VERSION ""

NS_ :

BS_:

BU_: CHUD_LS VKM_LS RCRM_LS MSM_RR_LS MSM_LR_LS CGM_LS BSM_LS VPM_LS ISRVM_LS DCAC_LS TouchPad_LS RSC_LS LVMPC_LS EOCM2B_K1_LS EOCM2A_K1_LS LCM_LS TIM_B_LS V2V_LS TCP_LS CSM_LS EOCM2B_K2_LS EOCM2A_K2_LS TIM_A_LS LVMNav_LS HFP_LS EDI_LS ARB_LS RSE_LS Dummy_LS VIS2_LS ICS_LS FCM_LS EOCM_F_LS VICM_LS AGC_LS MSM_P_LS OTIM_LS HVSM_R_LS HVSM_F_LS DVB_T_LS SBZA_R_LS PSD_R_LS PSD_L_LS UHP_Low UPA_LS STC_LS SBZA_L_LS PTM_LS ONSTAR_LS APA_LS TestTool_LS PHS_LS PDIM_LS CHM_LS RSA_LS AMP_LS HUD_LS MSM_LS HBSM_LS SCL_LS ECC_LS RadioHead_LS PEPS_LS IPC_LS AOS_LS SDM_LS TIM_LS BCM_LS
VAL_TABLE_ vt_BooleanValues 1 "true" 0 "false" ;
VAL_TABLE_ CrgBdVwLtCustSetReq 3 "Unused and Reserved" 2 "On" 1 "Off" 0 "No Action" ;
VAL_TABLE_ CrgBdVwLtCustSetVal 3 "Unused and Reserved" 2 "On" 1 "Off" 0 "Unknown" ;
VAL_TABLE_ TrlrMirVGlnCustSetReq 3 "Unused and Reserved" 2 "On" 1 "Off" 0 "No Action" ;
VAL_TABLE_ TrlrMirVGlnCustSetVal 3 "Unused and Reserved" 2 "On" 1 "Off" 0 "Unknown" ;
VAL_TABLE_ TrlrMirVEnCustSetReq 3 "Unused and Reserved" 2 "On" 1 "Off" 0 "No Action" ;
VAL_TABLE_ TrlrMirVEnCustSetVal 3 "Unused and Reserved" 2 "On" 1 "Off" 0 "Unknown" ;
VAL_TABLE_ EngAftrRnIndReq 7 "Unused and Reserved 3" 6 "Unused and Reserved 2" 5 "Unused and Reserved 1" 4 "Interrupted" 3 "Overheated" 2 "Idle Needed" 1 "No Indication" 0 "No Action" ;
VAL_TABLE_ TireRRIPrsStat 5 "High" 4 "Low Extended Mobility" 3 "Low" 2 "Low Service Now" 1 "Nominal" 0 "Unknown" ;
VAL_TABLE_ TireLRIPrsStat 5 "High" 4 "Low Extended Mobility" 3 "Low" 2 "Low Service Now" 1 "Nominal" 0 "Unknown" ;
VAL_TABLE_ PrkHtrOffTmM 1 "Use Data" 0 "Dont Use Data" ;
VAL_TABLE_ PrkHtrCoolntTempMsk 1 "Use Data" 0 "Don't Use Data" ;
VAL_TABLE_ PrkHtrActvTmM 1 "Use Data" 0 "Dont Use Data" ;
VAL_TABLE_ EmrgncyRspSysTyp 7 "Ununsed and Reserved 1" 6 "Generic" 5 "ERA" 4 "ChevyStar" 3 "eCall" 2 "Onstar" 1 "None" 0 "Unknown" ;
VAL_TABLE_ OBHVDCCCpltnTmDspFrmt 3 "Ununsed and Reserved 1" 2 "Display Remaining Minutes To Complete" 1 "Display Completion Time" 0 "No Action" ;
VAL_TABLE_ EleRngEstAdjStat 3 "Ununsed and Reserved 1" 2 "Decrease" 1 "Increase" 0 "No Action" ;
VAL_TABLE_ EleRngEstAdjCstStReq 3 "Unused and Reserved 1" 2 "On" 1 "Off" 0 "No Action" ;
VAL_TABLE_ EleRngEstAdjCstCurrStVal 3 "Unused and Reserved 1" 2 "On" 1 "Off" 0 "No Action" ;
VAL_TABLE_ WPRSCstStReq 7 "Unused and Reserved 5" 6 "Unused and Reserved 4" 5 "Unused and Reserved 3" 4 "Unused and Reserved 2" 3 "Unused and Reserved 1" 2 "On" 1 "Off" 0 "No Action" ;
VAL_TABLE_ WPRSCstCurrStVal 7 "Unused and Reserved 5" 6 "Unused and Reserved 4" 5 "Unused and Reserved 3" 4 "Unused and Reserved 2" 3 "Unused and Reserved 1" 2 "On" 1 "Off" 0 "No Action" ;
VAL_TABLE_ CntStckHMIRdy 3 "Unused and Reserved 1" 2 "HMI Not Ready" 1 "HMI Ready" 0 "No Action" ;
VAL_TABLE_ SrvcHghVltBatIndReq 3 "Unused and Reserved 1" 2 "No Restart" 1 "Shut Down Soon" 0 "No Indication" ;
VAL_TABLE_ CSRCR_Cmnd 7 "Unused And Reserved 5" 6 "Unused And Reserved 4" 5 "Unused And Reserved 3" 4 "Unused And Reserved 2" 3 "Unused And Reserved 1" 2 "Revoke All Certificates" 1 "Revoke Certificate" 0 "No Action" ;
VAL_TABLE_ CrShrngFbsEnblStat 3 "Fail" 2 "Enabled" 1 "Disabled" 0 "No Action" ;
VAL_TABLE_ CrShrngFbsEnblReq 7 "Unused And Reserved 5" 6 "Unused And Reserved 4" 5 "Unused And Reserved 3" 4 "Unused And Reserved 2" 3 "Return Status" 2 "Unused And Reserved 1" 1 "Disable Fobs" 0 "No Action" ;
VAL_TABLE_ CSPS_ConnStat 15 "Reject All Certificates" 14 "Incorrect Fleet ID" 13 "Send Intermediate Certificate" 12 "Send User Certificate" 11 "Send all Authentication Data" 10 "Invalid VIN" 9 "Intermediate Certificate Expired" 8 "Invalid Intermediate Certificate" 7 "Resrvation End Time Exceeded " 6 "Resrvtion Start Tim Not Achieved" 5 "Cert Revoked Via Mobile Device" 4 "Cert Revoked Via Telematics" 3 "Certificate Expired" 2 "Invalid Certificate" 1 "Valid Certificate" 0 "No Action" ;
VAL_TABLE_ CSPS_RspVerf 4 "Command Response Verification Not Successful" 3 "Command Response Verification Successful" 2 "Zone Response Verification Not Successful" 1 "Zone Response Verification Successful" 0 "No Action" ;
VAL_TABLE_ CrShrngVehChlngReq 1 "Request New  Challenge" 0 "No Action" ;
VAL_TABLE_ CrShrngRvkCertfctRsp 4 "No CertIDs Stored" 3 "CertID Not Matched" 2 "Revoke Certificate Successful" 1 "Write Failure" 0 "No Action" ;
VAL_TABLE_ CSZS_FrntCmptZnMbDevStat 1 "One Or More Mobile Devices Prsnt" 0 "No Mobile Device Present" ;
VAL_TABLE_ CSZS_RrCmptZnMbDevStat 1 "One Or More Mobile Devices Prsnt" 0 "No Mobile Device Present" ;
VAL_TABLE_ CSZS_FrntExtrZnMbDevStat 1 "One Or More Mobile Devices Prsnt" 0 "No Mobile Device Present" ;
VAL_TABLE_ CSZS_RrExtrZnMbDevStat 1 "One Or More Mobile Devices Prsnt" 0 "No Mobile Device Present" ;
VAL_TABLE_ CSZS_WlcmZnMbDevStat 1 "One Or More Mobile Devices Prsnt" 0 "No Mobile Device Present" ;
VAL_TABLE_ CSZS_IntrZnMbDevStat 3 "Three Mobile Devices Present" 2 "Two Mobile Devices Present" 1 "One Mobile Device Present" 0 "No Mobile Device Present" ;
VAL_TABLE_ CSZS_PassEntyZnMbDevStat 1 "One Or More Mobile Devices Prsnt" 0 "No Mobile Device Present" ;
VAL_TABLE_ CSZS_DrEntyZnMbDevStat 1 "One Or More Mobile Devices Prsnt" 0 "No Mobile Device Present" ;
VAL_TABLE_ CrShrngConnStat 3 "Terminate Connection" 2 "Ignore Connection" 1 "Valid Connection" 0 "No Action" ;
VAL_TABLE_ TrlrPrfDltn 5 "Profile 5 Deleted" 4 "Profile 4 Deleted" 3 "Profile 3 Deleted" 2 "Profile 2 Deleted" 1 "Profile 1 Deleted" 0 "No Profile Deleted" ;
VAL_TABLE_ TrlrProfSel 5 "Profile 5" 4 "Profile 4" 3 "Profile 3" 2 "Profile 2" 1 "Profile 1" 0 "Default Profile" ;
VAL_TABLE_ CrwlModeDndRsnIndReq 4 "Reduce Speed" 3 "Shift To 4 High" 2 "Brakes Overtemp" 1 "Unavailable" 0 "No Action" ;
VAL_TABLE_ TrlrLtngSeqStat 1 "On" 0 "Off" ;
VAL_TABLE_ TrlrLtngSeqReq 2 "On" 1 "Off" 0 "No Action" ;
VAL_TABLE_ RmtTrlrLtngSeqReq 2 "On" 1 "Off" 0 "No Action" ;
VAL_TABLE_ TrlrConnStat 1 "Connected" 0 "Not Connected" ;
VAL_TABLE_ ClmCntPrtyHtngRq 3 "HIGH" 2 "MEDIUM" 1 "LOW" 0 "NO ACTION" ;
VAL_TABLE_ RSIHMIAnmSt 7 "Unused and Reserved 3" 6 "Unused and Reserved 2" 5 "Unused and Reserved 1" 4 "Shutdown Play" 3 "Start Play" 2 "Welcome Play" 1 "Ready" 0 "Uninitialized" ;
VAL_TABLE_ RSIHMIAnmReq 7 "Unused and Reserved 3" 6 "Unused and Reserved 2" 5 "Unused and Reserved 1" 4 "Shutdown Play" 3 "Start Play" 2 "Welcome Play" 1 "Ready" 0 "Uninitialized" ;
VAL_TABLE_ EUSD_MsrmntUnit 3 "Unused and Reserved 1" 2 "Unitless Score" 1 "km" 0 "No Action" ;
VAL_TABLE_ AxlLcksVDA 1 "Virtual Device Available" 0 "Virtual Device Unavailable" ;
VAL_TABLE_ AxlLckUnavailIndReq 7 "Unused And Reserved 2" 6 "Unused And Reserved 1" 5 "Generic Unavailable" 4 "Not During Hill Decent" 3 "Speed Too High" 2 "Not In 4 WD Low" 1 "Rear Axle Not Locked" 0 "No Action" ;
VAL_TABLE_ HVBHmChrgTmDspStat 4 "Display Master Setting" 3 "Display Both Cord and Station" 2 "Display Charge Station Charge Value" 1 "Display Portable Cord Charge Value" 0 "No Action" ;
VAL_TABLE_ HVBHmChrgTmDspReq 4 "Display Master Setting" 3 "Display Both Cord and Station" 2 "Display Charge Station Charge Value" 1 "Display Portable Cord Charge Value" 0 "No Action" ;
VAL_TABLE_ HVBChrgTmDspStat 3 "Display Both Cord and Station" 2 "Display Charge Station Charge Value" 1 "Display Portable Cord Charge Value" 0 "No Action" ;
VAL_TABLE_ HVBChrgTmDspReq 3 "Display Both Cord and Station" 2 "Display Charge Station Charge Value" 1 "Display Portable Cord Charge Value" 0 "No Action" ;
VAL_TABLE_ HVBChrgOvrdBtnDspStat 2 "Do Not Display Charge Override Button" 1 "Display Charge Override Button" 0 "No Action" ;
VAL_TABLE_ HVBChrgOvrdBtnDspReq 2 "Do Not Display Charge Override Button" 1 "Display Charge Override Button" 0 "No Action" ;
VAL_TABLE_ HVBChrgLmtBtnDspStat 2 "Do Not Disp Charge Limit Button" 1 "Display Charge Limit Button" 0 "No Action" ;
VAL_TABLE_ HVBChrgLmtBtnDspReq 2 "Do Not Display Charge Limit Button" 1 "Display Charge Limit Button" 0 "No Action" ;
VAL_TABLE_ InstnsFlEcnHybOvrdReq 7 "Unused and Reserved 3" 6 "Unused and Reserved 2" 5 "Unused and Reserved 1" 4 "EV" 3 "Auto Stop" 2 "Max Fuel Economy" 1 "Min Fuel Economy" 0 "No Action" ;
VAL_TABLE_ FourWhlDrvIdReqExtRng 15 "Front Wheel Drive Mode Active" 14 "Front Wheel Drive Mode Pending" 13 "AWD Connected Mode Active" 12 "AWD Connected Mode Pending" 11 "Position Undetermined Active" 10 "Transfer Case Neutral Active" 9 "Transfer Case Neutral Pending" 8 "Four Wheel Drive Low Lock Active" 7 "Four Wheel Drive Low Lock Pending" 6 "Four Wheel Drive High Lock Active" 5 "Four Wheel Drive High Lock Pending" 4 "Four Wheel Drive High Auto Active" 3 "Four Wheel Drive High Auto Pending" 2 "Two Wheel Drive High Active" 1 "Two Wheel Drive High Pending" 0 "No Indication" ;
VAL_TABLE_ BrkPdLfSysDrvrRq 4 "Reset Rear" 3 "Reset Front" 2 "Enable" 1 "Disable" 0 "No Action" ;
VAL_TABLE_ BrkPdLfStatIndRq 5 "Service" 4 "Disabled" 3 "Change Now" 2 "Change Soon" 1 "Ok" 0 "Not Present" ;
VAL_TABLE_ BrkPdLfRrDstWrnIndRq 2 "Display Distance" 1 "Low" 0 "No Action" ;
VAL_TABLE_ BrkPdLfFrtDstWrnIndRq 2 "Display Distance" 1 "Low" 0 "No Action" ;
VAL_TABLE_ HVBatStrtTmDspFrmt 4 "Display Start Time On Cord And Station" 3 "Display Now On Cord And Station" 2 "Display Now On Station Only" 1 "Display Now On Cord Only" 0 "No Action" ;
VAL_TABLE_ SurdVwLightgCsSetReq 7 "Unused and Reserved 5" 6 "Unused and Reserved 4" 5 "Unused and Reserved 3" 4 "Unused and Reserved 2" 3 "Unused and Reserved 1" 2 "ON" 1 "OFF" 0 "No Action" ;
VAL_TABLE_ SurdVwLightgCsCurrSetVal 7 "Unused and Reserved 5" 6 "Unused and Reserved 4" 5 "Unused and Reserved 3" 4 "Unused and Reserved 2" 3 "Unused and Reserved 1" 2 "ON" 1 "OFF" 0 "No Action" ;
VAL_TABLE_ TODCTmpImdtOvrdReq 2 "Active" 1 "Inactive" 0 "No Action" ;
VAL_TABLE_ EngAirFltMonSt 7 "Unused and Reserved 3" 6 "Unused and Reserved 2" 5 "Unused and Reserved 1" 4 "Disabled" 3 "Fault Present" 2 "Replace Air Filter Now" 1 "Replace Air Filter Soon" 0 "Ok" ;
VAL_TABLE_ EngAirFltMonDrvrReq 3 "Reset" 2 "Disable" 1 "Enable" 0 "No Action" ;
VAL_TABLE_ RmClmCtrlSyncSetReq 2 "Dual Zone Climate Control" 1 "Single Zone Climate Control" 0 "No Action" ;
VAL_TABLE_ RmClmCtrlRtSTempStReq 38 "14 CELCIUS" 37 "14.5 CELCIUS" 36 "15 CELCIUS" 35 "15.5 CELCIUS" 34 "16 CELCIUS" 33 "HI" 32 "LO" 31 "31.5 CELCIUS" 30 "31 CELCIUS" 29 "30.5 CELCIUS" 28 "30 CELCIUS" 27 "29.5 CELCIUS" 26 "29 CELCIUS" 25 "28.5 CELCIUS" 24 "28 CELCIUS" 23 "27.5 CELCIUS" 22 "27 CELCIUS" 21 "26.5 CELCIUS" 20 "26 CELCIUS" 19 "25.5 CELCIUS" 18 "25 CELCIUS" 17 "24.5 CELCIUS" 16 "24 CELCIUS" 15 "23.5 CELCIUS" 14 "23 CELCIUS" 13 "22.5 CELCIUS" 12 "22 CELCIUS" 11 "21.5 CELCIUS" 10 "21 CELCIUS" 9 "20.5 CELCIUS" 8 "20 CELCIUS" 7 "19.5 CELCIUS" 6 "19 CELCIUS" 5 "18.5 CELCIUS" 4 "18 CELCIUS" 3 "17.5 CELCIUS" 2 "17 CELCIUS" 1 "16.5 CELCIUS" 0 "No Action" ;
VAL_TABLE_ RmClmCtrlRrDfgSetReq 2 "Inactive" 1 "Active" 0 "No Action" ;
VAL_TABLE_ RmClmCtrlRcrcSetReq 4 "Inactive" 3 "Auto Recirculation" 2 "Recirculation" 1 "Fresh" 0 "No Action" ;
VAL_TABLE_ RmClmCtrlLtSTempStReq 38 "14 CELCIUS" 37 "14.5 CELCIUS" 36 "15 CELCIUS" 35 "15.5 CELCIUS" 34 "16 CELCIUS" 33 "HI" 32 "LO" 31 "31.5 CELCIUS" 30 "31 CELCIUS" 29 "30.5 CELCIUS" 28 "30 CELCIUS" 27 "29.5 CELCIUS" 26 "29 CELCIUS" 25 "28.5 CELCIUS" 24 "28 CELCIUS" 23 "27.5 CELCIUS" 22 "27 CELCIUS" 21 "26.5 CELCIUS" 20 "26 CELCIUS" 19 "25.5 CELCIUS" 18 "25 CELCIUS" 17 "24.5 CELCIUS" 16 "24 CELCIUS" 15 "23.5 CELCIUS" 14 "23 CELCIUS" 13 "22.5 CELCIUS" 12 "22 CELCIUS" 11 "21.5 CELCIUS" 10 "21 CELCIUS" 9 "20.5 CELCIUS" 8 "20 CELCIUS" 7 "19.5 CELCIUS" 6 "19 CELCIUS" 5 "18.5 CELCIUS" 4 "18 CELCIUS" 3 "17.5 CELCIUS" 2 "17 CELCIUS" 1 "16.5 CELCIUS" 0 "No Action" ;
VAL_TABLE_ RmClmCtrlHMIActIndReq 1 "Active" 0 "Inactive" ;
VAL_TABLE_ RmClmCtrlFrntFanStReq 20 "AUTO" 19 "MAN 18" 18 "MAN 17" 17 "MAN 16" 16 "MAN 15" 15 "MAN 14" 14 "MAN 13" 13 "MAN 12" 12 "MAN 11" 11 "MAN 10" 10 "MAN 9" 9 "MAN 8" 8 "MAN 7" 7 "MAN 6" 6 "MAN 5" 5 "MAN 4" 4 "MAN 3" 3 "MAN 2" 2 "MAN 1" 1 "OFF" 0 "No Action" ;
VAL_TABLE_ RmClmCtrlFLAirDtStReq 15 "E TRI LEVEL" 14 "E PANEL" 13 "E DEFOG" 12 "E DEDFROST" 11 "TRI LEVEL" 10 "DEFOG" 9 "ECO" 8 "PURGE" 7 "AC" 6 "BI LEVEL" 5 "HEATER DEFROST" 4 "HEATER" 3 "DEFROST" 2 "AUTO" 1 "OFF" 0 "No Action" ;
VAL_TABLE_ RmClmCtrlClmModSetReq 8 "Comfort Heat" 7 "Comfort AC" 6 "Battery AC On" 5 "Auto" 4 "Active" 3 "Fan Only" 2 "Economy" 1 "Comfort" 0 "No Action" ;
VAL_TABLE_ RmClmCtrlACSetReq 6 "Battery AC On" 5 "ECO AC on" 4 "Comfort AC On" 3 "Auto AC On" 2 "Active" 1 "Inactive" 0 "No Action" ;
VAL_TABLE_ TnrFrqBndReq 15 "Unused and Reserved10" 14 "Unused and Reserved9" 13 "Unused and Reserved8" 12 "Unused and Reserved7" 11 "Unused and Reserved6" 10 "Unused and Reserved5" 9 "Unused and Reserved4" 8 "Unused and Reserved3" 7 "Unused and Reserved2" 6 "Unused and Reserved1" 5 "XM" 4 "DAB" 3 "FM" 2 "AM" 1 "Off" 0 "No Action" ;
VAL_TABLE_ AudSelctdSrcReq 31 "Unused and Reserved14" 30 "Unused and Reserved13" 29 "Unused and Reserved12" 28 "Unused and Reserved11" 27 "Unused and Reserved10" 26 "Unused and Reserved9" 25 "Unused and Reserved8" 24 "Unused and Reserved7" 23 "Unused and Reserved6" 22 "Unused and Reserved5" 21 "Unused and Reserved4" 20 "Unused and Reserved3" 19 "Unused and Reserved2" 18 "Unused and Reserved1" 17 "Android Auto" 16 "Apple CarPlay" 15 "SD" 14 "USB" 13 "RSI2" 12 "RSI1" 11 "Internet App Audio" 10 "LVM Stereo Audio" 9 "Audio Disk Player" 8 "AUX" 7 "Bluetooth" 6 "IPOD" 5 "MediaPlayer" 4 "DAB" 3 "XM" 2 "FM" 1 "AM" 0 "No Action" ;
VAL_TABLE_ FuelMdTrnstnIndReq 15 "Unused and Reserved 9" 14 "Unused and Reserved 8" 13 "Unused and Reserved 7" 12 "Unused and Reserved 6" 11 "Unused and Reserved 5" 10 "Unused and Reserved 4" 9 "Unused and Reserved 3" 8 "Unused and Reserved 2" 7 "Unused and Reserved 1" 6 "Indication 6" 5 "Indication 5" 4 "Indication 4" 3 "Indication 3" 2 "Indication 2" 1 "Indication 1" 0 "No Indication" ;
VAL_TABLE_ BiFuelRflGaslinIndReq 7 "Unused and Reserved 5" 6 "Unused and Reserved 4" 5 "Unused and Reserved 3" 4 "Unused and Reserved 2" 3 "Unused and Reserved 1" 2 "Indication 2" 1 "Indication 1" 0 "No Indication" ;
VAL_TABLE_ HtdFrntWSSt 1 "ON" 0 "OFF" ;
VAL_TABLE_ HtdFrntWSDispReq 2 "OFF" 1 "ON" 0 "No Action" ;
VAL_TABLE_ AutoThrmlStPassMdStRq 3 "Vent Cool" 2 "Back Only Heat" 1 "Seat Heat" 0 "OFF" ;
VAL_TABLE_ AutoThrmlStPasLvlStRq 5 "Level 5" 4 "Level 4" 3 "Level 3" 2 "Level 2" 1 "Level 1" 0 "OFF" ;
VAL_TABLE_ AutoThrmlStDrvMdStRq 3 "Vent Cool" 2 "Back Only Heat" 1 "Seat Heat" 0 "OFF" ;
VAL_TABLE_ AutoThrmlStDrvLvStRq 5 "Level 5" 4 "Level 4" 3 "Level 3" 2 "Level 2" 1 "Level 1" 0 "OFF" ;
VAL_TABLE_ RunBrdOpMdCstStReq 7 "Unused and Reserved 4" 6 "Unused and Reserved 3" 5 "Unused and Reserved 2" 4 "Unused and Reserved 1" 3 "Extended" 2 "On" 1 "Off" 0 "No Action" ;
VAL_TABLE_ RunBrdOpMdCstCurrStVal 7 "Unused and Reserved 4" 6 "Unused and Reserved 3" 5 "Unused and Reserved 2" 4 "Unused and Reserved 1" 3 "Extended" 2 "On" 1 "Off" 0 "No Action" ;
VAL_TABLE_ StTODChrgTmpOvrdRmt1 2 "Active" 1 "Inactive" 0 "No Action" ;
VAL_TABLE_ SmPhRmFunCstStReq 7 "Unused and Reserved 5" 6 "Unused and Reserved 4" 5 "Unused and Reserved 3" 4 "Unused and Reserved 2" 3 "Unused and Reserved 1" 2 "On" 1 "Off" 0 "No Action" ;
VAL_TABLE_ SmPhRmFunCstCurStVal 7 "Unused and Reserved 5" 6 "Unused and Reserved 4" 5 "Unused and Reserved 3" 4 "Unused and Reserved 2" 3 "Unused and Reserved 1" 2 "On" 1 "Off" 0 "No Action" ;
VAL_TABLE_ PrtyChrgRqRmt1 2 "Active" 1 "Inactive" 0 "No Action" ;
VAL_TABLE_ HVChgSyChgLvPfStRmt1 4 "Reduced Current Level 3" 3 "Reduced Current Level 2" 2 "Reduced Current Level 1" 1 "No Reduction" 0 "No Action" ;
VAL_TABLE_ HVBTBDCSRR1_DChSnSRq 3 "Yearly" 2 "Winter" 1 "Summer" 0 "No Action" ;
VAL_TABLE_ HVBTBDCSRR1_DChSlSRq 8 "Unused and Reserved 4" 7 "Departure Time 2 Invalid" 6 "Unused and Reserved 3" 5 "Departure Time 2" 4 "Unused and Reserved 2" 3 "Departure Time 1 Invalid" 2 "Unused and Reserved 1" 1 "Departure Time 1" 0 "No Action" ;
VAL_TABLE_ HVBTBDCSRR1_DChDStRq 10 "Sat and Sun Same" 9 "Mon To Fri Same" 8 "All Days Same" 7 "Saturday" 6 "Friday" 5 "Thursday" 4 "Wednsday" 3 "Tuesday" 2 "Monday" 1 "Sunday" 0 "No Action" ;
VAL_TABLE_ HVBatTmBsChgMdRqRmt1 3 "Rate Based Charge" 2 "Delayed Charge" 1 "Charge Now" 0 "No Action" ;
VAL_TABLE_ HtdStWhlInd 3 "High" 2 "Medium" 1 "Low" 0 "Off" ;
VAL_TABLE_ HtdStWhlCtrlSrc 1 "Remote Switch Control" 0 "Local Switch Control" ;
VAL_TABLE_ HtdStWhlCmd 3 "High" 2 "Medium" 1 "Low" 0 "Off" ;
VAL_TABLE_ SmrtHgBmAstCstSetReq 7 "Unused and Reserved 5" 6 "Unused and Reserved 4" 5 "Unused and Reserved 3" 4 "Unused and Reserved 2" 3 "Unused and Reserved 1" 2 "Adaptive High Beam" 1 "Auto High Beam" 0 "No Action" ;
VAL_TABLE_ SmrtHgBmAstCstCurrSetVal 7 "Unused and Reserved 5" 6 "Unused and Reserved 4" 5 "Unused and Reserved 3" 4 "Unused and Reserved 2" 3 "Unused and Reserved 1" 2 "Adaptive High Beam" 1 "Auto High Beam" 0 "No Action" ;
VAL_TABLE_ V2VTLI_TrfLghtMntngDirctn 1 "Horizontal" 0 "Vertical" ;
VAL_TABLE_ V2VTLI_TrfLghtValDirctn 3 "All direction" 2 "Right" 1 "Left" 0 "Straight" ;
VAL_TABLE_ V2VTLI_TrfLghtPhsArivl 3 "Unknown Phase" 2 "Yellow" 1 "Green" 0 "Red" ;
VAL_TABLE_ V2VTLI_TrfLghtActlPhs 3 "Unknown Phase" 2 "Yellow" 1 "Green" 0 "Red" ;
VAL_TABLE_ RrStRmndrCstSetReq 2 "On" 1 "Off" 0 "No Action" ;
VAL_TABLE_ RrStRmndrCstCurrSetVal 2 "On" 1 "Off" 0 "No Action" ;
VAL_TABLE_ ElcShfPriTwoGrsSlInRq 3 "Drive Indication" 2 "Neutral Indication" 1 "Park Indication" 0 "No Indication" ;
VAL_TABLE_ VehStbEnhmntCurStRq 2 "On" 1 "Off" 0 "No Action" ;
VAL_TABLE_ VehStbEnhmntCurSt 1 "On" 0 "Off" ;
VAL_TABLE_ VehStbCmptvMdCurStRq 2 "On" 1 "Off" 0 "No Action" ;
VAL_TABLE_ VehStbCmptvMdCurSt 1 "On" 0 "Off" ;
VAL_TABLE_ TracAndStbScrnCnfg 3 "TCS ESC and Comp" 2 "TCS and ESC" 1 "TCS Only" 0 "None" ;
VAL_TABLE_ TCSysCurStReq 2 "On" 1 "Off" 0 "No Action" ;
VAL_TABLE_ TCSysCurSt 1 "On" 0 "Off" ;
VAL_TABLE_ TCSTmpSysDsblReqConf 2 "Yes" 1 "No" 0 "No Action" ;
VAL_TABLE_ LnMrkngIndRgt 3 "Unused and Reserved 1" 2 "Green Indicator" 1 "White Indicator" 0 "Indicator Off" ;
VAL_TABLE_ LnMrkngIndLft 3 "Unused and Reserved 1" 2 "Green Indicator" 1 "White Indicator" 0 "Indicator Off" ;
VAL_TABLE_ LnKepAsstStIndRgt 7 "Unused and Reserved 2" 6 "Unused and Reserved 1" 5 "Yellow Indicator" 4 "Red Indicator" 3 "Blue Indicator" 2 "Green Indicator" 1 "White Indicator" 0 "Indicator Off" ;
VAL_TABLE_ LnKepAsstStIndLft 7 "Unused and Reserved 2" 6 "Unused and Reserved 1" 5 "Yellow Indicator" 4 "Red Indicator" 3 "Blue Indicator" 2 "Green Indicator" 1 "White Indicator" 0 "Indicator Off" ;
VAL_TABLE_ LnKpngAstRecfblIndRq 7 "Unused and Reserved 2" 6 "Unused and Reserved 1" 5 "Yellow Solid Indicator" 4 "Yellow Flashing Indicator" 3 "Blue Solid Indicator" 2 "Green Solid Indicator" 1 "White Solid Indicator" 0 "Indicator Off" ;
VAL_TABLE_ InfotnBkltngConfigSt 2 "LOCAL" 1 "ON" 0 "OFF" ;
VAL_TABLE_ WSMR_WiFiAssnReq 3 "Unexpected Undefined Connection Behavior" 2 "Wi Fi association failed with available credentials" 1 "Failed to receive Wi Fi credentials after 255 attempts" 0 "SSID and Passphrase Request" ;
VAL_TABLE_ UlckKyStrCrptoDt2M 1 "Use Data" 0 "Dont Use Data" ;
VAL_TABLE_ UlckKyStrCrptoDt1M 1 "Use Data" 0 "Dont Use Data" ;
VAL_TABLE_ OBTCR_Stat 3 "Revoked" 2 "Denied" 1 "Accepted" 0 "No Action" ;
VAL_TABLE_ OBTCReqstrStat 3 "Off Board Tester Present" 2 "Active" 1 "Inactive" 0 "Unknown" ;
VAL_TABLE_ OBTCMstrStat 3 "Off Board Tester Present" 2 "Active" 1 "Inactive" 0 "Unknown" ;
VAL_TABLE_ LnCntrSpchPrmtReq 3 "Unused and Reserved" 2 "Take Vehicle Control" 1 "Take Steering" 0 "No Prompt" ;
VAL_TABLE_ LnCntrEsclnStat 3 "System Faulted" 2 "Limit Condition" 1 "Driver Not Looking to Roadway" 0 "None" ;
VAL_TABLE_ HLOCCstSetReq 3 "On Open Only" 2 "On" 1 "Off" 0 "No Action" ;
VAL_TABLE_ HLOCCstCurrSetVal 3 "On Open Only" 2 "On" 1 "Off" 0 "No Action" ;
VAL_TABLE_ PsngrSetRrwdMvmnt 7 "Supervised Seat Recline Rearward" 6 "Supervised Seat Rear Down" 5 "Supervised Seat Rearward" 4 "Button Memory 1 and 2 EXIT Recall" 3 "Supervised Memory Recall" 2 "Auto Easy Exit Recall" 1 "Auto Recall At Ignition On" 0 "No Auto Or Rearward Movement" ;
VAL_TABLE_ DrvrSetRrwrdMvmnt 7 "Supervised Seat Recline Rearward" 6 "Supervised Seat Rear Down" 5 "Supervised Seat Rearward" 4 "Button Memory 1 and 2 EXIT Recall" 3 "Supervised Memory Recall" 2 "Auto Easy Exit Recall" 1 "Auto Recall At Ignition On" 0 "No Auto Or Rearward Movement" ;
VAL_TABLE_ StrgColCommsFlt 2 "Disabled Communications DTC" 1 "No Communications Fault" 0 "Communications Fault" ;
VAL_TABLE_ CPMAPINFO4 1 "Hardware Or Software Error" 0 "No Hardware Or Software Error" ;
VAL_TABLE_ HTRCsStReq 4 "On Away" 3 "On Home" 2 "On" 1 "Off" 0 "No Action" ;
VAL_TABLE_ HTRCsCrStVal 4 "On Away" 3 "On Home" 2 "On" 1 "Off" 0 "No Action" ;
VAL_TABLE_ OPDWrnIndReq 4 "Forced Exit" 3 "Unavailable" 2 "Off" 1 "On" 0 "No Indication" ;
VAL_TABLE_ TrlrArtcltnAnglCalStat 3 "Unavailable" 2 "Degraded" 1 "Available" 0 "Unknown" ;
VAL_TABLE_ TnDrvStBltShftIntrlkCrStVal 2 "On" 1 "Off" 0 "No Action" ;
VAL_TABLE_ TnDrvStBltShftIntrlkCsStRq 2 "On" 1 "Off" 0 "No Action" ;
VAL_TABLE_ StBltShftIntrlkCsCrStVal 2 "On" 1 "Off" 0 "No Action" ;
VAL_TABLE_ StBltShftIntrlkCsStRq 2 "On" 1 "Off" 0 "No Action" ;
VAL_TABLE_ Aux2CamConnStat 0 "Not Connected" 2 "Unknown" 1 "Connected" ;
VAL_TABLE_ Aux1CamConnStat 2 "Unknown" 1 "Connected" 0 "Not Connected" ;
VAL_TABLE_ InvTrlrOpnlStat 3 "Unavailable" 2 "Degraded" 1 "Available" 0 "Unknown" ;
VAL_TABLE_ TrlrAxlCnt 3 "3" 2 "2" 1 "1" 0 "Unknown" ;
VAL_TABLE_ TrlrHtchTyp 3 "Gooseneck" 2 "5th Wheel" 1 "Conventional" 0 "Unknown" ;
VAL_TABLE_ TrlrTyp 2 "Not Box" 1 "Box" 0 "Unknown" ;
VAL_TABLE_ JacknfDetCustSetReq 3 "Unused and Reserved" 2 "On" 1 "Off" 0 "No Action" ;
VAL_TABLE_ JacknfDetCustSetVal 3 "Unused and Reserved" 2 "On" 1 "Off" 0 "Unknown" ;
VAL_TABLE_ V2VSrvIndReq 3 "Unused and Reserved2" 2 "Unused and Reserved1" 1 "Service V2V System" 0 "No Indication" ;
VAL_TABLE_ ElcTransRngSlctVDA 1 "Virtual Device Available" 0 "Virtual Device Unavailable" ;
VAL_TABLE_ ACCSysSltdMd 3 "Unused And Reserved" 2 "Enhanced Cruise Control" 1 "Adaptive Cruise Control" 0 "Cruise Control Mode Switching Not Supported" ;
VAL_TABLE_ EngyUsgScrnMeasUtStat 15 "Unused and Reserved 9" 14 "Unused and Reserved 8" 13 "Unused and Reserved 7" 12 "Unused and Reserved 6" 11 "Unused and Reserved 5" 10 "Unused and Reserved 4" 9 "Unused and Reserved 3" 8 "Unused and Reserved 2" 7 "Unused and Reserved 1" 6 "km/L e Combined" 5 "km/L" 4 "L/100km e Combined" 3 "L/100km" 2 "MPGe Combined" 1 "MPG" 0 "No Action" ;
VAL_TABLE_ OBHVBCCompTmDispFrmt 2 "Display Remaining Minutes To Complete" 1 "Display Completion Time" 0 "No Action" ;
VAL_TABLE_ TAR_AudSrcStat 15 "Unused And Reserved 11" 14 "Unused And Reserved 10" 13 "Unused And Reserved 9" 12 "Unused And Reserved 8" 11 "Unused And Reserved 7" 10 "Unused And Reserved 6" 9 "Unused And Reserved 5" 8 "Unused And Reserved 4" 7 "Unused And Reserved 3" 6 "Unused And Reserved 2" 5 "Unused And Reserved 1" 4 "Audio Disconnect" 3 "Audio Request" 2 "Audio Playing" 1 "Audio Ready" 0 "No Action" ;
VAL_TABLE_ TAR_AudConctReq 13 "Unused And Reserved 8" 12 "Unused And Reserved 7" 11 "Unused And Reserved 6" 10 "Unused And Reserved 5" 9 "Unused And Reserved 4" 8 "Unused And Reserved 3" 7 "Unused And Reserved 2" 6 "Unused And Reserved 1" 5 "Emergency Phone" 4 "Phone" 3 "Ring Tone" 2 "Mutex Prompt" 1 "Mix Prompt" 0 "No Action" 15 "Unused And Reserved 10" 14 "Unused And Reserved 9" ;
VAL_TABLE_ TAC_AudConctOutcm 15 "Unused And Reserved 13" 14 "Unused And Reserved 12" 13 "Unused And Reserved 11" 12 "Unused And Reserved 10" 11 "Unused And Reserved 9" 10 "Unused And Reserved 8" 9 "Unused And Reserved 7" 8 "Unused And Reserved 6" 7 "Unused And Reserved 5" 6 "Unused And Reserved 4" 5 "Unused And Reserved 3" 4 "Unused And Reserved 2" 3 "Unused And Reserved 1" 2 "Request Denied" 1 "Request Granted" 0 "No Action" ;
VAL_TABLE_ TAC_AudChConctStat 15 "Unused And Reserved 10" 14 "Unused And Reserved 9" 13 "Unused And Reserved 8" 12 "Unused And Reserved 7" 11 "Unused And Reserved 6" 10 "Unused And Reserved 5" 9 "Unused And Reserved 4" 8 "Unused And Reserved 3" 7 "Unused And Reserved 2" 6 "Unused And Reserved 1" 5 "Emergency Phone" 4 "Phone" 3 "Ring Tone" 2 "Mutex Prompt" 1 "Mix Prompt" 0 "No Action" ;
VAL_TABLE_ PTExPartFltManRegStat 7 "Do not press pedals" 6 "Not available" 5 "Pending Driver Input" 4 "Complete" 3 "In Progress" 2 "Not Allowed" 1 "Allowed" 0 "Cleaning Not Required" ;
VAL_TABLE_ LVMAVR_SpchRcgnAct 3 "Unused and Reserved 1" 2 "LVM Speech Rec Active" 1 "LVM Speech Rec Ready" 0 "No Action" ;
VAL_TABLE_ LVMAVR_PrmtAudReq 3 "Unused and Reserved 2" 2 "Unused and Reserved 1" 1 "Prompt Request" 0 "No Action" ;
VAL_TABLE_ LVMAVR_StreoAudReq 3 "Unused and Reserved 2" 2 "Unused and Reserved 1" 1 "Stereo Request" 0 "No Action" ;
VAL_TABLE_ LVMAVR_DispReq 7 "Unused and Reserved 4" 6 "Unused and Reserved 3" 5 "Unused and Reserved 2" 4 "Unused and Reserved 1" 3 "LVM PDR" 2 "LVM DMB" 1 "LVM NAV" 0 "No Action" ;
VAL_TABLE_ LVMAVC_SpchRcgnAval 3 "Unused and Reserved 2" 2 "Unused and Reserved 1" 1 "Available" 0 "No Action" ;
VAL_TABLE_ LVMAVC_RemSpchRcgnActn 3 "End Button Press" 2 "PTT Button Press" 1 "Activate LVM_SR" 0 "No Action" ;
VAL_TABLE_ LVMAVC_RemSpchRcgnID 7 "Unused and Reserved 4" 6 "Unused and Reserved 3" 5 "Unused and Reserved 2" 4 "Unused and Reserved 1" 3 "LVM PDR" 2 "LVM DMB" 1 "LVM NAV" 0 "No Action" ;
VAL_TABLE_ LVMAVC_StreoAudRsp 3 "Unused and Reserved 2" 2 "Unused and Reserved 1" 1 "Active" 0 "No Action" ;
VAL_TABLE_ LVMAVC_PrmtAudRsp 3 "Unused and Reserved 2" 2 "Unused and Reserved 1" 1 "Active" 0 "No Action" ;
VAL_TABLE_ LVMAVC_RemtEnbl 7 "Unused and Reserved 5" 6 "Unused and Reserved 4" 5 "Unused and Reserved 3" 4 "Unused and Reserved 2" 3 "Unused and Reserved 1" 2 "Remote Enable Active" 1 "Remote Enable On" 0 "No Action" ;
VAL_TABLE_ InfotnmntSysSt 31 " Unused and Reserved 15" 30 " Unused and Reserved 14" 29 " Unused and Reserved 13" 28 " Unused and Reserved 12" 27 " Unused and Reserved 11" 26 " Unused and Reserved 10" 25 " Unused and Reserved 9" 24 " Unused and Reserved 8" 23 " Unused and Reserved 7" 22 " Unused and Reserved 6" 21 " Unused and Reserved 5" 20 " Unused and Reserved 4" 19 " Unused and Reserved 3" 18 " Unused and Reserved 2" 17 " Unused and Reserved 1" 16 " Remote Reflash Programming" 15 " No VIN" 14 " No Calibration" 13 " Theftlocked" 12 " Valet Mode" 11 " Local Eject" 10 " Local Valet" 9 " Local Phone" 8 " Local Infotainment" 7 " Accessory" 6 " Propulsion" 5 " Run" 4 " Start" 3 " HMI Inactive" 2 " HMI Init" 1 " Animation Init" 0 " Sleep" ;
VAL_TABLE_ ClstrHMIAnmSt 7 "Unused and Reserved 3" 6 "Unused and Reserved 2" 5 "Unused and Reserved 1" 4 "Shutdown Play" 3 "Start Play" 2 "Welcome Play" 1 "Ready" 0 "Uninitialized" ;
VAL_TABLE_ ClstrHMIAnmReq 7 "Unused and Reserved 3" 6 "Unused and Reserved 2" 5 "Unused and Reserved 1" 4 "Shutdown Play" 3 "Start Play" 2 "Welcome Play" 1 "Ready" 0 "No Action" ;
VAL_TABLE_ ASTC_DSPMd 15 "Unused and Reserved 7" 14 "Unused and Reserved 6" 13 "Unused and Reserved 5" 12 "Unused and Reserved 4" 11 "Unused and Reserved 3" 10 "Unused and Reserved 2" 9 "Unused and Reserved 1" 8 "DSP Mode 7" 7 "DSP Mode 6" 6 "DSP Mode 5" 5 "DSP Mode 4" 4 "DSP Mode 3" 3 "DSP Mode 2" 2 "DSP Mode 1" 1 "DSP Mode 0" 0 "No Action" ;
VAL_TABLE_ ASTC_ChimSnkSpkrPos 15 "Unused and Reserved 7" 14 "Unused and Reserved 6" 13 "Unused and Reserved 5" 12 "Unused and Reserved 4" 11 "Unused and Reserved 3" 10 "Unused and Reserved 2" 9 "Unused and Reserved 1" 8 "Left Rear" 7 "Left Front" 6 "Right Rear" 5 "Right Front" 4 "Full Right" 3 "Full Left" 2 "Full Rear" 1 "Full Front" 0 "No Action" ;
VAL_TABLE_ LnchCtrlWhlSlpStat 31 "Unused and Reserved 10" 30 "Unused and Reserved 9" 29 "Unused and Reserved 8" 28 "Unused and Reserved 7" 27 "Unused and Reserved 6" 26 "Unused and Reserved 5" 25 "Unused and Reserved 4" 24 "Unused and Reserved 3" 23 "Unused and Reserved 2" 22 "Unused and Reserved 1" 21 "Fifteen Percent" 20 "Fourteen And A Half Percent" 19 "Fourteen Percent" 18 "Thirteen And A Half Percent" 17 "Thirteen Percent" 16 "Twelve And A Half Percent" 15 "Twelve Percent" 14 "Eleven And a Half Percent" 13 "Eleven Percent" 12 "Ten And A Half Percent" 11 "Ten Percent" 10 "Nine And A Half Percent" 9 "Nine Percent" 8 "Eight And A Half Percent" 7 "Eight Percent" 6 "Seven And A Half Percent" 5 "Seven Percent" 4 "Six And A Half Percent" 3 "Six Percent" 2 "Five And A Half Percent" 1 "Five Percent" 0 "No Action" ;
VAL_TABLE_ LnchCtrlWhlSlpReq 31 "Unused and Reserved 10" 30 "Unused and Reserved 9" 29 "Unused and Reserved 8" 28 "Unused and Reserved 7" 27 "Unused and Reserved 6" 26 "Unused and Reserved 5" 25 "Unused and Reserved 4" 24 "Unused and Reserved 3" 23 "Unused and Reserved 2" 22 "Unused and Reserved 1" 21 "Fifteen Percent" 20 "Fourteen And A Half Percent" 19 "Fourteen Percent" 18 "Thirteen And A Half Percent" 17 "Thirteen Percent" 16 "Twelve And A Half Percent" 15 "Twelve Percent" 14 "Eleven And a Half Percent" 13 "Eleven Percent" 12 "Ten And A Half Percent" 11 "Ten Percent" 10 "Nine And A Half Percent" 9 "Nine Percent" 8 "Eight And A Half Percent" 7 "Eight Percent" 6 "Seven And A Half Percent" 5 "Seven Percent" 4 "Six And A Half Percent" 3 "Six Percent" 2 "Five And A Half Percent" 1 "Five Percent" 0 "No Action" ;
VAL_TABLE_ LnchCtrlMdStat 7 "Line Lock Release Brake" 6 "Line Lock Press Brake" 5 "Burn Out Or Line Lock" 4 "High Traction Custom" 3 "High Traction" 2 "General Custom" 1 "General" 0 "Disable" ;
VAL_TABLE_ LnchCtrlMdReq 3 "Burn Out" 2 "Custom" 1 "Automatic" 0 "No Action" ;
VAL_TABLE_ LnchCtrlEngRPMStat 0 "No Action" 63 "Unused and Reserved 30" 62 "Unused and Reserved 29" 61 "Unused and Reserved 28" 60 "Unused and Reserved 27" 59 "Unused and Reserved 26" 58 "Unused and Reserved 25" 57 "Unused and Reserved 24" 56 "Unused and Reserved 23" 55 "Unused and Reserved 22" 54 "Unused and Reserved 21" 53 "Unused and Reserved 20" 52 "Unused and Reserved 19" 51 "Unused and Reserved 18" 50 "Unused and Reserved 17" 49 "Unused and Reserved 16" 48 "Unused and Reserved 15" 47 "Unused and Reserved 14" 46 "Unused and Reserved 13" 45 "Unused and Reserved 12" 44 "Unused and Reserved 11" 43 "Unused and Reserved 10" 42 "Unused and Reserved 9" 41 "Unused and Reserved 8" 40 "Unused and Reserved 7" 39 "Unused and Reserved 6" 38 "Unused and Reserved 5" 37 "Unused and Reserved 4" 36 "Unused and Reserved 3" 35 "Unused and Reserved 2" 34 "Unused and Reserved 1" 33 "4000" 32 "3900" 31 "3800" 30 "3700" 29 "3600" 28 "3500" 27 "3400" 26 "3300" 25 "3200" 24 "3100" 23 "3000" 22 "2900" 21 "2800" 20 "2700" 19 "2600" 18 "2500" 17 "2400" 16 "2300" 15 "2200" 14 "2100" 13 "2000" 12 "1900" 11 "1800" 10 "1700" 9 "1600" 8 "1500" 7 "1400" 6 "1300" 5 "1200" 4 "1100" 3 "1000" 2 "900" 1 "800" ;
VAL_TABLE_ LnchCtrlEngRPMReq 63 "Unused and Reserved 30" 62 "Unused and Reserved 29" 61 "Unused and Reserved 28" 60 "Unused and Reserved 27" 59 "Unused and Reserved 26" 58 "Unused and Reserved 25" 57 "Unused and Reserved 24" 56 "Unused and Reserved 23" 55 "Unused and Reserved 22" 54 "Unused and Reserved 21" 53 "Unused and Reserved 20" 52 "Unused and Reserved 19" 51 "Unused and Reserved 18" 50 "Unused and Reserved 17" 49 "Unused and Reserved 16" 48 "Unused and Reserved 15" 47 "Unused and Reserved 14" 46 "Unused and Reserved 13" 45 "Unused and Reserved 12" 44 "Unused and Reserved 11" 43 "Unused and Reserved 10" 42 "Unused and Reserved 9" 41 "Unused and Reserved 8" 40 "Unused and Reserved 7" 39 "Unused and Reserved 6" 38 "Unused and Reserved 5" 37 "Unused and Reserved 4" 36 "Unused and Reserved 3" 35 "Unused and Reserved 2" 34 "Unused and Reserved 1" 33 "4000" 32 "3900" 31 "3800" 30 "3700" 29 "3600" 28 "3500" 27 "3400" 26 "3300" 25 "3200" 24 "3100" 23 "3000" 22 "2900" 21 "2800" 20 "2700" 19 "2600" 18 "2500" 17 "2400" 16 "2300" 15 "2200" 14 "2100" 13 "2000" 12 "1900" 11 "1800" 10 "1700" 9 "1600" 8 "1500" 7 "1400" 6 "1300" 5 "1200" 4 "1100" 3 "1000" 2 "900" 1 "800" 0 "No Action" ;
VAL_TABLE_ ECHGCD_XAxTkMrkInterv 7 "100" 6 "80" 5 "50" 4 "20" 3 "10" 2 "5" 1 "1" 0 "0.5" ;
VAL_TABLE_ ECHGCD_MeasUt 15 "Unused and Reserved 7" 14 "Unused and Reserved 6" 13 "Unused and Reserved 5" 12 "Unused and Reserved 4" 11 "Unused and Reserved 3" 10 "Unused and Reserved 2" 9 "Unused and  Reserved 1" 8 "km per L e Combined" 7 "L per 100km e Combined" 6 "MPGe Combined" 5 "L per 100km" 4 "mi per gal" 3 "km per L" 2 "kWh per 100km" 1 "mi per kWh" 0 "km per kWh" ;
VAL_TABLE_ TrfRdsdInfCsStReq 7 "Reserved5" 6 "Reserved4" 5 "Reserved3" 4 "Reserved2" 3 "Reserved1" 2 "On" 1 "Off" 0 "No Action" ;
VAL_TABLE_ TrfRdsdInfCsCrStVal 7 "Reserved5" 6 "Reserved4" 5 "Reserved3" 4 "Reserved2" 3 "Reserved1" 2 "On" 1 "Off" 0 "No Action" ;
VAL_TABLE_ CntdVehBrAltCsStReq 7 "Reserved5" 6 "Reserved4" 5 "Reserved3" 4 "Reserved2" 3 "Reserved1" 2 "On" 1 "Off" 0 "No Action" ;
VAL_TABLE_ CntdVehBrAltCsCrStVal 7 "Reserved5" 6 "Reserved4" 5 "Reserved3" 4 "Reserved2" 3 "Reserved1" 2 "On" 1 "Off" 0 "No Action" ;
VAL_TABLE_ IntrStopAlrtCsSetReq 7 "Reserved4" 6 "Reserved3" 5 "Reserved2" 4 "Reserved1" 3 "Alert and Brake" 2 "Alert " 1 "Off" 0 "No Action" ;
VAL_TABLE_ IntrStAlrtCsCrSetVal 7 "Reserved4" 6 "Reserved3" 5 "Reserved2" 4 "Reserved1" 3 "Alert and Brake" 2 "Alert " 1 "Off" 0 "No Action" ;
VAL_TABLE_ V2VWrngIndReq 31 "Unused And Reserved 15" 30 "Unused And Reserved 14" 29 "Unused And Reserved 13" 28 "Unused And Reserved 12" 27 "Unused And Reserved 11" 26 "Unused And Reserved 10" 25 "Unused And Reserved 9" 24 "Unused And Reserved 8" 23 "Unused And Reserved 7" 22 "Unused And Reserved 6" 21 "Unused And Reserved 5" 20 "Unused And Reserved 4" 19 "Unused And Reserved 3" 18 "Unused And Reserved 2" 17 "Unused And Reserved 1" 16 "Green Light Optimal Speed Advisory" 15 "Intersection Colision Warning Right" 14 "Intersection Colision Warning Left" 13 "Intersection Stop" 12 "Construction Ends" 11 "Construction Starts" 10 "Slowing Traffic" 9 "Crosswinds" 8 "Slippery Road" 7 "Low Visibility" 6 "Heavy Rain" 5 "Sharp  Curve" 4 "Obstacle" 3 "Emergency Vehicle" 2 "Hard Braking" 1 "Hazard Lights" 0 "No Indication" ;
VAL_TABLE_ V2VWrngDirctn 7 "North West" 6 "West" 5 "South West" 4 "South" 3 "South East" 2 "East" 1 "North East" 0 "North" ;
VAL_TABLE_ LCWrnIndReq 25 "Sensor Imparied" 24 "Vehicle Center" 23 "Driver Action" 22 "GPS Unavailable" 21 "Driver Attn Off Road" 20 "Controlled Access" 19 "Adaptive Cruise" 18 "Vehicle Setting" 17 "GM Authority" 16 "Exit Lane" 15 "Lane Ending" 14 "Lane Following Locked Out" 13 "Service Driver Assist System" 12 "Take Vehicle Control" 11 "Take Steering" 10 "Due to Weather" 9 "Attention Unknown" 8 "Unavailable" 7 "Adaptive Cruise Disengaging" 6 "Vehicle Proximity" 5 "Excessive Speed" 4 "Construction" 3 "Freeway Ends" 2 "Tight Curve" 1 "Lane Lines" 0 "No Indication" ;
VAL_TABLE_ LCConvMsgIndreq 31 "Reserved" 30 "Reserved" 29 "Reserved" 28 "Reserved" 27 "Reserved" 26 "Reserved" 25 "Reserved" 24 "Reserved" 23 "Reserved" 22 "Reserved" 21 "Reserved" 20 "Reserved" 19 "Show Fuel Range" 18 "Show Fuel Level" 17 "Take Time to Look at Road" 16 "Road Detour Detected" 15 "Lane Ending Ahead" 14 "Exit Only Lane Ahead" 13 "Road Exit Detected Ahead" 12 "Major Road Interchange Ahead" 11 "Slow Moving Traffic in Right Lane" 10 "Slow Moving Traffic Ahead" 9 "Slow Moving Traffic in Left Lane" 8 "Merging Vehicle" 7 "Heavy Traffic" 6 "Right Blind Spot Occupied" 5 "Left Blind Spot Occupied" 4 "Tailgater Detected" 3 "Being Passed on Right" 2 "Being Passed on Left" 1 "Behind Slow Vehicle" 0 "No Indication" ;
VAL_TABLE_ LCCIndReq 7 "Reserved" 6 "Reserved" 5 "Reserved" 4 "Red Indicator" 3 "Blue Indicator" 2 "Green Indicator" 1 "White Indicator" 0 "Indicator Off" ;
VAL_TABLE_ DgtlMapPsgRstrctn 7 "Unknown Condition" 6 "Conditional When Snow" 5 "Conditional When Wet" 4 "Condtnl Tractors Allowed  Overtake" 3 "Condtnl Passenger Car With Trailer" 2 "LED Signs" 1 "General No Overtake" 0 "No Passing Restrictions" ;
VAL_TABLE_ DgtlMapCndlSpdLmtTyp 5 "Condtnl Speed Limit Only By Rain" 4 "Condtnl Speed Limit By Time Of Day" 3 "Conditional Speed Limit Only By Day" 2 "Condtnl Speed Limit Only By Night" 1 "Conditional Speed Limit Only By Fog" 0 "Condtnl Speed Limit Lane Dependent" 7 "Unknown Conditional Speed Limit" 6 "Condtnl Speed Limit Only By Snow" ;
VAL_TABLE_ DgtlMapCndlSpdLmt 31 "Not Available" 30 "Unlimited" 29 "160 kmh_mph" 28 "150 kmh_mph" 27 "140 kmh_mph" 26 "130 kmh_mph" 25 "120 kmh_mph" 24 "115 kmh_mph" 23 "110 kmh_mph" 22 "105 kmh_mph" 21 "100 kmh_mph" 20 "95 kmh_mph" 19 "90 kmh_mph" 18 "85 kmh_mph" 17 "80 kmh_mph" 16 "75 kmh_mph" 15 "70 kmh_mph" 14 "65 kmh_mph" 13 "60 kmh_mph" 12 "55 kmh_mph" 11 "50 kmh_mph" 10 "45 kmh_mph" 9 "40 kmh_mph" 8 "35 kmh_mph" 7 "30 kmh_mph" 6 "25 kmh_mph" 5 "20 kmh_mph" 4 "15 kmh_mph" 3 "10 kmh_mph" 2 "7 kmh_mph" 1 "Less Than Or Equal To 5 km/h [mph]" 0 "Unknown" ;
VAL_TABLE_ HVChrgInhbRsn 3 "See Charging Station" 2 "Charge Cord Lock Not Engaged" 1 "Charge Cord Not Fully Inserted" 0 "No Action" ;
VAL_TABLE_ EASSI_StrtTyp 7 "Type G" 6 "Type F" 5 "Type E" 4 "Type D" 3 "Type C" 2 "Type B" 1 "Type A" 0 "No Start" ;
VAL_TABLE_ EASSI_StrtStpSt 3 "Engine Stopping" 2 "Engine Starting" 1 "Engine Running" 0 "Engine Off" ;
VAL_TABLE_ ElcTransRngRq 7 "Unused and Reserved" 6 "Manual Range" 5 "Low Range" 4 "Drive" 3 "Neutral" 2 "Reverse" 1 "Park" 0 "No Request" ;
VAL_TABLE_ ICSTS_TchPrxmty 2 "Touch" 1 "Near" 0 "Far" ;
VAL_TABLE_ FrPedDetCsStReq 3 "Alert and Brake" 2 "Alert" 1 "Off" 0 "No Action" ;
VAL_TABLE_ FrPedDetCsCrStVal 3 "Alert and Brake" 2 "Alert" 1 "Off" 0 "No Action" ;
VAL_TABLE_ LBCVLS_VehGPSLct 4 "Vehicle Within Stored GPS Region 4" 3 "Vehicle Within Stored GPS Region 3" 2 "Vehicle Within Stored GPS Region 2" 1 "Vehicle Within Stored GPS Region 1" 0 "Vehicle Not Within Stored GPS Region" ;
VAL_TABLE_ LBCPosMdfcReq 4 "Store Position 4" 3 "Store Position 3" 2 "Store Position 2" 1 "Store Position 1" 0 "No Action" ;
VAL_TABLE_ LBCPSS_PosUpdtStat 2 "Position Modification Failed " 1 "Position  Updated  " 0 "No Action" ;
VAL_TABLE_ LBCPSS_PosUpdtLct 4 "Position 4" 3 "Position 3" 2 "Position 2" 1 "Position 1" 0 "No Action" ;
VAL_TABLE_ LBCCsStReq 2 "On" 1 "Off" 0 "No Action" ;
VAL_TABLE_ LBCCsCrStVal 2 "On" 1 "Off" 0 "No Action" ;
VAL_TABLE_ LBCCDRR_PosNumbr 4 "Position Number 4 " 3 "Position Number 3" 2 "Position Number 2" 1 "Position Number 1" 0 "No Action" ;
VAL_TABLE_ LBCCDRR_PosNum 4 "Position Number 4" 3 "Position Number 3" 2 "Position Number 2" 1 "Position Number 1" 0 "No Action" ;
VAL_TABLE_ LBCCDRR_ClrStrdPosResp 2 "Clear Position Performed" 1 "Clear Position Request Acknowledged" 0 "No Action" ;
VAL_TABLE_ LBCCDRR_ClrStrdPosReq 2 "Confirmation to Clear Position" 1 "Request to Clear Position" 0 "No Action" ;
VAL_TABLE_ ElecShfRngDisp 15 "Unused and Reserved 3" 14 "Unused and Reserved 2" 13 "Unused and Reserved 1" 12 "Park Requested And Denied" 11 "Drive Requested And In Progress" 10 "Neutral Requested And In Progress" 9 "Reverse Requested And In Progress" 8 "Park Requested And In Progress" 7 "Reserved" 6 "Manual Nominal" 5 "Low Nominal" 4 "Drive Nominal" 3 "Neutral Nominal" 2 "Reverse Nominal" 1 "Park Nominal" 0 "No Display " ;
VAL_TABLE_ ThrmlRefCompStatFdbck 3 "Invalid" 2 "Inoperative" 1 "Degraded Operation" 0 "Normal Operation" ;
VAL_TABLE_ RrPedDetCstStVal 7 "Reserved3" 6 "Reserved2" 5 "Reserved1" 4 "Alert and Brake" 3 "Alert" 2 "On" 1 "Off" 0 "No Action" ;
VAL_TABLE_ RrPedDetCstStReq 7 "Reserved3" 6 "Reserved2" 5 "Reserved1" 4 "Alert and Brake" 3 "Alert" 2 "On" 1 "Off" 0 "No Action" ;
VAL_TABLE_ NVSysStat 7 "Needs Headlights" 6 "Temporarily Unavailable" 5 "Not Dark" 4 "Needs Service" 3 "Active" 2 "Inactive" 1 "Initializing" 0 "Unknown" ;
VAL_TABLE_ IntDimSeldClrTypStVal 31 "Color Type 30" 30 "Color Type 29" 29 "Color Type 28" 28 "Color Type 27" 27 "Color Type 26" 26 "Color Type 25" 25 "Color Type 24" 24 "Color Type 23" 23 "Color Type 22" 22 "Color Type 21" 21 "Color Type 20" 20 "Color Type 19" 19 "Color Type 18" 18 "Color Type 17" 17 "Color Type 16" 16 "Color Type 15" 15 "Color Type 14" 14 "Color Type 13" 13 "Color Type 12" 12 "Color Type 11" 11 "Color Type 10" 10 "Color Type 9" 9 "Color Type 8" 8 "Color Type 7" 7 "Color Type 6" 6 "Color Type 5" 5 "Color Type 4" 4 "Color Type 3" 3 "Color Type 2" 2 "Color Type 1" 1 "Off" 0 "No Action" ;
VAL_TABLE_ IntDimSeldClrTypStReq 31 "Color Type 30" 30 "Color Type 29" 29 "Color Type 28" 28 "Color Type 27" 27 "Color Type 26" 26 "Color Type 25" 25 "Color Type 24" 24 "Color Type 23" 23 "Color Type 22" 22 "Color Type 21" 21 "Color Type 20" 20 "Color Type 19" 19 "Color Type 18" 18 "Color Type 17" 17 "Color Type 16" 16 "Color Type 15" 15 "Color Type 14" 14 "Color Type 13" 13 "Color Type 12" 12 "Color Type 11" 11 "Color Type 10" 10 "Color Type 9" 9 "Color Type 8" 8 "Color Type 7" 7 "Color Type 6" 6 "Color Type 5" 5 "Color Type 4" 4 "Color Type 3" 3 "Color Type 2" 2 "Color Type 1" 1 "Off" 0 "No Action" ;
VAL_TABLE_ IntDimSeldAnmTypStVal 15 "Animation Type 14" 14 "Animation Type 13" 13 "Animation Type 12" 12 "Animation Type 11" 11 "Animation Type 10" 10 "Animation Type 9" 9 "Animation Type 8" 8 "Animation Type 7" 7 "Animation Type 6" 6 "Animation Type 5" 5 "Animation Type 4" 4 "Animation Type 3" 3 "Animation Type 2" 2 "Animation Type 1" 1 "Off" 0 "No Action" ;
VAL_TABLE_ IntDimSeldAnmTypStReq 15 "Animation Type 14" 14 "Animation Type 13" 13 "Animation Type 12" 12 "Animation Type 11" 11 "Animation Type 10" 10 "Animation Type 9" 9 "Animation Type 8" 8 "Animation Type 7" 7 "Animation Type 6" 6 "Animation Type 5" 5 "Animation Type 4" 4 "Animation Type 3" 3 "Animation Type 2" 2 "Animation Type 1" 1 "Off" 0 "No Action" ;
VAL_TABLE_ APAIconDispRq 7 "Unused & Reserved" 6 "Unused & Reserved" 5 "Unused & Reserved" 4 "Complete" 3 "Stop" 2 "Reverse" 1 "Forward" 0 "No Icon" ;
VAL_TABLE_ RtBsChrgCmplnTmPrfRsp 2 "Latest Possible" 1 "Earliest Possible" 0 "No Action" ;
VAL_TABLE_ RtBsChrgCmplnTmPrfReq 2 "Latest Possible" 1 "Earliest Possible" 0 "No Action" ;
VAL_TABLE_ ManTransIndReq 3 "Indication 3" 2 "Indication 2" 1 "Indication 1" 0 "No Indication" ;
VAL_TABLE_ ILSSCommErr 1 "Comm Error Detected" 0 "No Comm Error" ;
VAL_TABLE_ RRSCDS_DispSz 2 "Small Size" 1 "Medium Size" 0 "Full Size" ;
VAL_TABLE_ RRSCDS_CshLgAdjFdRr 3 "Rearward" 2 "Forward" 1 "Selected - No Movement " 0 "Not Selected" ;
VAL_TABLE_ RRSCDS_BkCshBlstInOt 5 "Cushion Bolster Out" 4 "Cushion Bolster In" 3 "Back Bolster Out" 2 "Back Bolster In" 1 "Selected - No Movement" 0 "Not Selected" ;
VAL_TABLE_ RRSCDS_CshBlstrInOut 3 "Out" 2 "In" 1 "Selected - No Movement" 0 "Not Selected" ;
VAL_TABLE_ RRSCDS_BkBlstrInOut 3 "Out" 2 "In" 1 "Selected - No Movement" 0 "Not Selected" ;
VAL_TABLE_ RRSCDS_LmbrUDnFdRr 5 "Rearward" 4 "Forward" 3 "Down" 2 "Up" 1 "Selected - No Movement " 0 "Not Selected" ;
VAL_TABLE_ RRSCDS_LmbrFwdRr 3 "Rearward" 2 "Forward" 1 "Selected - No Movement " 0 "Not Selected" ;
VAL_TABLE_ RRSCDS_LmbrUpDwn 3 "Down" 2 "Up" 1 "Selected - No Movement" 0 "Not Selected" ;
VAL_TABLE_ RRSCDS_UprShldrFdRr 3 "Rearward" 2 "Forward" 1 "Selected - No Movement " 0 "Not Selected" ;
VAL_TABLE_ RRSCDS_HdrstTltFwdRr 3 "Rearward" 2 "Forward" 1 "Selected - No Movement " 0 "Not Selected" ;
VAL_TABLE_ RRSCDS_HdrstWngInOt 3 "Out" 2 "In" 1 "Selected - No Movement" 0 "Not Selected" ;
VAL_TABLE_ RRSCDS_HdrstFdRrUDn 5 "Rearward" 4 "Forward" 3 "Down" 2 "Up" 1 "Selected - No Movement " 0 "Not Selected" ;
VAL_TABLE_ RRSCDS_HdrstFwdRrwd 3 "Rearward" 2 "Forward" 1 "Selected - No Movement " 0 "Not Selected" ;
VAL_TABLE_ RRSCDS_HdrstUpDn 3 "Down" 2 "Up" 1 "Selected - No Movement" 0 "Not Selected" ;
VAL_TABLE_ RRSCDS_MassgIntsty 7 "Massage Intensity 7" 6 "Massage Intensity 6" 5 "Massage Intensity 5" 4 "Massage Intensity 4" 3 "Massage Intensity 3" 2 "Massage Intensity 2" 1 "Massage Intensity 1" 0 "Massage Off" ;
VAL_TABLE_ RRSCDS_MassgTyp 15 "Massage Type 15" 14 "Massage Type 14" 13 "Massage Type 13" 12 "Massage Type 12" 11 "Massage Type 11" 10 "Massage Type 10" 9 "Massage Type 9" 8 "Massage Type 8" 7 "Massage Type 7" 6 "Massage Type 6" 5 "Massage Type 5" 4 "Massage Type 4" 3 "Massage Type 3" 2 "Massage Type 2" 1 "Massage Type 1" 0 "Massage Off" ;
VAL_TABLE_ RRSCDS_Massg 2 "Selected Massage On" 1 "Selected Massage Off" 0 "Not Selected" ;
VAL_TABLE_ LRSCDS_DispSz 2 "Small Size" 1 "Medium Size" 0 "Full Size" ;
VAL_TABLE_ LRSCDS_CshLgAdjFdRr 3 "Rearward" 2 "Forward" 1 "Selected - No Movement " 0 "Not Selected" ;
VAL_TABLE_ LRSCDS_BkCshBlstInOt 5 "Cushion Bolster Out" 4 "Cushion Bolster In" 3 "Back Bolster Out" 2 "Back Bolster In" 1 "Selected - No Movement" 0 "Not Selected" ;
VAL_TABLE_ LRSCDS_CshBlstrInOut 3 "Out" 2 "In" 1 "Selected - No Movement" 0 "Not Selected" ;
VAL_TABLE_ LRSCDS_BkBlstrInOut 3 "Out" 2 "In" 1 "Selected - No Movement" 0 "Not Selected" ;
VAL_TABLE_ LRSCDS_LmbrUDnFdRr 5 "Rearward" 4 "Forward" 3 "Down" 2 "Up" 1 "Selected - No Movement " 0 "Not Selected" ;
VAL_TABLE_ LRSCDS_LmbrFwdRr 3 "Rearward" 2 "Forward" 1 "Selected - No Movement " 0 "Not Selected" ;
VAL_TABLE_ LRSCDS_LmbrUpDwn 3 "Down" 2 "Up" 1 "Selected - No Movement" 0 "Not Selected" ;
VAL_TABLE_ LRSCDS_UprShldrFdRr 3 "Rearward" 2 "Forward" 1 "Selected - No Movement " 0 "Not Selected" ;
VAL_TABLE_ LRSCDS_HdrstTltFwdRr 3 "Rearward" 2 "Forward" 1 "Selected - No Movement " 0 "Not Selected" ;
VAL_TABLE_ LRSCDS_HdrstWngInOt 3 "Out" 2 "In" 1 "Selected - No Movement" 0 "Not Selected" ;
VAL_TABLE_ LRSCDS_HdrstFdRrUDn 5 "Rearward" 4 "Forward" 3 "Down" 2 "Up" 1 "Selected - No Movement " 0 "Not Selected" ;
VAL_TABLE_ LRSCDS_HdrstFwdRrwd 3 "Rearward" 2 "Forward" 1 "Selected - No Movement " 0 "Not Selected" ;
VAL_TABLE_ LRSCDS_HdrstUpDn 3 "Down" 2 "Up" 1 "Selected - No Movement" 0 "Not Selected" ;
VAL_TABLE_ LRSCDS_MassgIntsty 7 "Massage Intensity 7" 6 "Massage Intensity 6" 5 "Massage Intensity 5" 4 "Massage Intensity 4" 3 "Massage Intensity 3" 2 "Massage Intensity 2" 1 "Massage Intensity 1" 0 "Massage Off" ;
VAL_TABLE_ LRSCDS_MassgTyp 15 "Massage Type 15" 14 "Massage Type 14" 13 "Massage Type 13" 12 "Massage Type 12" 11 "Massage Type 11" 10 "Massage Type 10" 9 "Massage Type 9" 8 "Massage Type 8" 7 "Massage Type 7" 6 "Massage Type 6" 5 "Massage Type 5" 4 "Massage Type 4" 3 "Massage Type 3" 2 "Massage Type 2" 1 "Massage Type 1" 0 "Massage Off" ;
VAL_TABLE_ LRSCDS_Massg 2 "Selected Massage On" 1 "Selected Massage Off" 0 "Not Selected" ;
VAL_TABLE_ ExtHlStrAssCsStRq 2 "Standard Hold" 1 "Extended Hold" 0 "No Action" ;
VAL_TABLE_ ExtHlStrAssCsCrStVal 2 "Standard Hold" 1 "Extended Hold" 0 "No Action" ;
VAL_TABLE_ RtLnDepWrnSt 3 "Service Alignment" 2 "Right Lane Alert" 1 "Right Lane Ready to Assist" 0 "Right Lane Not Ready to Assist" ;
VAL_TABLE_ LftLnDepWrnSt 3 "Service Alignment" 2 "Left Lane Alert" 1 "Left Lane Ready to Assist" 0 "Left Lane Not Ready to Assist" ;
VAL_TABLE_ DSCDS_UprShldrFdRr 3 "Rearward" 2 "Forward" 1 "Selected - No Movement" 0 "Not Selected" ;
VAL_TABLE_ DSCDS_MassgTyp 15 "Massage Type 15" 14 "Massage Type 14" 13 "Massage Type 13" 12 "Massage Type 12" 11 "Massage Type 11" 10 "Massage Type 10" 9 "Massage Type 9" 8 "Massage Type 8" 7 "Massage Type 7" 6 "Massage Type 6" 5 "Massage Type 5" 4 "Massage Type 4" 3 "Massage Type 3" 2 "Massage Type 2" 1 "Massage Type 1" 0 "Massage Off" ;
VAL_TABLE_ DSCDS_MassgIntsty 7 "Massage Intensity 7" 6 "Massage Intensity 6" 5 "Massage Intensity 5" 4 "Massage Intensity 4" 3 "Massage Intensity 3" 2 "Massage Intensity 2" 1 "Massage Intensity 1" 0 "Massage Off" ;
VAL_TABLE_ DSCDS_Massg 2 "Selected Massage On" 1 "Selected Massage Off" 0 "Not Selected" ;
VAL_TABLE_ DSCDS_LmbrUpDwn 3 "Down" 2 "Up" 1 "Selected - No Movement" 0 "Not Selected" ;
VAL_TABLE_ DSCDS_LmbrUDnFdRr 5 "Rearward" 4 "Forward" 3 "Down" 2 "Up" 1 "Selected - No Movement" 0 "Not Selected" ;
VAL_TABLE_ DSCDS_LmbrFwdRr 3 "Rearward" 2 "Forward" 1 "Selected - No Movement" 0 "Not Selected" ;
VAL_TABLE_ DSCDS_HdrstWngInOt 3 "Out" 2 "In" 1 "Selected - No Movement" 0 "Not Selected" ;
VAL_TABLE_ DSCDS_HdrstUpDn 3 "Down" 2 "Up" 1 "Selected - No Movement" 0 "Not Selected" ;
VAL_TABLE_ DSCDS_HdrstUDnFdRr 5 "Rearward" 4 "Forward" 3 "Down" 2 "Up" 1 "Selected - No Movement" 0 "Not Selected" ;
VAL_TABLE_ DSCDS_HdrstTltFwdRr 3 "Rearward" 2 "Forward" 1 "Selected - No Movement" 0 "Not Selected" ;
VAL_TABLE_ DSCDS_HdrstFwdRrwd 3 "Rearward" 2 "Forward" 1 "Selected - No Movement" 0 "Not Selected" ;
VAL_TABLE_ DSCDS_DispSz 3 "Reserved" 2 "Small Size" 1 "Medium Size" 0 "Full Size" ;
VAL_TABLE_ DSCDS_CshLgAdjFdRr 3 "Rearward" 2 "Forward" 1 "Selected - No Movement" 0 "Not Selected" ;
VAL_TABLE_ DSCDS_CshBlstrInOut 3 "Out" 2 "In" 1 "Selected - No Movement" 0 "Not Selected" ;
VAL_TABLE_ DSCDS_BkCshBlstInOt 5 "Cushion Bolster Out" 4 "Cushion Bolster In" 3 "Back Bolster Out" 2 "Back Bolster In" 1 "Selected - No Movement" 0 "Not Selected" ;
VAL_TABLE_ DSCDS_BkBlstrInOut 3 "Out" 2 "In" 1 "Selected - No Movement" 0 "Not Selected" ;
VAL_TABLE_ PSCDS_UprShldrFdRr 3 "Rearward" 2 "Forward" 1 "Selected - No Movement" 0 "Not Selected" ;
VAL_TABLE_ PSCDS_MassgTyp 15 "Massage Type 15" 14 "Massage Type 14" 13 "Massage Type 13" 12 "Massage Type 12" 11 "Massage Type 11" 10 "Massage Type 10" 9 "Massage Type 9" 8 "Massage Type 8" 7 "Massage Type 7" 6 "Massage Type 6" 5 "Massage Type 5" 4 "Massage Type 4" 3 "Massage Type 3" 2 "Massage Type 2" 1 "Massage Type 1" 0 "Massage Off" ;
VAL_TABLE_ PSCDS_MassgIntsty 7 "Massage Intensity 7" 6 "Massage Intensity 6" 5 "Massage Intensity 5" 4 "Massage Intensity 4" 3 "Massage Intensity 3" 2 "Massage Intensity 2" 1 "Massage Intensity 1" 0 "Massage Off" ;
VAL_TABLE_ PSCDS_Massg 2 "Selected Massage On" 1 "Selected Massage Off" 0 "Not Selected" ;
VAL_TABLE_ PSCDS_LmbrUpDwn 3 "Down" 2 "Up" 1 "Selected - No Movement" 0 "Not Selected" ;
VAL_TABLE_ PSCDS_LmbrUDnFdRr 5 "Rearward" 4 "Forward" 3 "Down" 2 "Up" 1 "Selected - No Movement" 0 "Not Selected" ;
VAL_TABLE_ PSCDS_LmbrFwdRr 3 "Rearward" 2 "Forward" 1 "Selected - No Movement" 0 "Not Selected" ;
VAL_TABLE_ PSCDS_HdrstWngInOt 3 "Out" 2 "In" 1 "Selected - No Movement" 0 "Not Selected" ;
VAL_TABLE_ PSCDS_HdrstUpDn 3 "Down" 2 "Up" 1 "Selected - No Movement" 0 "Not Selected" ;
VAL_TABLE_ PSCDS_HdrstUDnFdRr 5 "Rearward" 4 "Forward" 3 "Down" 2 "Up" 1 "Selected - No Movement" 0 "Not Selected" ;
VAL_TABLE_ PSCDS_HdrstTltFwdRr 3 "Rearward" 2 "Forward" 1 "Selected - No Movement" 0 "Not Selected" ;
VAL_TABLE_ PSCDS_HdrstFwdRrwd 3 "Rearward" 2 "Forward" 1 "Selected - No Movement" 0 "Not Selected" ;
VAL_TABLE_ PSCDS_DispSz 3 "Reserved" 2 "Small Size" 1 "Medium Size" 0 "Full Size" ;
VAL_TABLE_ PSCDS_CshLgAdjFdRr 3 "Rearward" 2 "Forward" 1 "Selected - No Movement" 0 "Not Selected" ;
VAL_TABLE_ PSCDS_CshBlstrInOut 3 "Out" 2 "In" 1 "Selected - No Movement" 0 "Not Selected" ;
VAL_TABLE_ PSCDS_BkCshBlstInOt 5 "Cushion Bolster Out" 4 "Cushion Bolster In" 3 "Back Bolster Out" 2 "Back Bolster In" 1 "Selected - No Movement" 0 "Not Selected" ;
VAL_TABLE_ PSCDS_BkBlstrInOut 3 "Out" 2 "In" 1 "Selected - No Movement" 0 "Not Selected" ;
VAL_TABLE_ PedWrnIndReq 3 "Reserved " 2 "Pedestrian alert" 1 "Pedestrian detected" 0 "None" ;
VAL_TABLE_ SpdLmtrSttngTypAct 3 "Reserved" 2 "Auto" 1 "Manual" 0 "Off" ;
VAL_TABLE_ SetSpdLmtRchd 3 "Reserved" 2 "Low limit reached" 1 "High limit reached" 0 "No limit reached" ;
VAL_TABLE_ AdptPsngrSeatStng 7 "Performance Mode 7" 6 "Performance Mode 6" 5 "Performance Mode 5" 4 "Performance Mode 4" 3 "Performance Mode 3" 2 "Performance Mode 2" 1 "Performance Mode 1" 0 "No Action" ;
VAL_TABLE_ AdptDrvrSeatStng 7 "Performance Mode 7" 6 "Performance Mode 6" 5 "Performance Mode 5" 4 "Performance Mode 4" 3 "Performance Mode 3" 2 "Performance Mode 2" 1 "Performance Mode 1" 0 "No Action" ;
VAL_TABLE_ PerfMdMainMenuType 7 "Reserved" 6 "Reserved" 5 "Reserved" 4 "Reserved" 3 "Main Menu Type 3" 2 "Main Menu Type 2" 1 "Main Menu Type 1" 0 "No Action" ;
VAL_TABLE_ PMVSS_Trans 7 "Visualization Type 7" 6 "Visualization Type 6" 5 "Visualization Type 5" 4 "Visualization Type 4" 3 "Visualization Type 3" 2 "Visualization Type 2" 1 "Visualization Type 1" 0 "No Action" ;
VAL_TABLE_ PMVSS_Susp 7 "Visualization Type 7" 6 "Visualization Type 6" 5 "Visualization Type 5" 4 "Visualization Type 4" 3 "Visualization Type 3" 2 "Visualization Type 2" 1 "Visualization Type 1" 0 "No Action" ;
VAL_TABLE_ PMVSS_Strng 7 "Visualization Type 7" 6 "Visualization Type 6" 5 "Visualization Type 5" 4 "Visualization Type 4" 3 "Visualization Type 3" 2 "Visualization Type 2" 1 "Visualization Type 1" 0 "No Action" ;
VAL_TABLE_ PMVSS_Snd 7 "Visualization Type 7" 6 "Visualization Type 6" 5 "Visualization Type 5" 4 "Visualization Type 4" 3 "Visualization Type 3" 2 "Visualization Type 2" 1 "Visualization Type 1" 0 "No Action" ;
VAL_TABLE_ PMVSS_PsngrSeat 7 "Visualization Type 7" 6 "Visualization Type 6" 5 "Visualization Type 5" 4 "Visualization Type 4" 3 "Visualization Type 3" 2 "Visualization Type 2" 1 "Visualization Type 1" 0 "No Action" ;
VAL_TABLE_ PMVSS_Exhst 7 "Visualization Type 7" 6 "Visualization Type 6" 5 "Visualization Type 5" 4 "Visualization Type 4" 3 "Visualization Type 3" 2 "Visualization Type 2" 1 "Visualization Type 1" 0 "No Action" ;
VAL_TABLE_ PMVSS_Eng 7 "Visualization Type 7" 6 "Visualization Type 6" 5 "Visualization Type 5" 4 "Visualization Type 4" 3 "Visualization Type 3" 2 "Visualization Type 2" 1 "Visualization Type 1" 0 "No Action" ;
VAL_TABLE_ PMVSS_DrvrSeat 7 "Visualization Type 7" 6 "Visualization Type 6" 5 "Visualization Type 5" 4 "Visualization Type 4" 3 "Visualization Type 3" 2 "Visualization Type 2" 1 "Visualization Type 1" 0 "No Action" ;
VAL_TABLE_ PMVSS_Drvln 7 "Visualization Type 7" 6 "Visualization Type 6" 5 "Visualization Type 5" 4 "Visualization Type 4" 3 "Visualization Type 3" 2 "Visualization Type 2" 1 "Visualization Type 1" 0 "No Action" ;
VAL_TABLE_ PMVSS_Disps 7 "Visualization Type 7" 6 "Visualization Type 6" 5 "Visualization Type 5" 4 "Visualization Type 4" 3 "Visualization Type 3" 2 "Visualization Type 2" 1 "Visualization Type 1" 0 "No Action" ;
VAL_TABLE_ PMVSS_AdptCrsCnt 7 "Visualization Type 7" 6 "Visualization Type 6" 5 "Visualization Type 5" 4 "Visualization Type 4" 3 "Visualization Type 3" 2 "Visualization Type 2" 1 "Visualization Type 1" 0 "No Action" ;
VAL_TABLE_ PsngStPerfMdCsStReq 7 "Auto" 6 "Performance Mode 6" 5 "Performance Mode 5" 4 "Performance Mode 4" 3 "Performance Mode 3" 2 "Performance Mode 2" 1 "Performance Mode 1" 0 "No Action" ;
VAL_TABLE_ PsngStPerfMdCsCrStVal 7 "Auto" 6 "Performance Mode 6" 5 "Performance Mode 5" 4 "Performance Mode 4" 3 "Performance Mode 3" 2 "Performance Mode 2" 1 "Performance Mode 1" 0 "No Action" ;
VAL_TABLE_ DrvrStPerfMdCsStReq 7 "Auto" 6 "Performance Mode 6" 5 "Performance Mode 5" 4 "Performance Mode 4" 3 "Performance Mode 3" 2 "Performance Mode 2" 1 "Performance Mode 1" 0 "No Action" ;
VAL_TABLE_ DrvrStPerfMdCsCrStVal 7 "Auto" 6 "Performance Mode 6" 5 "Performance Mode 5" 4 "Performance Mode 4" 3 "Performance Mode 3" 2 "Performance Mode 2" 1 "Performance Mode 1" 0 "No Action" ;
VAL_TABLE_ DrvStyPerfMdCsStReq 7 "Performance Mode 7" 6 "Performance Mode 6" 5 "Performance Mode 5" 4 "Performance Mode 4" 3 "Performance Mode 3" 2 "Performance Mode 2" 1 "Performance Mode 1" 0 "No Action" ;
VAL_TABLE_ DrvStyPerfMdCsCrStVal 7 "Performance Mode 7" 6 "Performance Mode 6" 5 "Performance Mode 5" 4 "Performance Mode 4" 3 "Performance Mode 3" 2 "Performance Mode 2" 1 "Performance Mode 1" 0 "No Action" ;
VAL_TABLE_ ACCPerfMdCsStReq 7 "Auto" 6 "Performance Mode 6" 5 "Performance Mode 5" 4 "Performance Mode 4" 3 "Performance Mode 3" 2 "Performance Mode 2" 1 "Performance Mode 1" 0 "No Action" ;
VAL_TABLE_ ACCPerfMdCsCrStVal 7 "Auto" 6 "Performance Mode 6" 5 "Performance Mode 5" 4 "Performance Mode 4" 3 "Performance Mode 3" 2 "Performance Mode 2" 1 "Performance Mode 1" 0 "No Action" ;
VAL_TABLE_ TCTPIR_DrvNotfn 15 "Indication 15" 14 "Indication 14" 13 "Indication 13" 12 "Indication 12" 11 "Indication 11" 10 "Indication 10" 9 "Indication 9" 8 "Indication 8" 7 "Indication 7" 6 "Indication 6" 5 "Indication 5" 4 "Indication 4" 3 "Indication 3" 2 "Indication 2" 1 "Indication 1" 0 "No Indication" ;
VAL_TABLE_ VidSrcUICntrlStat 1 "Active" 0 "Inactive" ;
VAL_TABLE_ VidMstrDsplyMd 2 "Split Screen" 1 "Full Screen" 0 "No Action" ;
VAL_TABLE_ ClmtCtrlHtrEngRunRq 1 "Engine Run Requested" 0 "No Action" ;
VAL_TABLE_ SndEnhcmtPerfMdRq 7 "Performance Mode 7" 6 "Performance Mode 6" 5 "Performance Mode 5" 4 "Performance Mode 4" 3 "Performance Mode 3" 2 "Performance Mode 2" 1 "Performance Mode 1" 0 "No Action" ;
VAL_TABLE_ DsplyPerfMdRq 7 "Performance Mode 7" 6 "Performance Mode 6" 5 "Performance Mode 5" 4 "Performance Mode 4" 3 "Performance Mode 3" 2 "Performance Mode 2" 1 "Performance Mode 1" 0 "No Action" ;
VAL_TABLE_ RdHVltBatPckVltM 1 "Use Data" 0 "Don't Use Data" ;
VAL_TABLE_ RdHVltBatPckCrntM 1 "Use Data" 0 "Don't Use Data" ;
VAL_TABLE_ EDADS_RcmndtFwdGr 15 "Unused and Reserved 7" 14 "Unused and Reserved 6" 13 "Unused and Reserved 5" 12 "Unused and Reserved 4" 11 "Unused and Reserved 3" 10 "Tenth Gear" 9 "Ninth Gear" 8 "Eighth Gear" 7 "Seventh Gear" 6 "Sixth Gear" 5 "Fifth Gear" 4 "Fourth Gear" 3 "Third Gear" 2 "Second Gear" 1 "First Gear" 0 "None" ;
VAL_TABLE_ EDADS_CrntFwdMsdG 15 "Unused and Reserved 7" 14 "Unused and Reserved 6" 13 "Unused and Reserved 5" 12 "Unused and Reserved 4" 11 "Unused and Reserved 3" 10 "Tenth Gear" 9 "Ninth Gear" 8 "Eighth Gear" 7 "Seventh Gear" 6 "Sixth Gear" 5 "Fifth Gear" 4 "Fourth Gear" 3 "Third Gear" 2 "Second Gear" 1 "First Gear" 0 "None" ;
VAL_TABLE_ EDADS_ShftIndStat 2 "No Shift" 1 "Shift Up" 0 "Shift Down" ;
VAL_TABLE_ DslExhFldWrngIdRqER 15 "Warning Level 15" 14 "Warning Level 14" 13 "Warning Level 13" 12 "Warning Level 12" 11 "Warning Level 11" 10 "Warning Level 10" 9 "Warning Level 9" 8 "Warning Level 8" 7 "Warning Level 7" 6 "Warning Level 6" 5 "Warning Level 5" 4 "Warning Level 4" 3 "Warning Level 3" 2 "Warning Level 2" 1 "Warning Level 1" 0 "No Indication" ;
VAL_TABLE_ DslExhFldQlyWrngIReq 15 "Warning Level 15" 14 "Warning Level 14" 13 "Warning Level 13" 12 "Warning Level 12" 11 "Warning Level 11" 10 "Warning Level 10" 9 "Warning Level 9" 8 "Warning Level 8" 7 "Warning Level 7" 6 "Warning Level 6" 5 "Warning Level 5" 4 "Warning Level 4" 3 "Warning Level 3" 2 "Warning Level 2" 1 "Warning Level 1" 0 "No Indication" ;
VAL_TABLE_ DslExNxEmWrngIndRq 15 "Warning Level 15" 14 "Warning Level 14" 13 "Warning Level 13" 12 "Warning Level 12" 11 "Warning Level 11" 10 "Warning Level 10" 9 "Warning Level 9" 8 "Warning Level 8" 7 "Warning Level 7" 6 "Warning Level 6" 5 "Warning Level 5" 4 "Warning Level 4" 3 "Warning Level 3" 2 "Warning Level 2" 1 "Warning Level 1" 0 "No Indication" ;
VAL_TABLE_ DslExFldTpWrngIndRq 15 "Warning Level 15" 14 "Warning Level 14" 13 "Warning Level 13" 12 "Warning Level 12" 11 "Warning Level 11" 10 "Warning Level 10" 9 "Warning Level 9" 8 "Warning Level 8" 7 "Warning Level 7" 6 "Warning Level 6" 5 "Warning Level 5" 4 "Warning Level 4" 3 "Warning Level 3" 2 "Warning Level 2" 1 "Warning Level 1" 0 "No Indication" ;
VAL_TABLE_ DslExFldCnWrngIndRq 15 "Warning Level 15" 14 "Warning Level 14" 13 "Warning Level 13" 12 "Warning Level 12" 11 "Warning Level 11" 10 "Warning Level 10" 9 "Warning Level 9" 8 "Warning Level 8" 7 "Warning Level 7" 6 "Warning Level 6" 5 "Warning Level 5" 4 "Warning Level 4" 3 "Warning Level 3" 2 "Warning Level 2" 1 "Warning Level 1" 0 "No Indication" ;
VAL_TABLE_ DrvSelMd8Stat 1 "Active" 0 "Inactive" ;
VAL_TABLE_ DrvSelMd7Stat 1 "Active" 0 "Inactive" ;
VAL_TABLE_ DrvSelMd6Stat 1 "Active" 0 "Inactive" ;
VAL_TABLE_ DrvSelMd5Stat 1 "Active" 0 "Inactive" ;
VAL_TABLE_ DrvSelMd4Stat 1 "Active" 0 "Inactive" ;
VAL_TABLE_ DrvSelMd3Stat 1 "Active" 0 "Inactive" ;
VAL_TABLE_ DrvSelMd2Stat 1 "Active" 0 "Inactive" ;
VAL_TABLE_ MntnceMdDsplyRq 15 "Unused and Reserved" 14 "Continue FM" 13 "Force FM" 12 "FM 1 Day Warning" 11 "FM 2 Day Warning" 10 "FM 3 Day Warning" 9 "FM 4 Day Warning" 8 "FM 5 Day Warning" 7 "Continue EM" 6 "Force EM" 5 "EM 1 Day Warning" 4 "EM 2 Day Warning" 3 "EM 3 Day Warning" 2 "EM 4 Day Warning" 1 "EM 5 Day Warning" 0 "No Request" ;
VAL_TABLE_ AuxClntHtrVlvStat 7 "Unused and Reserved 2" 6 "De-Aeration Routine Active" 5 "Diagnostic Override" 4 "Re-Calibration" 3 "Fault Active" 2 "Engine Link" 1 "Transition" 0 "Engine Bypass" ;
VAL_TABLE_ DrvSelMd1Stat 1 "Active" 0 "Inactive" ;
VAL_TABLE_ HybChrgMdStat 3 "Unused and reserved 2" 2 "Unused and reserved 1" 1 "Charge Sustaining" 0 "Charge Depleting" ;
VAL_TABLE_ VidSrcCompFormatER 8 "ATSC" 7 "DMB" 6 "DTMB" 5 "ISBD-T" 4 "DVB-T" 3 "SECAM" 2 "PAL" 1 "NTSC" ;
VAL_TABLE_ SODRIC_IndReq 2 "Flashing Indication" 1 "Continuous Indication" 0 "Off" ;
VAL_TABLE_ HybMdDisp 15 "Engine Charging Battery While Idle" 14 "Engine Charging Battery Moving" 13 "Engine Power Load Sharing" 12 "Battery Power Load Sharing" 11 "Undetermined" 10 "Charging With Engine On" 9 "Charging With Engine Off" 8 "Hybrid Power 4WD" 7 "Hybrid Power 2WD" 6 "Engine Power 4WD" 5 "Engine Power 2WD" 4 "Battery Power 4WD" 3 "Battery Power 2WD" 2 "Auto Stop" 1 "Engine Idle" 0 "Default / Accessory" ;
VAL_TABLE_ SldngDrRgtStat 5 "Stopped" 4 "Closing" 3 "Opening" 2 "Closed" 1 "Full Open" 0 "Unknown" ;
VAL_TABLE_ SldngDrLftStat 5 "Stopped" 4 "Closing" 3 "Opening" 2 "Closed" 1 "Full Open" 0 "Unknown" ;
VAL_TABLE_ VidMstrSrcType 4 "Enhanced Driver Interface" 3 "Auxiliary Device" 2 "Rear Camera" 1 "Television" 0 "Video Supervisor" ;
VAL_TABLE_ VidMstrArbCmd 3 "Connection Complete" 2 "Disconnect" 1 "Connect" 0 "No Action" ;
VAL_TABLE_ RmtRcvrTunCmnd 22 "List Request" 21 "Audio Program Service Identifier" 20 "Auto Store" 19 "Station Delta within Program Type" 18 "Scan Program Type Down" 17 "Scan Program Type Up" 16 "Scan Preset Down" 15 "Scan Preset Up" 14 "Scan Down" 13 "Scan Up" 12 "Seek Preset Down" 11 "Seek Preset Up" 10 "Seek Program Type Down" 9 "Seek Program Type Up" 8 "Seek Down" 7 "Seek Up" 6 "Set Preset" 5 "Recall Preset Number" 4 "Program Type Delta" 3 "Program Type" 2 "Station Delta" 1 "Station" 0 "No Action" ;
VAL_TABLE_ RemRcvrSrcInpCmd 3 "Auxiliary Jack 2" 2 "Auxiliary Jack 1" 1 "Television" 0 "No Action" ;
VAL_TABLE_ RmtRecvtDataTyp 7 "Unknown" 3 "Video" 2 "Data" 1 "Audio" 0 "No Update" ;
VAL_TABLE_ RmtRcvrTunStat 1 "Tuning" 0 "Tuned" ;
VAL_TABLE_ RmtRcvrCmndStat 3 "Out of Range" 2 "Not Supported" 1 "Valid Command" 0 "No Update" ;
VAL_TABLE_ RemRcvrSrcInpStat 3 "Auxiliary Jack 2" 2 "Auxiliary Jack 1" 1 "Television" 0 "No Action" ;
VAL_TABLE_ VidSrcType 3 "Auxiliary Device" 2 "Rear Camera" 1 "Television" ;
VAL_TABLE_ VidSrcStatCode 4 "Producing Blank" 3 "Producing Video" 2 "Video Not Available" 1 "Video Available" 0 "Device Present" ;
VAL_TABLE_ CrsSpdLmtrSwStat 9 "Between Ranges" 8 "Short to Power" 7 "Open/Short to Ground" 6 "Cancel" 5 "Cruise On/Off" 4 "SL/SW On/Off/GAP" 3 "Set" 2 "Resume" 1 "No Activation" 0 "Indeterminate" ;
VAL_TABLE_ SrvcPrvdr 2 "Sirius" 1 "XM (company name)" 0 "Not Available" ;
VAL_TABLE_ CurntStnServc 5 "Other" 4 "Unsubscribed" 3 "Promotion" 2 "Pay per Use" 1 "General Subscription" 0 "No Data" ;
VAL_TABLE_ VehRefuelSt 7 "Unused and Reserved 4" 6 "Unused and Reserved 3" 5 "Unused and Reserved 2" 4 "Unused and Reserved 1" 3 "Close Fuel Door" 2 "Ready To Refuel" 1 "Wait To Refuel" 0 "Inactive" ;
VAL_TABLE_ SpdLmtUnits 1 "km/h" 0 "mph" ;
VAL_TABLE_ CurvAdvInd 3 "Winding Road" 2 "Right Turn" 1 "Left Turn" 0 "No Advisory" ;
VAL_TABLE_ ACCmEngRunReq 1 "Engine Run Requested" 0 "No Action" ;
VAL_TABLE_ FuelMdStat 3 "Alternative Fuel Cut-off Active" 2 "Liquified Petroleum Gas Mode" 1 "Natural Gas Mode" 0 "Gasoline Mode" ;
VAL_TABLE_ PsvEntCmftWndRq 3 "Reserved" 2 "Comfort Open" 1 "Comfort Close" 0 "No Action" ;
VAL_TABLE_ FldngTpSt 4 "Not Secure And Not Moving " 3 "Closing" 2 "Opening" 1 "Fully Closed" 0 "Fully Opened" ;
VAL_TABLE_ RRWndPosSt 6 "Fully Opened" 5 "Open More Than C" 4 "Position C" 3 "Posistion B" 2 "Posistion A" 1 "Open Less Than A" 0 "Fully Closed" ;
VAL_TABLE_ PsWndPosSt 6 "Fully Opened" 5 "Open More Than C" 4 "Position C" 3 "Posistion B" 2 "Posistion A" 1 "Open Less Than A" 0 "Fully Closed" ;
VAL_TABLE_ LRWndPosSt 6 "Fully Opened" 5 "Open More Than C" 4 "Position C" 3 "Posistion B" 2 "Posistion A" 1 "Open Less Than A" 0 "Fully Closed" ;
VAL_TABLE_ DrvWndPosSt 6 "Fully Opened" 5 "Open More Than C" 4 "Position C" 3 "Posistion B" 2 "Posistion A" 1 "Open Less Than A" 0 "Fully Closed" ;
VAL_TABLE_ ASS2AudSrcType 28 "Phone" 24 "Sat. Digital Audio Receiver System" 20 "Digital Audio Broadcast" 16 "Remote CD Changer" 12 "Remote Digital Video Disk" 8 "Auxiliary Device" 1 "Television Tuner" ;
VAL_TABLE_ FrntPassClass 7 "Large Adult" 6 "Small Adult" 5 "Large Child" 4 "Small Child" 3 "Child Seat Unknown" 2 "Child Seat Forward" 1 "Child Seat Rearward" 0 "Classification Not Applicable" ;
VAL_TABLE_ RmStrCldStEnReq 1 "Enable Cooled Seat" 0 "Disable Cooled Seat" ;
VAL_TABLE_ EPBSysWrnIndReq 3 "Flash Rate #2 Indication" 2 "Flash Rate #1 Indication" 1 "Continuous Indication" 0 "No Indication" ;
VAL_TABLE_ ClmnLckStat 2 "Locked unsuccessful" 1 "Unlocked" 0 "Locked" 3 "Unlocked unsuccessful" ;
VAL_TABLE_ KSARUID7 1 "Present" 0 "Not Present" ;
VAL_TABLE_ KSARUID5 1 "Present" 0 "Not Present" ;
VAL_TABLE_ KSARUID6 1 "Present" 0 "Not Present" ;
VAL_TABLE_ KSARUID8 1 "Present" 0 "Not Present" ;
VAL_TABLE_ KSARUID3 1 "Present" 0 "Not Present" ;
VAL_TABLE_ KSARUID4 1 "Present" 0 "Not Present" ;
VAL_TABLE_ KSARUID2 1 "Present" 0 "Not Present" ;
VAL_TABLE_ KSARUID1 1 "Present" 0 "Not Present" ;
VAL_TABLE_ ClmnLckTT 2 "Flashing Indication" 1 "Continuous Indication" 0 "No Indication" ;
VAL_TABLE_ SecAxlOpeMod 3 "Active All Wheel Drive (High)" 2 "4 Wheel Drive Low Locked" 1 "4 Wheel Drive High Locked" 0 "2 Wheel Drive High" 15 "Neutral" 14 "Unknown" 7 "2 Wheel Drive Low" 6 "Active All Wheel Drive (Low)" 5 "4 Wheel Drive Low Open" 4 "4 Wheel Drive High Open" ;
VAL_TABLE_ EPBSta 2 "Fault" 1 "Applied" 0 "Released" ;
VAL_TABLE_ TransTUDMdStat 2 "Electronic Range Select Active" 1 "Driver Shift Control Active" 0 "No Activation" ;
VAL_TABLE_ TrnShftPtrnActStat 6 "PT Protection Pattern Active" 5 "PT Non-Protection Pattern Active" 4 "Shift Pattern 4 Active" 3 "Shift Pattern 3 Active" 2 "Shift Pattern 2 Active" 1 "Shift Pattern 1 Active" 0 "Default Shift Pattern Active" ;
VAL_TABLE_ EPBSysAudWarnReq 2 "Warning #2" 1 "Warning #1" 0 "Off" ;
VAL_TABLE_ NotSecRowRtSeaOccStat 2 "Occupied" 1 "Empty" 0 "Unknown" ;
VAL_TABLE_ NotSecRowLeSeaOccStat 2 "Occupied" 1 "Empty" 0 "Unknown" ;
VAL_TABLE_ NotSecRowCtSeaOccStat 2 "Occupied" 1 "Empty" 0 "Unknown" ;
VAL_TABLE_ NotiFrntPasSeatOccSta 5 "OccupiedLarge" 4 "OccupiedSmall" 3 "OccupiedChildseat" 2 "OccupiedUnknown" 1 "Empty" 0 "Unknown" ;
VAL_TABLE_ NotEventSta 2 "Pretensioner Deployment Event" 1 "Near Deployment Event" 0 "No Event" 3 "Airbag Deployment Event" ;
VAL_TABLE_ VehMovSta 4 "Invalid" 3 "Reverse" 2 "Forward" 1 "Neutral" 0 "Parked" ;
VAL_TABLE_ SeReOcSt 1 "Occupied" 0 "Empty" ;
VAL_TABLE_ SeReCoOcSt 2 "Occupied" 1 "Empty" 0 "Unknown" ;
VAL_TABLE_ DispMeasSysExt 2 "Imperial" 1 "US" 0 "Metric" ;
VAL_TABLE_ LngSelExt 41 "ZA English" 40 "AU English" 39 "Macedonian" 38 "Latvian" 37 "Estonian" 36 "Lithuanian" 35 "Serbian" 34 "Uzbek" 33 "Cantonese" 32 "NA Spanish" 31 "NA French" 30 "Ukrainian" 29 "Croatian" 28 "Slovenian" 27 "Romanian" 26 "Bulgarian" 25 "Thai" 24 "Brazilian Portuguese" 23 "Russian" 22 "Slovak" 21 "Czech" 20 "Hungarian" 19 "UK English" 18 "Traditional Chinese" 17 "Korean" 16 "Turkish" 15 "Polish" 14 "Standard Chinese" 13 "Arabic" 12 "Japanese" 11 "Greek" 10 "Danish" 9 "Finnish" 8 "Norwegian" 7 "Portuguese" 6 "Dutch" 5 "Spanish" 4 "French" 3 "Swedish" 2 "Italian" 1 "German" 0 "NA English" ;
VAL_TABLE_ RRHCSMIndReq 3 "Flash Rate #2 Indication" 2 "Flash Rate #1 Indication" 1 "Continuous Indication" 0 "Off" ;
VAL_TABLE_ RRHCSLIndReq 3 "Flash Rate #2 Indication" 2 "Flash Rate #1 Indication" 1 "Continuous Indication" 0 "Off" ;
VAL_TABLE_ RLHCSMIndReq 3 "Flash Rate #2 Indication" 2 "Flash Rate #1 Indication" 1 "Continuous Indication" 0 "Off" ;
VAL_TABLE_ RLHCSLIndReq 3 "Flash Rate #2 Indication" 2 "Flash Rate #1 Indication" 1 "Continuous Indication" 0 "Off" ;
VAL_TABLE_ PrkAstRrSysStat 3 "Failed" 2 "Inhibited" 1 "Enabled" 0 "Disabled" ;
VAL_TABLE_ PARrRgn4ObjStat 15 "Zone 15" 14 "Zone 14" 13 "Zone 13" 12 "Zone 12" 11 "Zone 11" 10 "Zone 10" 9 "Zone 9" 8 "Zone 8" 7 "Zone 7" 6 "Zone 6" 5 "Zone 5" 4 "Zone 4" 3 "Zone 3" 2 "Zone 2" 1 "Zone 1" 0 "No Object" ;
VAL_TABLE_ PARrRgn3ObjStat 15 "Zone 15" 14 "Zone 14" 13 "Zone 13" 12 "Zone 12" 11 "Zone 11" 10 "Zone 10" 9 "Zone 9" 8 "Zone 8" 7 "Zone 7" 6 "Zone 6" 5 "Zone 5" 4 "Zone 4" 3 "Zone 3" 2 "Zone 2" 1 "Zone 1" 0 "No Object" ;
VAL_TABLE_ PARrRgn2ObjStat 15 "Zone 15" 14 "Zone 14" 13 "Zone 13" 12 "Zone 12" 11 "Zone 11" 10 "Zone 10" 9 "Zone 9" 8 "Zone 8" 7 "Zone 7" 6 "Zone 6" 5 "Zone 5" 4 "Zone 4" 3 "Zone 3" 2 "Zone 2" 1 "Zone 1" 0 "No Object" ;
VAL_TABLE_ PARrRgn1ObjStat 15 "Zone 15" 14 "Zone 14" 13 "Zone 13" 12 "Zone 12" 11 "Zone 11" 10 "Zone 10" 9 "Zone 9" 8 "Zone 8" 7 "Zone 7" 6 "Zone 6" 5 "Zone 5" 4 "Zone 4" 3 "Zone 3" 2 "Zone 2" 1 "Zone 1" 0 "No Object" ;
VAL_TABLE_ PrkAstFrSysStat 3 "Failed" 2 "Inhibited" 1 "Enabled" 0 "Disabled" ;
VAL_TABLE_ PAFrtRgn4ObjStat 15 "Zone 15" 14 "Zone 14" 13 "Zone 13" 12 "Zone 12" 11 "Zone 11" 10 "Zone 10" 9 "Zone 9" 8 "Zone 8" 7 "Zone 7" 6 "Zone 6" 5 "Zone 5" 4 "Zone 4" 3 "Zone 3" 2 "Zone 2" 1 "Zone 1" 0 "No Object" ;
VAL_TABLE_ PAFrtRgn3ObjStat 15 "Zone 15" 14 "Zone 14" 13 "Zone 13" 12 "Zone 12" 11 "Zone 11" 10 "Zone 10" 9 "Zone 9" 8 "Zone 8" 7 "Zone 7" 6 "Zone 6" 5 "Zone 5" 4 "Zone 4" 3 "Zone 3" 2 "Zone 2" 1 "Zone 1" 0 "No Object" ;
VAL_TABLE_ PAFrtRgn2ObjStat 15 "Zone 15" 14 "Zone 14" 13 "Zone 13" 12 "Zone 12" 11 "Zone 11" 10 "Zone 10" 9 "Zone 9" 8 "Zone 8" 7 "Zone 7" 6 "Zone 6" 5 "Zone 5" 4 "Zone 4" 3 "Zone 3" 2 "Zone 2" 1 "Zone 1" 0 "No Object" ;
VAL_TABLE_ PAFrtRgn1ObjStat 15 "Zone 15" 14 "Zone 14" 13 "Zone 13" 12 "Zone 12" 11 "Zone 11" 10 "Zone 10" 9 "Zone 9" 8 "Zone 8" 7 "Zone 7" 6 "Zone 6" 5 "Zone 5" 4 "Zone 4" 3 "Zone 3" 2 "Zone 2" 1 "Zone 1" 0 "No Object" ;
VAL_TABLE_ LDWIC_LnDepWAWLn 2 "Right Front Speaker" 1 "Left Front Speaker" 0 "Off" ;
VAL_TABLE_ LDWIC_IndReq 2 "Flash Rate #1 Indication" 1 "Continuous Indication" 0 "Off" ;
VAL_TABLE_ PassHCSMIndReq 3 "Flash Rate #2 Indication" 2 "Flash Rate #1 Indication" 1 "Continuous Indication" 0 "Off" ;
VAL_TABLE_ PassHCSLIndReq 3 "Flash Rate #2 Indication" 2 "Flash Rate #1 Indication" 1 "Continuous Indication" 0 "Off" ;
VAL_TABLE_ DrvHCSMIndReq 3 "Flash Rate #2 Indication" 2 "Flash Rate #1 Indication" 1 "Continuous Indication" 0 "Off" ;
VAL_TABLE_ DrvHCSLIndReq 3 "Flash Rate #2 Indication" 2 "Flash Rate #1 Indication" 1 "Continuous Indication" 0 "Off" ;
VAL_TABLE_ MmryRclImpctDisRq 1 "Disable Recall" 0 "Enable Recall" ;
VAL_TABLE_ HdSt 2 "Open" 1 "Ajar" 0 "Closed" ;
VAL_TABLE_ CmpsOctHdingDataSrc 1 "Calculated Value" 0 "Stored Value" ;
VAL_TABLE_ CmpsOctHding 7 "NW (North West)" 6 "W (West)" 5 "SW (South West)" 4 "S (South)" 3 "SE (South East)" 2 "E (East)" 1 "NE (North East)" 0 "N (North)" ;
VAL_TABLE_ CmpsDecZone 15 "Zone 15" 14 "Zone 14" 13 "Zone 13" 12 "Zone 12" 11 "Zone 11" 10 "Zone 10" 9 "Zone 9" 8 "Zone 8" 7 "Zone 7" 6 "Zone 6" 5 "Zone 5" 4 "Zone 4" 3 "Zone 3" 2 "Zone 2" 1 "Zone 1" 0 "Unknown" ;
VAL_TABLE_ EnvIdRspSt1 3 "Environment_id_request" 2 "Incorrect_immo_id" 1 "Info_valid" 0 "No_info" ;
VAL_TABLE_ FrPsSeatOccFltSt 2 "Fault Present - Vehicle Mismatch" 1 "Fault Present" 0 "No Faults Present" ;
VAL_TABLE_ FrPsSeatOccSnsOpMd 3 "SystemInitMod" 2 "BarrierMod" 1 "ZeroSetCheckMod" 0 "FieldMod" ;
VAL_TABLE_ PhnSpRcgnApSt 3 "Unused" 2 "Audio Prompt Active" 1 "Speech Rec Active" 0 "Inactive" ;
VAL_TABLE_ PhnSpRcgnRq 3 "Stop" 2 "Move On / Skip" 1 "Start" 0 "No Action" ;
VAL_TABLE_ CmpsModSlfTstReq 1 "Initiate Self Test" 0 "No Action" ;
VAL_TABLE_ CmpsModManCalReq 1 "Calibrate Sensor" 0 "No Action" ;
VAL_TABLE_ CmpsDecZonSetReq 1 "Set New Zone" 0 "No Request" ;
VAL_TABLE_ CmpsDecZonCmndVal 15 "Zone 15" 14 "Zone 14" 13 "Zone 13" 12 "Zone 12" 11 "Zone 11" 10 "Zone 10" 9 "Zone 9" 8 "Zone 8" 7 "Zone 7" 6 "Zone 6" 5 "Zone 5" 4 "Zone 4" 3 "Zone 3" 2 "Zone 2" 1 "Zone 1" 0 "Unknown" ;
VAL_TABLE_ AuxHtrRq 1 "On" 0 "Off" ;
VAL_TABLE_ TrnsEngdState 3 "Operating State Not Reached" 2 "Transmission Engaged in Reverse" 1 "Transmission Engaged in Forward" 0 "Transmission Not Engaged" ;
VAL_TABLE_ EnhSrvVisAlRq 3 "Repeated Flash" 2 "Single Flash" 1 "Off" 0 "No Action" ;
VAL_TABLE_ EnhSrvRmStrtRq 2 "Engine Requested On" 1 "Engine Requested Off" 0 "No Activation" ;
VAL_TABLE_ EnhSrvRClsRlsRq 1 "Release" 0 "No Action" ;
VAL_TABLE_ EnhSrvLckRq 5 "Undeadbolt All" 4 "Deadbolt All" 3 "Unlock All" 2 "Unlock Driver Door" 1 "Lock All" 0 "No Action" ;
VAL_TABLE_ EnhSrvAudAlRq 3 "Alarm" 2 "Chirp" 1 "Off" 0 "No Action" ;
VAL_TABLE_ EPBSysDspMsgReq 7 "Message #7" 6 "Message #6" 5 "Message #5" 4 "Message #4" 3 "Message #3" 2 "Message #2" 1 "Message #1" 0 "Off" ;
VAL_TABLE_ VhSecNImmoIndRq 2 "Flashing Indication" 1 "Continuous Indication" 0 "No Indication" ;
VAL_TABLE_ FPSIC_IndPer 15 "8.0 s" 14 "7.0 s" 13 "6.0 s" 12 "5.0 s" 11 "4.0 s" 10 "3.5 s" 9 "3.0 s" 8 "2.5 s" 7 "2.0 s" 6 "1.75 s" 5 "1.50 s" 4 "1.25 s" 3 "1.0 s" 2 "0.75 s" 1 "0.5 s" 0 "0.25 s" ;
VAL_TABLE_ FDSIC_IndPer 15 "8.0 s" 14 "7.0 s" 13 "6.0 s" 12 "5.0 s" 11 "4.0 s" 10 "3.5 s" 9 "3.0 s" 8 "2.5 s" 7 "2.0 s" 6 "1.75 s" 5 "1.50 s" 4 "1.25 s" 3 "1.0 s" 2 "0.75 s" 1 "0.5 s" 0 "0.25 s" ;
VAL_TABLE_ FsnPsStbAuxIR 4 "Child Warning Level 2" 3 "Child Warning Level 1" 2 "Adult Warning Level 2" 1 "Adult Warning Level 1" 0 "No Indication" ;
VAL_TABLE_ FstnSndRwRtPsStbtInR 3 "Unbuckled information indication" 2 "Buckled Indication" 1 "Unbuckled Indication" 0 "No Indication" ;
VAL_TABLE_ FstnSndRwLtPsStbtInR 3 "Unbuckled information indication" 2 "Buckled Indication" 1 "Unbuckled Indication" 0 "No Indication" ;
VAL_TABLE_ FstnSndRwCtPsStbtInR 3 "Unbuckled information indication" 2 "Buckled Indication" 1 "Unbuckled Indication" 0 "No Indication" ;
VAL_TABLE_ FsnDrStbAuxIR 2 "Warning Level 2" 1 "Warning Level 1" 0 "No Indication" ;
VAL_TABLE_ BackgroundFlag 1 "Background response" 0 "Immediate response required" ;
VAL_TABLE_ TrRrAxlPresStat 2 "Tire Pressure Imbalance Warning" 1 "Tire Pressure Balanced" 0 "Unknown" ;
VAL_TABLE_ TrFrntAxlPresStat 2 "Tire Pressure Imbalance Warning" 1 "Tire Pressure Balanced" 0 "Unknown" ;
VAL_TABLE_ DisplayMaskId 128 "Reserved" 64 "Reserved" 32 "OTIM" 16 "RearDisplayTwo" 8 "RearDisplayOne" 4 "AuxIP" 2 "CenterStack" 1 "IPC" ;
VAL_TABLE_ ODIReqType 0 "Subscribe: FU sends DynData back and then on change) " 1 "Unsubscribe: cancel previous Subscribe" ;
VAL_TABLE_ OtsdAmbtLtLvlStat 2 "Day" 1 "Night" 0 "Unknown" ;
VAL_TABLE_ ASSAudSrcStatCode 5 "Producing Audio" 4 "Producing Silence" 3 "Reserved" 2 "Audio Not Available" 1 "Audio Available" 0 "Device Present" ;
VAL_TABLE_ ASSAudSrcChType 4 "Mono Emergency" 3 "Mixed" 2 "Stereo" 1 "Mono" 0 "No Action" ;
VAL_TABLE_ ASSAudSrcType 28 "Phone" 24 "Sat. Digital Audio Receiver System" 20 "Digital Audio Broadcast" 16 "Remote CD Changer" 12 "Remote Digital Video Disk" 8 "Auxiliary Device" 1 "Television Tuner" ;
VAL_TABLE_ ASS2AudSrcStatCode 5 "Producing Audio" 4 "Producing Silence" 3 "Reserved" 2 "Audio Not Available" 1 "Audio Available" 0 "Device Present" ;
VAL_TABLE_ ASS2AudSrcChType 4 "Mono Emergency" 3 "Mixed" 2 "Stereo" 1 "Mono" 0 "No Action" ;
VAL_TABLE_ RdSpdCatType 3 "all speed categories 0 - 50 km/h" 2 "all speed categories 51-80 km/h" 1 "all speed categories 81-130 km/h" 0 "all speed categories > 130 km/h" ;
VAL_TABLE_ LnCat 3 "Four Or More Lanes" 2 "Two Or Three Lanes" 1 "One lane" 0 "no info available" ;
VAL_TABLE_ FncRdClass 7 "COLLECTOR" 6 "ALLEY" 5 "ARTERIAL" 4 "HIGHWAY" 3 "PED-MALL" 2 "FREEWAY" 1 "SFREEWAY" 0 "LOCAL (Residential Road)" ;
VAL_TABLE_ CustomizationSettingRequest 7 "Auto" 6 "Performance Mode 6" 5 "Performance Mode 5" 4 "Performance Mode 4" 3 "Performance Mode 3" 2 "Performance Mode 2" 1 "Performance Mode 1" 0 "No Action" ;
VAL_TABLE_ RstrCustFctrDef 1 "Restore Defaults" 0 "No Action" ;
VAL_TABLE_ AdvFrntLghtSysIndRq 7 "Indication 7" 6 "Indication 6" 5 "Indication 5" 4 "Indication 4" 3 "Indication 3" 2 "Indication 2" 1 "Indication 1" 0 "No Indication" ;
VAL_TABLE_ CustomizationCurrentSettingValue 7 "Auto" 6 "Performance Mode 6" 5 "Performance Mode 5" 4 "Performance Mode 4" 3 "Performance Mode 3" 0 "No Action" 1 "Performance Mode 1" 2 "Performance Mode 2" ;
VAL_TABLE_ PsvStrtStrngClmnLckTT 2 "Flashing Indication" 1 "Continous Indication" 0 "No indication" ;
VAL_TABLE_ StrngClmnLckTT 2 "Flashing Indication" 1 "Continous Indication" 0 "No indication" ;
VAL_TABLE_ ODIDataType 21 "Bitmap" 20 "DecimalShort" 19 "HoursOfDay" 18 "Character" 17 "Fuel Consumption Inverted" 16 "Fuel Consumption" 15 "Pressure" 14 "Temperature" 13 "Volume" 12 "DistanceShort" 11 "DistanceLong" 10 "BitmapId" 9 "TextId" 8 "Pictogram" 7 "List " 6 "Date" 5 "Time " 4 "Decimal" 3 "EnumerationValue" 2 "Integer" 1 "String" 0 "Speed" ;
VAL_TABLE_ TimeDispFormat 1 "24 hour mode" 0 "12 hour mode" ;
VAL_TABLE_ EPBSysStatIndReq 3 "Flash Rate 2 Indication" 2 "Flash Rate 1 Indication" 1 "Continuous Indication" 0 "No Indication" ;
VAL_TABLE_ VcRecVcFdbckSt 1 "Active" 0 "Inactive" ;
VAL_TABLE_ ClntCircPmpRq 1 "On" 0 "Off" ;
VAL_TABLE_ InfMdSt 7 "Data Unavailable" 6 "Cancel Request" 5 "OTA Transfer Failed" 4 "Data Transfer Failed" 3 "Data Transfer Complete" 2 "Not Ready" 1 "Ready" 0 "No Action" ;
VAL_TABLE_ ImoIdSt 1 "Info valid" 0 "No info" ;
VAL_TABLE_ A2ERRAlrmReq 2 "Cancel Alarm" 1 "Set Alarm" 0 "No Action" ;
VAL_TABLE_ A1ERRAlrmReq 2 "Cancel Alarm" 1 "Set Alarm" 0 "No Action" ;
VAL_TABLE_ LrnEnvIdSt 1 "Info_valid" 0 "No_info" ;
VAL_TABLE_ EnvIdRspSt3 3 "Environment_id_request" 2 "Incorrect_immo_id" 1 "Info_valid" 0 "No_info" ;
VAL_TABLE_ EnvIdRspSt2 3 "Environment_id_request" 2 "Incorrect_immo_id" 1 "Info_valid" 0 "No_info" ;
VAL_TABLE_ VDAvailability 1 "VirtualDeviceAvailable" 0 "VirtualDeviceUnavailable" ;
VAL_TABLE_ RemStrtSt 1 "Active" 0 "Inactive" ;
VAL_TABLE_ EhnSrvEngImmStat 1 "Immobilized" 0 "Not Immobilized" ;
VAL_TABLE_ AlrmStat 4 "Arming Delay" 3 "Alarm Active" 2 "Disarmed" 1 "Armed" 0 "Off" ;
VAL_TABLE_ DrIdDevLrnd 1 "Learned" 0 "Not Learned" ;
VAL_TABLE_ StrgWhlUnit1SwStat 15 "Function #F" 14 "Function #E" 13 "Function #D" 12 "Function #C" 11 "Function #B" 10 "Function #A" 9 "Function #9" 8 "Function #8" 7 "Function #7" 6 "Function #6" 5 "Function #5" 4 "Function #4" 3 "Function #3" 2 "Function #2" 1 "Function #1" 0 "No Activation" ;
VAL_TABLE_ AirbgICIndPer 15 "8.0 s" 14 "7.0 s" 13 "6.0 s" 12 "5.0 s" 11 "4.0 s" 10 "3.5 s" 9 "3.0 s" 8 "2.5 s" 7 "2.0 s" 6 "1.75" 5 "1.5 s" 4 "1.25 s" 3 "1.0 s" 2 ".75 s" 1 ".5 s" 0 "0.25 s" ;
VAL_TABLE_ CLRAF_Unl_Lk 4 "Un-double Lock" 3 "Double Lock" 2 "Lock" 1 "Unlock" 0 "No Command" ;
VAL_TABLE_ CLRAF_ActFunc 11 "Exterior Lock Switch" 10 "Lockout Prevention" 9 "Re-locking" 8 "Delayed Locking" 7 "Enhanced Services/Telematics" 6 "Passive Remote Keyfob" 5 "Active Remote Keyfob" 4 "Emergency" 3 "Rr Closure Key Cylinder/Release Sw" 2 "Driver Door Key Cylinder" 1 "Power Door Lock Switch" 0 "Auto Door Lock" ;
VAL_TABLE_ StrgWhlUnit2SwStat 15 "Function #F" 14 "Function #E" 13 "Function #D" 12 "Function #C" 11 "Function #B" 10 "Function #A" 9 "Function #9" 8 "Function #8" 7 "Function #7" 6 "Function #6" 5 "Function #5" 4 "Function #4" 3 "Function #3" 2 "Function #2" 1 "Function #1" 0 "No Activation" ;
VAL_TABLE_ RadConInfReqSrc 2 "Infotainment Head" 1 "Rear Seat Entertainment" 0 "Voice Recognition System" ;
VAL_TABLE_ RadConInfCmd 3 "Purchase" 2 "Store" 1 "Mark" 0 "No Action" ;
VAL_TABLE_ RadBrdcstSrc 2 "FM" 1 "AM" 0 "Satellite Digital Audio Receiver" ;
VAL_TABLE_ RstVTDTmprDtctd 1 "Reset" 0 "No Action" ;
VAL_TABLE_ RstIllDrIdDevDtctd 1 "Reset" 0 "No Action" ;
VAL_TABLE_ RstDrIdDevLrnd 1 "Reset" 0 "No Action" ;
VAL_TABLE_ ESEIC_EngImmbRq 1 "Immobilize" 0 "Do Not Immobilize" ;
VAL_TABLE_ CldrMth 12 "December" 11 "November" 10 "October" 9 "September" 8 "August" 7 "July" 6 "June" 5 "May" 4 "April" 3 "March" 2 "February" 1 "January" 0 "Unknown" ;
VAL_TABLE_ FobProgMdStat 2 "Complete" 1 "Active" 0 "Inactive" ;
VAL_TABLE_ RmtCntFobNm 5 "Remote Control Fob #5" 4 "Remote Control Fob #4" 3 "Remote Control Fob #3" 2 "Remote Control Fob #2" 1 "Remote Control Fob #1" 0 "No Fob" ;
VAL_TABLE_ ACHtIdleBstLevReq 3 "Boost Level 3" 2 "Boost Level 2" 1 "Boost Level 1" 0 "No Boost Requested" ;
VAL_TABLE_ RmStrHtdStEnRq 1 "Enable Heated Seat" 0 "Disable Heated Seat" ;
VAL_TABLE_ BattVltIRq 3 "Battery Voltage Very Low" 2 "Battery Voltage High" 1 "Battery Voltage Low" 0 "Battery Voltage OK" ;
VAL_TABLE_ TrnSwAct 2 "Right" 1 "Left" 0 "No Activation" ;
VAL_TABLE_ RtTrnLmpAtv 2 "On with telltale" 1 "On without telltale" 0 "Off" ;
VAL_TABLE_ LftTrnLmpAtv 2 "On with telltale" 1 "On without telltale" 0 "Off" ;
VAL_TABLE_ RmtCntrlFobFnc 31 "Charge Termination" 30 "Pwr Top Control Start Motion Contrl" 29 "Pwr Top Control Stop Motion Control" 28 "Comfort Close 2" 27 "Comfort Open 2" 26 "Connectivity Request" 25 "Comfort Close" 24 "Comfort Open" 23 "Right Sliding Dr Stop Motion Contrl" 22 "Left Sliding Dr Stop Motion Control" 21 "Pwr Rr Closure Start Motion Control" 20 "Pwr Rr Closure Stop Motion Control" 19 "All Door Double Lock" 18 "Pwr Rr Closure Stop While Opening" 17 "Pwr Rr Closure Stop While Closing" 16 "Power Rear Closure Open Control" 15 "Power Rear Closure Close Control" 14 "Locator Alarm Control" 13 "Fob Programmed" 12 "Engine Stop" 11 "Engine Run" 10 "Power Top Control" 9 "Power Window Control" 8 "Fuel Door Control" 7 "Panic Alarm Control" 6 "Right Sliding Door Control" 5 "Left Sliding Door Control" 4 "Rear Closure Control" 3 "All Door Unlock" 2 "Driver Door Unlock" 1 "Lock" 0 "No Activation" ;
VAL_TABLE_ AutoBmSlctStat 2 "High Beam" 1 "Low  Beam" 0 "Disabled" ;
VAL_TABLE_ StrgColLckCmd 3 "Failure Code Retrieval Required" 2 "Lock" 1 "Unlock" 0 "No Command" ;
VAL_TABLE_ VehHghtStat 4 "Maximum Height" 3 "Kneeling Height" 2 "Aerodynamic Height" 1 "Normal Design Ride Height" 0 "Unknown" ;
VAL_TABLE_ HdlmpBmSelectStat 2 "High Beams" 1 "Low Beams" 0 "Unknown" ;
VAL_TABLE_ ACSAlarm9 2 "Expired" 1 "Active" 0 "Inactive" ;
VAL_TABLE_ ACSAlarm8 2 "Expired" 1 "Active" 0 "Inactive" ;
VAL_TABLE_ ACSAlarm7 2 "Expired" 1 "Active" 0 "Inactive" ;
VAL_TABLE_ ACSAlarm6 2 "Expired" 1 "Active" 0 "Inactive" ;
VAL_TABLE_ ACSAlarm5 2 "Expired" 1 "Active" 0 "Inactive" ;
VAL_TABLE_ ACSAlarm4 2 "Expired" 1 "Active" 0 "Inactive" ;
VAL_TABLE_ ACSAlarm3 2 "Expired" 1 "Active" 0 "Inactive" ;
VAL_TABLE_ ACSAlarm2 2 "Expired" 1 "Active" 0 "Inactive" ;
VAL_TABLE_ ACSAlarm15 2 "Expired" 1 "Active" 0 "Inactive" ;
VAL_TABLE_ ACSAlarm14 2 "Expired" 1 "Active" 0 "Inactive" ;
VAL_TABLE_ ACSAlarm13 2 "Expired" 1 "Active" 0 "Inactive" ;
VAL_TABLE_ ACSAlarm12 2 "Expired" 1 "Active" 0 "Inactive" ;
VAL_TABLE_ ACSAlarm11 2 "Expired" 1 "Active" 0 "Inactive" ;
VAL_TABLE_ ACSAlarm10 2 "Expired" 1 "Active" 0 "Inactive" ;
VAL_TABLE_ ACSAlarm1 2 "Expired" 1 "Active" 0 "Inactive" ;
VAL_TABLE_ ACSAlarm0 2 "Expired" 1 "Active" 0 "Inactive" ;
VAL_TABLE_ ACCHdwyStg 7 "Headway Setting 7" 6 "Headway Setting 6" 5 "Headway Setting 5" 4 "Headway Setting 4" 3 "Headway Setting 3" 2 "Headway Setting 2" 1 "Headway Setting 1" 0 "Minimum Headway Setting" ;
VAL_TABLE_ VehStabEnhmntMd 2 "Competitive" 1 "Normal" 0 "Off" ;
VAL_TABLE_ VehStabEnhmntStat 4 "Not Ready" 3 "Warming Up" 2 "Fault" 1 "Active" 0 "Inactive" ;
VAL_TABLE_ TCSysOpMd 2 "Off Road" 1 "Normal" 0 "Off" ;
VAL_TABLE_ TCSysOpStat 2 "Fault" 1 "Active" 0 "Inactive" ;
VAL_TABLE_ HillDscntCntlSysStat 4 "Temporarily Inhibited" 3 "Failed" 2 "Active" 1 "Enabled" 0 "Normal" ;
VAL_TABLE_ EnrgMgtLdShdRq 4 "Load Shed Level 4" 3 "Load Shed Level 3" 2 "Load Shed Level 2" 1 "Load Shed Level 1" 0 "No Load Shedding" ;
VAL_TABLE_ DrId 7 "Unknown" 6 "Driver #7" 5 "Driver #6" 4 "Driver #5" 3 "Driver #4" 2 "Driver #3" 1 "Driver #2" 0 "Driver #1" ;
VAL_TABLE_ TireRRPrsStat 5 "High" 4 "Low - Extended Mobility" 3 "Low" 2 "Low - Service Now" 1 "Nominal" 0 "Unknown" ;
VAL_TABLE_ TireRFPrsStat 5 "High" 4 "Low - Extended Mobility" 3 "Low" 2 "Low - Service Now" 1 "Nominal" 0 "Unknown" ;
VAL_TABLE_ TireLRPrsStat 5 "High" 4 "Low - Extended Mobility" 3 "Low" 2 "Low - Service Now" 1 "Nominal" 0 "Unknown" ;
VAL_TABLE_ TireLFPrsStat 5 "High" 4 "Low - Extended Mobility" 3 "Low" 2 "Low - Service Now" 1 "Nominal" 0 "Unknown" ;
VAL_TABLE_ SC_SndTne 10 "Beep (750 Hz) Radio Source Muted" 9 "High Frequency Broadband" 8 "Harp" 7 "Gong (2000 Hz)" 6 "Gong (750 Hz)" 5 "Beep (2000 Hz)" 4 "Beep (750 Hz)" 3 "Click-Clack" 2 "Click" 1 "Clack" 0 "Clock" 14 "No Chime with Radio Source Muted" 13 "Gong (2000 Hz) Radio Source Muted" 12 "Gong (750 Hz) Radio Source Muted" 11 "Beep (2000 Hz) Radio Source Muted" ;
VAL_TABLE_ DTCI_DTCFaultType 3 "Type C" 2 "Type B" 1 "Type A" 0 "Not Supported" ;
VAL_TABLE_ DistRollCntAvgDrvnSrc 1 "Wheel Speed" 0 "Transmission Output Speed" ;
VAL_TABLE_ VehSpdAvgDrvnSrc 1 "Wheel Speed" 0 "Transmission Output Speed" ;
VAL_TABLE_ TrnsThrmlMngmntStat 2 "Driver Intervention Requested" 1 "Countermeasures Active" 0 "Normal" ;
VAL_TABLE_ TrnsSftMdStat 3 "Automatic Grade Braking Mode" 2 "Lift-Foot Cornering Mode" 1 "Performance Mode" 0 "No Override Mode" ;
VAL_TABLE_ TrnsRngInhbtStat 4 "Diagnostic Inhibit Active" 3 "Driveline Not Engaged" 2 "Transmission Range Re-Selection Req" 1 "Transmission Inhibit Active" 0 "No Range Inhibit Active" ;
VAL_TABLE_ DrvtShftCntrlTrgtGear 10 "Tenth Gear" 9 "Ninth Gear" 8 "Eighth Gear" 7 "Seventh Gear" 6 "Sixth Gear" 5 "Fifth Gear" 4 "Fourth Gear" 3 "Third Gear" 2 "Second Gear" 1 "First Gear" 0 "Not Supported" ;
VAL_TABLE_ StrWhlAngSenCalStat 2 "Calibrated" 1 "Estimated" 0 "Unknown" ;
VAL_TABLE_ OAT_PT_EstM 1 "Use Data" 0 "Don't Use Data" ;
VAL_TABLE_ ACCompCmnd 1 "On" 0 "Off" ;
VAL_TABLE_ EngEmsRelMalfIndReq 4 "Flashing 0.5 Hertz Indication" 3 "Flashing 2 Hertz Indication" 2 "Flashing 1 Hertz Indication" 1 "No Indication" 0 "Continuous Indication" ;
VAL_TABLE_ EngCylDeactMd 3 "Reactivation In Progress" 2 "Half of Total Cylinders Active" 1 "Deactivation In Progress" 0 "All Cylinders Active" ;
VAL_TABLE_ EngSpdStat 3 "Invalid" 1 "Degraded Operation" 0 "Normal Operation" ;
VAL_TABLE_ DispMeasSys 1 "English" 0 "Metric" ;
VAL_TABLE_ ACCompModReq 3 "No Action" 2 "Engage" 1 "Disengage" 0 "Disengage Immediately" ;
VAL_TABLE_ TransNtrlCntrlMdStat 3 "Exiting Neutral Control" 2 "Neutral Control Active" 1 "Entering Neutral Control" 0 "Neutral Control Not Active" ;
VAL_TABLE_ TrnsShftLvrPos 13 "Forward Range J" 12 "Froward Range I" 15 "Lever Position Unknown" 11 "Forward Range H" 10 "Forward Range G" 9 "Forward Range F" 8 "Forward Range E" 7 "Forward Range D" 6 "Forward Range C" 5 "Forward Range B" 4 "Forward Range A" 3 "Neutral Range" 2 "Reverse Range" 1 "Park Range" 0 "Between Ranges" ;
VAL_TABLE_ AutoTransComndGear 9 "Ninth Gear" 15 "Park Gear" 14 "Reverse Gear" 13 "Neutral Gear" 12 "CVT Forward Gear" 11 "Unused and Reserved" 10 "Tenth Gear" 8 "Eighth Gear" 7 "Seventh Gear" 6 "Sixth Gear" 5 "Fifth Gear" 4 "Fourth Gear" 3 "Third Gear" 2 "Second Gear" 1 "First Gear" 0 "Not Supported" ;
VAL_TABLE_ TransEstGear 9 "Ninth Gear" 15 "Park Gear" 14 "Reverse Gear" 13 "Neutral Gear" 12 "CVT Forward Gear" 11 "Unused and Reserved" 10 "Tenth Gear" 8 "Eighth Gear" 7 "Seventh Gear" 6 "Sixth Gear" 5 "Fifth Gear" 4 "Fourth Gear" 3 "Third Gear" 2 "Second Gear" 1 "First Gear" 0 "Not Supported" ;
VAL_TABLE_ RmVehStrRq 1 "Remote Start Requested" 0 "Remote Start Not Requested" ;
VAL_TABLE_ VehSpdCntlSystmType 2 "Adaptive Cruise Control" 1 "Conventional Cruise Control" 0 "No Vehicle Speed Control" ;
VAL_TABLE_ SysBkUpPwrMd 3 "Crank Request" 2 "Run" 1 "Accessory" 0 "Off" ;
VAL_TABLE_ SysPwrMd 3 "Crank Request" 2 "Run" 1 "Accessory" 0 "Off" ;
VAL_TABLE_ AdptCrsGapSwAct 2 "Increase Gap" 1 "Decrease Gap" 0 "No Activation" ;
VAL_TABLE_ CrsCntrlSwStSwDataIntgty 3 "Illegal Range" 2 "Failure Detected" 1 "Data Invalid" 0 "Data Valid" ;
VAL_TABLE_ SprTireSt 2 "Spare Detected" 1 "No Spare Detected" 0 "Undetermined" ;
VAL_TABLE_ ValidityStates 1 "Invalid" 0 "Valid" ;
VAL_TABLE_ MainLghtSw 3 "HEADLAMP" 2 "PARKLAMP" 1 "OFF" 0 "AUTO" ;
VAL_TABLE_ AudMstrSrcTyp 28 "Phone" 24 "Sat. Digital Audio Receiver System" 20 "Digital Audio Broadcast" 16 "Remote CD Changer" 12 "Remote Digital Video Disk" 8 "Auxiliary Device" 1 "Television Tuner" 0 "Audio Supervisor" ;
VAL_TABLE_ AudMstrChnnlTyp 3 "Mixed" 2 "Stereo" 1 "Mono" 0 "No Channel" ;
VAL_TABLE_ AudMstrArbCom 4 "Connection Complete" 3 "Disconnect" 2 "Connect" 1 "Do Not Connect" 0 "No Action" ;
VAL_TABLE_ RrWndDfgInhRq 1 "Inhibit rear window defog" 0 "Allow rear window defog" ;

BO_ 2152079360 Dist_Trvld_Data_Extd_LS: 3 VICM_LS
 SG_ BattPrpDstTrvldExtd : 1|18@0+ (0.07629376,0) [0|19999.875] "km"  CSM_LS,CGM_LS,RadioHead_LS

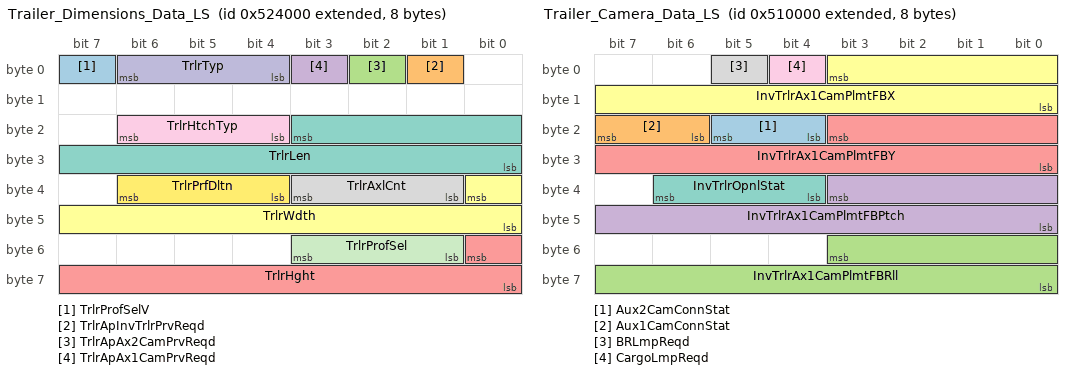
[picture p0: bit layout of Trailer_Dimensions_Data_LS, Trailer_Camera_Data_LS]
BO_ 2152873984 Trailer_Dimensions_Data_LS: 8 RadioHead_LS
 SG_ TrlrProfSelV : 7|1@0+ (1,0) [0|1] ""  SBZA_R_LS,SBZA_L_LS,UPA_LS,APA_LS
 SG_ TrlrApInvTrlrPrvReqd : 1|1@0+ (1,0) [0|1] ""  VPM_LS
 SG_ TrlrApAx2CamPrvReqd : 2|1@0+ (1,0) [0|1] ""  VPM_LS
 SG_ TrlrApAx1CamPrvReqd : 3|1@0+ (1,0) [0|1] ""  VPM_LS
 SG_ TrlrHght : 48|9@0+ (1,0) [0|450] "cm"  VPM_LS
 SG_ TrlrWdth : 32|9@0+ (1,0) [0|300] "cm"  VPM_LS
 SG_ TrlrLen : 19|12@0+ (1,0) [0|2500] "cm"  VPM_LS
 SG_ TrlrAxlCnt : 35|3@0+ (1,0) [0|7] ""  VPM_LS
 SG_ TrlrHtchTyp : 22|3@0+ (1,0) [0|7] ""  VPM_LS
 SG_ TrlrTyp : 6|3@0+ (1,0) [0|7] ""  VPM_LS
 SG_ TrlrProfSel : 51|3@0+ (1,0) [0|7] ""  SBZA_R_LS,SBZA_L_LS,UPA_LS,APA_LS,VPM_LS
 SG_ TrlrPrfDltn : 38|3@0+ (1,0) [0|7] ""  VPM_LS

BO_ 2152792064 Trailer_Camera_Data_LS: 8 CGM_LS
 SG_ Aux2CamConnStat : 21|2@0+ (1,0) [0|3] ""  CSM_LS,RadioHead_LS
 SG_ Aux1CamConnStat : 23|2@0+ (1,0) [0|3] ""  CSM_LS,RadioHead_LS
 SG_ InvTrlrAx1CamPlmtFBRll : 51|12@0- (0.1,0) [-180|180] "deg"  CSM_LS,RadioHead_LS
 SG_ InvTrlrAx1CamPlmtFBPtch : 35|12@0- (0.1,0) [-180|180] "deg"  CSM_LS,RadioHead_LS
 SG_ InvTrlrAx1CamPlmtFBY : 19|12@0- (0.1,0) [-200|200] "cm"  CSM_LS,RadioHead_LS
 SG_ InvTrlrAx1CamPlmtFBX : 3|12@0- (0.1,0) [-150|150] "cm"  CSM_LS,RadioHead_LS
 SG_ InvTrlrOpnlStat : 38|3@0+ (1,0) [0|7] ""  CSM_LS,RadioHead_LS
 SG_ BRLmpReqd : 5|1@0+ (1,0) [0|1] ""  BCM_LS
 SG_ CargoLmpReqd : 4|1@0+ (1,0) [0|1] ""  BCM_LS

BO_ 2154610688 Clean_Screen_Active_LS: 1 CSM_LS
 SG_ ClnScrnAct : 7|1@0+ (1,0) [0|1] ""  CGM_LS,AMP_LS

BO_ 2150694912 Target_Charge_Level_LS: 2 RadioHead_LS
 SG_ TrgtChrgLvlPrctgStReqHme : 12|5@0+ (1,0) [0|20] ""  VICM_LS
 SG_ TrgtChrgLvlPrctgStReq : 4|5@0+ (1,0) [0|20] ""  VICM_LS

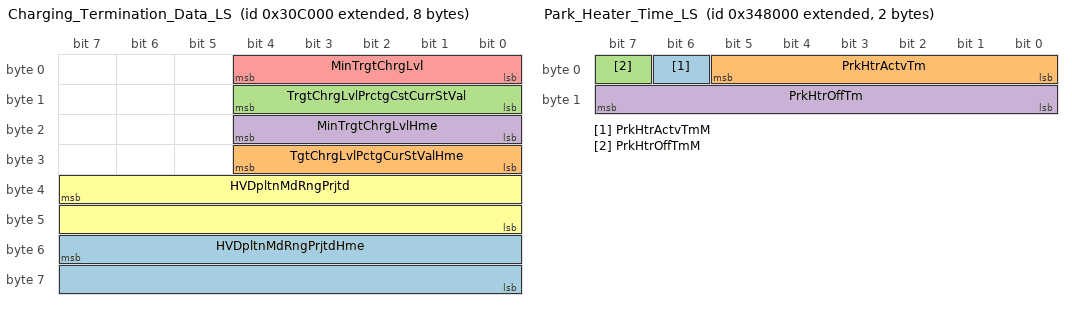
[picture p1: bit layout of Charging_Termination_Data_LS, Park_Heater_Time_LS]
BO_ 2150678528 Charging_Termination_Data_LS: 8 VICM_LS
 SG_ HVDpltnMdRngPrjtdHme : 55|16@0+ (0.015625,0) [0|1023.984375] "km"  CSM_LS,CGM_LS,RadioHead_LS
 SG_ TgtChrgLvlPctgCurStValHme : 28|5@0+ (1,0) [0|20] ""  CSM_LS,CGM_LS,RadioHead_LS
 SG_ TrgtChrgLvlPrctgCstCurrStVal : 12|5@0+ (1,0) [0|20] ""  CSM_LS,CGM_LS,RadioHead_LS
 SG_ MinTrgtChrgLvlHme : 20|5@0+ (1,0) [0|20] ""  CSM_LS,CGM_LS,RadioHead_LS
 SG_ MinTrgtChrgLvl : 4|5@0+ (1,0) [0|20] ""  CSM_LS,CGM_LS,RadioHead_LS
 SG_ HVDpltnMdRngPrjtd : 39|16@0+ (0.015625,0) [0|1023.984375] "km"  CSM_LS,CGM_LS,RadioHead_LS

BO_ 946 Temp_Diag_CAN_Resp_LS_3B2: 8 Dummy_LS
 SG_ DgnInf : 7|64@0+ (1,0) [0|1.84467440737096E+019] ""  CGM_LS

BO_ 178 Temp_Diag_CAN_Req_LS_0B2: 8 CGM_LS
 SG_ DgnInf : 7|64@0+ (1,0) [0|1.84467440737096E+019] ""  Dummy_LS

BO_ 2150924288 Park_Heater_Time_LS: 2 PHS_LS
 SG_ PrkHtrActvTmM : 6|1@0+ (1,0) [0|1] ""  CGM_LS,BCM_LS
 SG_ PrkHtrActvTm : 5|6@0+ (1,0) [0|63] "min"  CGM_LS,BCM_LS
 SG_ PrkHtrOffTmM : 7|1@0+ (1,0) [0|1] ""  CGM_LS,BCM_LS
 SG_ PrkHtrOffTm : 15|8@0+ (2,0) [0|510] "min"  CGM_LS,BCM_LS

BO_ 2152062976 Thrml_Ref_Comp_Spd_Feedback_LS: 3 BCM_LS
 SG_ ThrmlRefCompStatFdbck : 3|4@0+ (1,0) [0|15] " "  CGM_LS,ECC_LS
 SG_ ThrmlRefCompSpdFdbck : 13|14@0+ (1,0) [0|16383] "rpm"  CGM_LS,ECC_LS

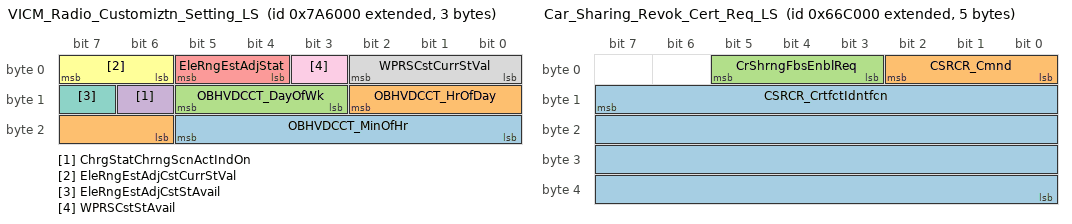
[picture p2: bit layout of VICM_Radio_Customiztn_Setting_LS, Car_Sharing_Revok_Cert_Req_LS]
BO_ 2155503616 VICM_Radio_Customiztn_Setting_LS: 3 VICM_LS
 SG_ OBHVDCCT_MinOfHr : 21|6@0+ (1,0) [0|63] ""  CGM_LS,IPC_LS,RadioHead_LS
 SG_ OBHVDCCT_HrOfDay : 10|5@0+ (1,0) [0|31] ""  CGM_LS,IPC_LS,RadioHead_LS
 SG_ OBHVDCCT_DayOfWk : 13|3@0+ (1,0) [0|7] ""  CGM_LS,IPC_LS,RadioHead_LS
 SG_ ChrgStatChrngScnActIndOn : 14|1@0+ (1,0) [0|1] ""  CGM_LS,RadioHead_LS
 SG_ EleRngEstAdjStat : 5|2@0+ (1,0) [0|3] ""  IPC_LS,CGM_LS
 SG_ EleRngEstAdjCstCurrStVal : 7|2@0+ (1,0) [0|3] ""  CGM_LS,CSM_LS,RadioHead_LS
 SG_ EleRngEstAdjCstStAvail : 15|1@0+ (1,0) [0|1] ""  CGM_LS,CSM_LS,RadioHead_LS
 SG_ WPRSCstCurrStVal : 2|3@0+ (1,0) [0|7] ""  CGM_LS,ECC_LS,CSM_LS,RadioHead_LS
 SG_ WPRSCstStAvail : 3|1@0+ (1,0) [0|1] ""  CGM_LS,CSM_LS,RadioHead_LS

BO_ 2150711296 Tachometer_Engine_Speed_LS: 4 BCM_LS
 SG_ TachEngSpd : 4|13@0+ (1,0) [0|8191] "rpm"  IPC_LS,CGM_LS

BO_ 2153406464 Power_Tailgate_Release_Info_LS: 1 PTM_LS
 SG_ RrClsrInrAjrSwAct : 6|1@0+ (1,0) [0|1] ""  IPC_LS,CGM_LS
 SG_ TlgtUnavlbleIO : 7|1@0+ (1,0) [0|1] ""  IPC_LS,CGM_LS

BO_ 2154217472 Car_Sharing_Revok_Cert_Req_LS: 5 ONSTAR_LS
 SG_ CSRCR_CrtfctIdntfcn : 15|32@0+ (1,0) [0|4294967295] ""  BCM_LS
 SG_ CSRCR_Cmnd : 2|3@0+ (1,0) [0|7] ""  BCM_LS
 SG_ CrShrngFbsEnblReq : 5|3@0+ (1,0) [0|7] ""  BCM_LS

BO_ 2154463232 Car_Sharing_Phone_Resp2_LS: 8 VKM_LS
 SG_ CrShrngPhRsp2 : 7|64@0+ (1,0) [0|1.84467440737096E+019] ""  BCM_LS

BO_ 2154446848 Car_Sharing_Phone_Resp1_LS: 8 VKM_LS
 SG_ CrShrngPhRsp1 : 7|64@0+ (1,0) [0|1.84467440737096E+019] ""  BCM_LS

BO_ 2154332160 Car_Sharing_Veh_Chlng_LS: 8 BCM_LS
 SG_ CrShrngVehChlng : 7|64@0+ (1,0) [0|1.84467440737096E+019] ""  CGM_LS,VKM_LS

BO_ 2154414080 Car_Shring_Conectn_Uniq_ID1_LS: 8 BCM_LS
 SG_ CrShrngConnUnqIdntfr1 : 7|64@0+ (1,0) [0|1.84467440737096E+019] ""  CGM_LS,VKM_LS

BO_ 2150121472 Remote_Trailer_Lighting_Req_LS: 1 TCP_LS
 SG_ RmtTrlrLtngSeqReq : 7|2@0+ (1,0) [0|3] ""  BCM_LS

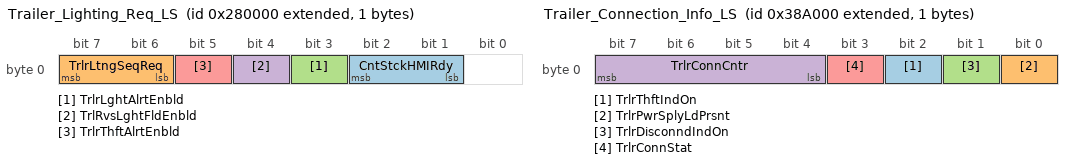
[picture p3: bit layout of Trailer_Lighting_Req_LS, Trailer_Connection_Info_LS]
BO_ 2150105088 Trailer_Lighting_Req_LS: 1 CSM_LS
 SG_ CntStckHMIRdy : 2|2@0+ (1,0) [0|3] ""  VICM_LS
 SG_ TrlrLtngSeqReq : 7|2@0+ (1,0) [0|3] ""  BCM_LS
 SG_ TrlrLghtAlrtEnbld : 3|1@0+ (1,0) [0|1] ""  TIM_B_LS,TIM_A_LS,TIM_LS
 SG_ TrlRvsLghtFldEnbld : 4|1@0+ (1,0) [0|1] ""  TIM_B_LS,TIM_A_LS,TIM_LS
 SG_ TrlrThftAlrtEnbld : 5|1@0+ (1,0) [0|1] ""  TIM_B_LS,TIM_A_LS,TIM_LS

BO_ 2151194624 Trailer_Connection_Info_LS: 1 TIM_LS
 SG_ TrlrThftIndOn : 2|1@0+ (1,0) [0|1] ""  BCM_LS,CGM_LS,CSM_LS
 SG_ TrlrPwrSplyLdPrsnt : 0|1@0+ (1,0) [0|1] ""  CSM_LS,CGM_LS
 SG_ TrlrDisconndIndOn : 1|1@0+ (1,0) [0|1] ""  CSM_LS,CGM_LS
 SG_ TrlrConnCntr : 7|4@0+ (1,0) [0|15] ""  CSM_LS,CGM_LS
 SG_ TrlrConnStat : 3|1@0+ (1,0) [0|1] ""  UPA_LS,APA_LS,SBZA_R_LS,SBZA_L_LS,VPM_LS,CSM_LS,CGM_LS

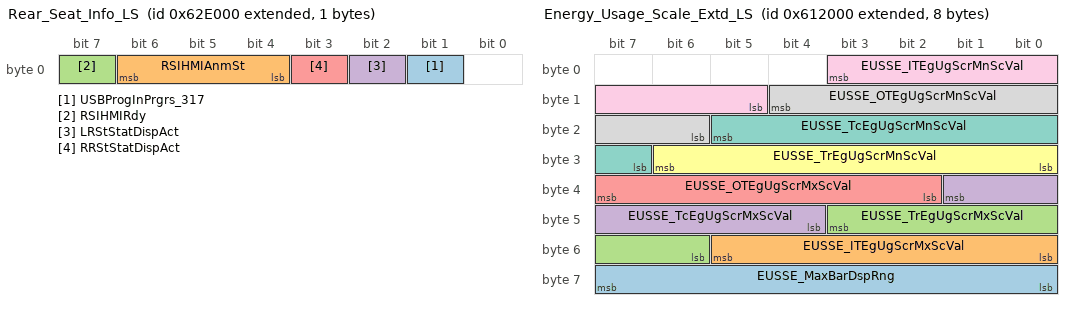
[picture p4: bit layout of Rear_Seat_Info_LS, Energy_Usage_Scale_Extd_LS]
BO_ 2153963520 Rear_Seat_Info_LS: 1 RSE_LS
 SG_ USBProgInPrgrs_317 : 1|1@0+ (1,0) [0|1] ""  IPC_LS,BCM_LS
 SG_ RSIHMIAnmSt : 6|3@0+ (1,0) [0|7] ""  IPC_LS
 SG_ RSIHMIRdy : 7|1@0+ (1,0) [0|1] ""  IPC_LS
 SG_ LRStStatDispAct : 2|1@0+ (1,0) [0|1] ""  IPC_LS,MSM_LR_LS
 SG_ RRStStatDispAct : 3|1@0+ (1,0) [0|1] ""  IPC_LS,MSM_RR_LS

BO_ 2153848832 Energy_Usage_Scale_Extd_LS: 8 VICM_LS
 SG_ EUSSE_MaxBarDspRng : 63|8@0+ (1,0) [0|255] ""  CSM_LS,RadioHead_LS,CGM_LS
 SG_ EUSSE_ITEgUgScrMxScVal : 53|6@0+ (5,0) [0|315] ""  CSM_LS,RadioHead_LS,CGM_LS
 SG_ EUSSE_TrEgUgScrMxScVal : 43|6@0+ (5,0) [0|315] ""  CSM_LS,RadioHead_LS,CGM_LS
 SG_ EUSSE_TcEgUgScrMxScVal : 33|6@0+ (5,0) [0|315] ""  CSM_LS,RadioHead_LS,CGM_LS
 SG_ EUSSE_OTEgUgScrMxScVal : 39|6@0+ (5,0) [0|315] ""  CSM_LS,RadioHead_LS,CGM_LS
 SG_ EUSSE_TrEgUgScrMnScVal : 30|7@0- (5,0) [-320|315] ""  CSM_LS,RadioHead_LS,CGM_LS
 SG_ EUSSE_TcEgUgScrMnScVal : 21|7@0- (5,0) [-320|315] ""  CSM_LS,RadioHead_LS,CGM_LS
 SG_ EUSSE_OTEgUgScrMnScVal : 12|7@0- (5,0) [-320|315] ""  CSM_LS,RadioHead_LS,CGM_LS
 SG_ EUSSE_ITEgUgScrMnScVal : 3|7@0- (5,0) [-320|315] ""  CSM_LS,RadioHead_LS,CGM_LS

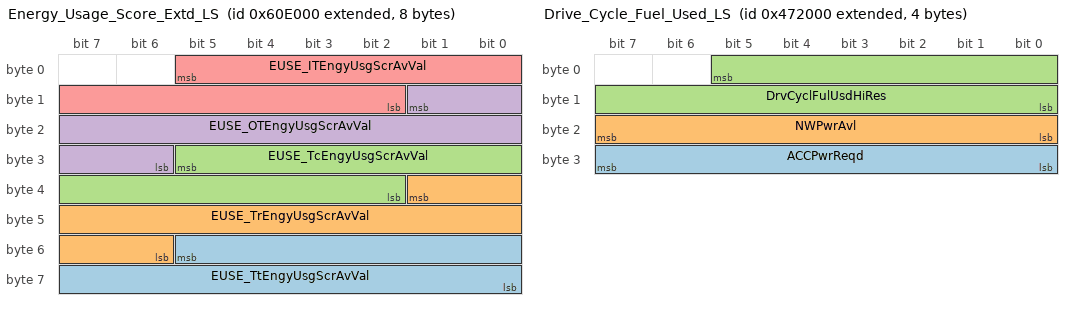
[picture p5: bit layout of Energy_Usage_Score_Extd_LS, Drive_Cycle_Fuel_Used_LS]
BO_ 2153832448 Energy_Usage_Score_Extd_LS: 8 VICM_LS
 SG_ EUSE_TtEngyUsgScrAvVal : 53|14@0- (0.1,0) [-819.2|819.1] ""  CSM_LS,RadioHead_LS,CGM_LS
 SG_ EUSE_TrEngyUsgScrAvVal : 33|12@0- (0.1,0) [-204.8|204.7] ""  CSM_LS,RadioHead_LS,CGM_LS
 SG_ EUSE_TcEngyUsgScrAvVal : 29|12@0- (0.1,0) [-204.8|204.7] ""  CSM_LS,RadioHead_LS,CGM_LS
 SG_ EUSE_OTEngyUsgScrAvVal : 9|12@0- (0.1,0) [-204.8|204.7] ""  CSM_LS,RadioHead_LS,CGM_LS
 SG_ EUSE_ITEngyUsgScrAvVal : 5|12@0- (0.1,0) [-204.8|204.7] ""  CSM_LS,RadioHead_LS,CGM_LS

BO_ 2152144896 Drive_Cycle_Fuel_Used_LS: 4 VICM_LS
 SG_ ACCPwrReqd : 31|8@0+ (0.1,0) [0|25.5] "kW"  ECC_LS,CGM_LS
 SG_ NWPwrAvl : 23|8@0+ (0.1,-5) [-5|20.5] "kW"  ECC_LS,CGM_LS
 SG_ DrvCyclFulUsdHiRes : 5|14@0+ (0.03785412,0) [0|620.16404796] "liters"  CSM_LS,RadioHead_LS,CGM_LS

BO_ 2152177664 OTA_Electric_Pwr_Readiness_LS: 1 BCM_LS
 SG_ RmtRflshElecPwrRdness : 7|8@0+ (0.025,0) [0|6.375] "AmpHour"  TCP_LS,ONSTAR_LS,CSM_LS,RadioHead_LS,CGM_LS

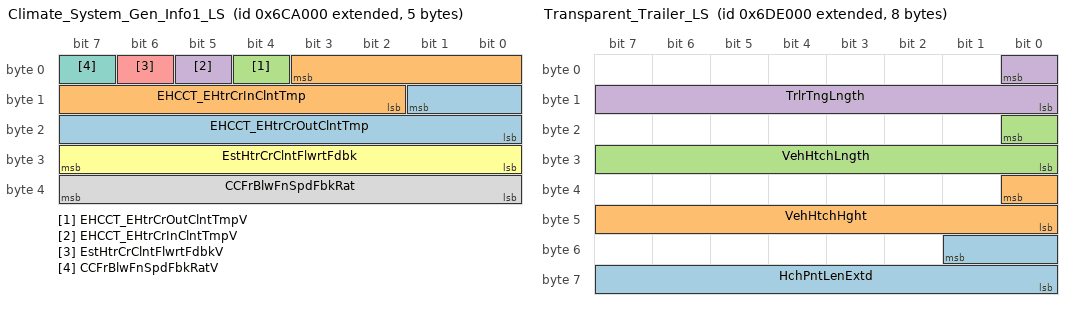
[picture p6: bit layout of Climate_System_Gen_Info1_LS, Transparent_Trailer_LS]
BO_ 2154602496 Climate_System_Gen_Info1_LS: 5 BCM_LS
 SG_ EHCCT_EHtrCrOutClntTmp : 9|10@0+ (0.1857,-40) [-40|149.9711] "DegC"  CGM_LS,ECC_LS
 SG_ EHCCT_EHtrCrInClntTmp : 3|10@0+ (0.1857,-40) [-40|149.9711] "DegC"  CGM_LS,ECC_LS
 SG_ EHCCT_EHtrCrOutClntTmpV : 4|1@0+ (1,0) [0|1] ""  CGM_LS,ECC_LS
 SG_ EHCCT_EHtrCrInClntTmpV : 5|1@0+ (1,0) [0|1] ""  CGM_LS,ECC_LS
 SG_ EstHtrCrClntFlwrtFdbkV : 6|1@0+ (1,0) [0|1] ""  CGM_LS,ECC_LS
 SG_ EstHtrCrClntFlwrtFdbk : 31|8@0+ (0.2509,0) [0|63.9795] "l/min"  CGM_LS,ECC_LS
 SG_ CCFrBlwFnSpdFbkRatV : 7|1@0+ (1,0) [0|1] ""  CGM_LS,ECC_LS
 SG_ CCFrBlwFnSpdFbkRat : 39|8@0+ (0.392157,0) [0|100.000035] "%"  CGM_LS,ECC_LS

BO_ 941 Temp_Diag_CAN_Resp_LS_3AD: 8 Dummy_LS
 SG_ DgnInf : 7|64@0+ (1,0) [0|1.84467440737096E+019] ""  CGM_LS

BO_ 173 Temp_Diag_CAN_Req_LS_0AD: 8 CGM_LS
 SG_ DgnInf : 7|64@0+ (1,0) [0|1.84467440737096E+019] ""  Dummy_LS

BO_ 932 Temp_Diag_CAN_Resp_LS_3A4: 8 Dummy_LS
 SG_ DgnInf : 7|64@0+ (1,0) [0|1.84467440737096E+019] ""  CGM_LS

BO_ 164 Temp_Diag_CAN_Req_LS_0A4: 8 CGM_LS
 SG_ DgnInf : 7|64@0+ (1,0) [0|1.84467440737096E+019] ""  Dummy_LS

BO_ 2154684416 Transparent_Trailer_LS: 8 RadioHead_LS
 SG_ HchPntLenExtd : 49|10@0+ (1,0) [0|1023] "cm"  CGM_LS,VPM_LS
 SG_ VehHtchHght : 32|9@0+ (0.25,0) [0|100] "cm"  CGM_LS,VPM_LS
 SG_ VehHtchLngth : 16|9@0+ (0.25,0) [0|100] "cm"  CGM_LS,VPM_LS
 SG_ TrlrTngLngth : 0|9@0+ (1,0) [0|350] "cm"  CGM_LS,VPM_LS

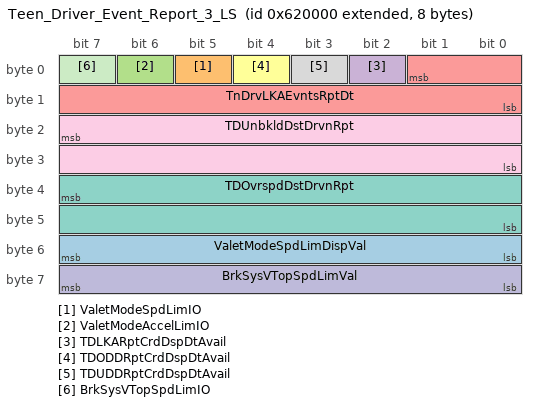
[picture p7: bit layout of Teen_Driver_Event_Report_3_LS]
BO_ 2153906176 Teen_Driver_Event_Report_3_LS: 8 BCM_LS
 SG_ ValetModeSpdLimDispVal : 55|8@0+ (2,0) [0|510] "km/h"  CGM_LS,IPC_LS
 SG_ ValetModeSpdLimIO : 5|1@0+ (1,0) [0|1] ""  CGM_LS,IPC_LS
 SG_ ValetModeAccelLimIO : 6|1@0+ (1,0) [0|1] ""  CGM_LS,IPC_LS
 SG_ TDLKARptCrdDspDtAvail : 2|1@0+ (1,0) [0|1] ""  CGM_LS,CSM_LS,RadioHead_LS
 SG_ TnDrvLKAEvntsRptDt : 1|10@0+ (1,0) [0|1023] ""  CGM_LS,CSM_LS,RadioHead_LS
 SG_ TDODDRptCrdDspDtAvail : 4|1@0+ (1,0) [0|1] ""  CGM_LS,CSM_LS,RadioHead_LS
 SG_ TDOvrspdDstDrvnRpt : 39|16@0+ (1,0) [0|65535] ""  CGM_LS,CSM_LS,RadioHead_LS
 SG_ TDUDDRptCrdDspDtAvail : 3|1@0+ (1,0) [0|1] ""  CGM_LS,CSM_LS,RadioHead_LS
 SG_ TDUnbkldDstDrvnRpt : 23|16@0+ (1,0) [0|65535] ""  CGM_LS,CSM_LS,RadioHead_LS
 SG_ BrkSysVTopSpdLimVal : 63|8@0+ (2,0) [0|510] "km / h"  CGM_LS,IPC_LS
 SG_ BrkSysVTopSpdLimIO : 7|1@0+ (1,0) [0|1] ""  CGM_LS,IPC_LS

BO_ 2155978752 Brake_Pad_life_LS: 8 BCM_LS
 SG_ OPDWrnIndReq : 58|3@0+ (1,0) [0|7] ""  IPC_LS,CGM_LS
 SG_ OPDIndO : 59|1@0+ (1,0) [0|1] ""  IPC_LS,CGM_LS
 SG_ EngAftrRnIndReq : 62|3@0+ (1,0) [0|7] ""  IPC_LS,CGM_LS
 SG_ BrkPdLfRrCnfrmReplcmntIO : 63|1@0+ (1,0) [0|1] ""  IPC_LS,CGM_LS
 SG_ BrkPdLfFrtCnfrmReplcmntIO : 48|1@0+ (1,0) [0|1] ""  IPC_LS,CGM_LS
 SG_ ABSActIO : 39|1@0+ (1,0) [0|1] ""  IPC_LS,CGM_LS
 SG_ CrwlModeDndRsnIndReq : 51|3@0+ (1,0) [0|7] ""  IPC_LS,CGM_LS
 SG_ BrkPdLfRrDstRmng : 31|8@0+ (100,0) [0|25500] ""  CGM_LS,IPC_LS
 SG_ BrkPdLfFrtDstRmng : 23|8@0+ (100,0) [0|25500] ""  CGM_LS,IPC_LS
 SG_ BrkPdLfRrDstWrnIndRq : 53|2@0+ (1,0) [0|3] ""  CGM_LS,IPC_LS
 SG_ BrkPdLfFrtDstWrnIndRq : 55|2@0+ (1,0) [0|3] ""  CGM_LS,IPC_LS
 SG_ BrkPdLfRrRstAvail : 40|1@0+ (1,0) [0|1] ""  CGM_LS,IPC_LS
 SG_ BrkPdLfFrtRstAvail : 41|1@0+ (1,0) [0|1] ""  CGM_LS,IPC_LS
 SG_ BrkPdLfRrV : 15|1@0+ (1,0) [0|1] ""  CGM_LS,IPC_LS
 SG_ BrkPdLfRr : 14|7@0+ (1,0) [0|127] "%"  CGM_LS,IPC_LS
 SG_ BrkPdLfFrtV : 7|1@0+ (1,0) [0|1] ""  CGM_LS,IPC_LS
 SG_ BrkPdLfFrt : 6|7@0+ (1,0) [0|127] "%"  CGM_LS,IPC_LS
 SG_ BrkPdLfStatIndRq : 47|3@0+ (1,0) [0|7] ""  CGM_LS,IPC_LS
 SG_ EngAirFltLfRmn : 38|7@0+ (1,0) [0|127] "%"  IPC_LS,CGM_LS
 SG_ EngAirFltMonSt : 44|3@0+ (1,0) [0|7] ""  IPC_LS,CGM_LS

BO_ 2152013824 Smart_High_Beam_Cust_LS: 1 VIS2_LS
 SG_ SmrtHgBmAstCstSetAvail : 4|1@0+ (1,0) [0|1] ""  CSM_LS,RadioHead_LS,CGM_LS
 SG_ SmrtHgBmAstCstCurrSetVal : 7|3@0+ (1,0) [0|7] ""  BCM_LS,CSM_LS,RadioHead_LS,CGM_LS

BO_ 2159255552 ODI_CenterStack_2_BCM_LS: 8 RadioHead_LS
 SG_ ODI_CntrStck2BCM : 7|64@0+ (1,0) [0|1.84467440737096E+019] ""  BCM_LS

BO_ 2159247360 ODI_BCM_2_CenterStack_LS: 8 BCM_LS
 SG_ ODI_BCM2CntrStck : 7|64@0+ (1,0) [0|1.84467440737096E+019] ""  CGM_LS,CSM_LS,RadioHead_LS

BO_ 104 Temp_Diag_CAN_Req_LS_068: 8 CGM_LS
 SG_ DgnInf : 7|64@0+ (1,0) [0|1.84467440737096E+019] ""  Dummy_LS

BO_ 88 Temp_Diag_CAN_Req_LS_058: 8 CGM_LS
 SG_ DgnInf : 7|64@0+ (1,0) [0|1.84467440737096E+019] ""  Dummy_LS

BO_ 96 Temp_Diag_CAN_Req_LS_060: 8 Dummy_LS
 SG_ DgnInf : 7|64@0+ (1,0) [0|1.84467440737096E+019] ""  CGM_LS

BO_ 169 Temp_Diag_CAN_Req_LS_0A9: 8 CGM_LS
 SG_ DgnInf : 7|64@0+ (1,0) [0|1.84467440737096E+019] ""  Dummy_LS

BO_ 937 Temp_Diag_CAN_Resp_LS_3A9: 8 Dummy_LS
 SG_ DgnInf : 7|64@0+ (1,0) [0|1.84467440737096E+019] ""  CGM_LS

BO_TX_BU_ 2152873984 : CSM_LS,RadioHead_LS,CGM_LS;
BO_TX_BU_ 2152792064 : CGM_LS,VPM_LS;
BO_TX_BU_ 2150694912 : CSM_LS,CGM_LS,RadioHead_LS;
BO_TX_BU_ 2153406464 : BCM_LS,PTM_LS;
BO_TX_BU_ 2154217472 : CGM_LS,TCP_LS,ONSTAR_LS;
BO_TX_BU_ 2154463232 : CGM_LS,VKM_LS;
BO_TX_BU_ 2154446848 : CGM_LS,VKM_LS;
BO_TX_BU_ 2150121472 : CGM_LS,TCP_LS;
BO_TX_BU_ 2150105088 : CGM_LS,CSM_LS;
BO_TX_BU_ 2151194624 : TIM_B_LS,TIM_A_LS,TIM_LS;
BO_TX_BU_ 2153963520 : CGM_LS,RSE_LS;
BO_TX_BU_ 2153848832 : BSM_LS,VICM_LS;
BO_TX_BU_ 2153832448 : BSM_LS,VICM_LS;
BO_TX_BU_ 2154684416 : CSM_LS,RadioHead_LS;
BO_TX_BU_ 2152013824 : FCM_LS,EOCM2A_K2_LS,VIS2_LS;
BO_TX_BU_ 2159255552 : CGM_LS,CSM_LS,RadioHead_LS;
BO_TX_BU_ 96 : CGM_LS,Dummy_LS;

CM_ "Primary Low Speed GMLAN
LS   bus is affected in Version 21.21.145_190222 [Kalyan Kumar SVS, 22 February 2019]";
CM_ BU_ CHUD_LS "Combiner Head-Up Display";
CM_ BU_ VKM_LS "Virtual Key Module";
CM_ BU_ RCRM_LS "Rear Camera Retractable Module";
CM_ BU_ MSM_RR_LS "Memory Seat Module Right Rear";
CM_ BU_ MSM_LR_LS "Memory Seat Module Left Rear";
CM_ BU_ CGM_LS "Communication Gateway";
CM_ BU_ BSM_LS "Battery State Manager";
CM_ BU_ VPM_LS "Video Processing Module";
CM_ BU_ ISRVM_LS "Inside Rearview Mirror";
CM_ BU_ DCAC_LS "DC-AC Power Inverter";
CM_ BU_ TouchPad_LS "Touch Pad Module";
CM_ BU_ RSC_LS "Rear Seat Control ";
CM_ BU_ LVMPC_LS "Low Volume Module (Performance Computer )";
CM_ BU_ EOCM2B_K1_LS "External Object Control Module 2B - K1 micro";
CM_ BU_ EOCM2A_K1_LS "External Object Control Module 2A - K1 micro";
CM_ BU_ LCM_LS "Latch Control Module";
CM_ BU_ TIM_B_LS "Trailer Interface Module";
CM_ BU_ V2V_LS "Vehicle To Vehicle";
CM_ BU_ TCP_LS "Telematics Connectivity Platform";
CM_ BU_ CSM_LS "Center Stack Module";
CM_ BU_ EOCM2B_K2_LS "External Object Control Module 2B - K2 micro";
CM_ BU_ EOCM2A_K2_LS "External Object Control Module 2A - K2 micro";
CM_ BU_ TIM_A_LS "Trailer Interface Module";
CM_ BU_ LVMNav_LS "Low Volume Module (Navigation)";
CM_ BU_ HFP_LS "HVAC Faceplate";
CM_ BU_ EDI_LS "Enhanced Driver Interface";
CM_ BU_ ARB_LS "Articulated Running Board";
CM_ BU_ RSE_LS "Rear Seat Entertainment";
CM_ BU_ Dummy_LS "This is for avoid signle ended signalling";
CM_ BU_ VIS2_LS "Vision Camera";
CM_ BU_ ICS_LS "ICS (Integrated Center Stack) Faceplate";
CM_ BU_ FCM_LS "Front Camera Module";
CM_ BU_ EOCM_F_LS "External Object Control Module - Front";
CM_ BU_ VICM_LS "Vehicle Integration Control Module 4Mode";
CM_ BU_ AGC_LS "Auxilliary Gauge Cluster";
CM_ BU_ MSM_P_LS "Memory Seat Module Passenger";
CM_ BU_ OTIM_LS "OnStar TTY Interface Module";
CM_ BU_ HVSM_R_LS "Heated Vented Seat Module - Rear";
CM_ BU_ HVSM_F_LS "Heated Vented Seat Module - Front";
CM_ BU_ DVB_T_LS "Digital Video BroadCasting TV";
CM_ BU_ SBZA_R_LS "Side Blind Zone Alert Right";
CM_ BU_ PSD_R_LS "Power Sliding Door Right";
CM_ BU_ PSD_L_LS "Power Sliding Door Left";
CM_ BU_ UHP_Low "Universal Handsfree Phone";
CM_ BU_ UPA_LS "Universal Parking Assist";
CM_ BU_ STC_LS "Soft Top Control module (can also be a Hardtop)";
CM_ BU_ SBZA_L_LS "Side Blind Zone Alert Left";
CM_ BU_ PTM_LS "Power Tailgate Module";
CM_ BU_ ONSTAR_LS "OnStar Module";
CM_ BU_ APA_LS "Advanced Parking Aid";
CM_ BU_ PHS_LS "Parking Heater System";
CM_ BU_ PDIM_LS "Preferred Device Interface Module";
CM_ BU_ CHM_LS "Chime Module";
CM_ BU_ RSA_LS "Rear Seat Audio";
CM_ BU_ AMP_LS "Audio Amplifier";
CM_ BU_ HUD_LS "Head-Up Display";
CM_ BU_ MSM_LS "Driver Seat Module";
CM_ BU_ HBSM_LS "High Beam Select Module";
CM_ BU_ SCL_LS "Steering Column Lock";
CM_ BU_ ECC_LS "Electronic Climate Control";
CM_ BU_ RadioHead_LS "Radio Head (SilverBox)";
CM_ BU_ PEPS_LS "Passive Entry Passive Start";
CM_ BU_ IPC_LS "Instrument Panel Cluster";
CM_ BU_ AOS_LS "Automatic Occupant Sensing";
CM_ BU_ SDM_LS "Sensing Diagnostic Module";
CM_ BU_ TIM_LS "Trailer Interface Module";
CM_ BU_ BCM_LS "Body Control Module and LS Side Global Architecture Gateway";
BA_DEF_  "BusType" STRING ;
BA_DEF_ SG_  "VNSigPrimaryTriggering" ENUM  "No","Yes","DLCLS","DLCHS","DLCCE","DLCFO";
BA_DEF_ SG_  "VNSigRemoteDiagnostics" ENUM  "No","Yes","DLCLS","DLCHS","DLCCE","DLCFO";
BA_DEF_ SG_  "VNSigInfotainment" ENUM  "No","Yes","DLCLS","DLCHS","DLCCE","DLCFO";
BA_DEF_ SG_  "VNSigParkedVehicle" ENUM  "No","Yes","DLCLS","DLCHS","DLCCE","DLCFO";
BA_DEF_ SG_  "VNSigIntermediate" ENUM  "No","Yes","DLCLS","DLCHS","DLCCE","DLCFO";
BA_DEF_ SG_  "VNSigUnused_4" ENUM  "No","Yes","DLCLS","DLCHS","DLCCE","DLCFO";
BA_DEF_ SG_  "SignalType" STRING ;
BA_DEF_ SG_  "PacketOrder" INT 0 65535;
BA_DEF_ SG_  "SignalLongName" STRING ;
BA_DEF_ SG_  "GenSigStartValue" INT 0 65535;
BA_DEF_ SG_  "VNSigDiagnostic" ENUM  "No","Yes","DLCLS","DLCHS","DLCCE","DLCFO";
BA_DEF_ SG_  "VNSigAllNodes" ENUM  "No","Yes","DLCLS","DLCHS","DLCCE","DLCFO";
BA_DEF_ SG_  "GenSigDeltaValue" INT 0 0;
BA_DEF_ SG_  "GenSigInactiveValue" INT 0 0;
BA_DEF_ SG_  "GenSigSendType" ENUM  "not used","not used","not used","not used","not used","not used","not used","NoSigSendType","not used","not used","OnAnyChange","OnChangeIfActive","OnDelta","DLCLS","DLCHS","DLCCE","DLCFO";
BA_DEF_ SG_  "GenSigSendOnInit" ENUM  "Not Initialized","Application","Handler","DLCLS","DLCHS","DLCCE","DLCFO";
BA_DEF_ BO_  "AppGenMsgCycleTime" INT 0 0;
BA_DEF_ BO_  "TpTxIndex" INT 0 99;
BA_DEF_ BO_  "GenMsgILSupport" ENUM  "No","Yes","DLCLS","DLCHS","DLCCE","DLCFO";
BA_DEF_ BO_  "TpApplType" STRING ;
BA_DEF_ BO_  "Prio" INT 0 7;
BA_DEF_ BO_  "MessageSubnet" ENUM  "LS","MS","HS","CE","PE","HV","FO","S1","HE","LE","HE2","DLCLS","DLCHS","DLCCE","DLCFO";
BA_DEF_ BO_  "GenMsgMandatoryToSupervision" ENUM  "No","Yes","DLCLS","DLCHS","DLCCE","DLCFO";
BA_DEF_ BO_  "DiagState" ENUM  "No","Yes","DLCLS","DLCHS","DLCCE","DLCFO";
BA_DEF_ BO_  "GenMsgStartDelayTime" INT 0 100000;
BA_DEF_ BO_  "GenMsgDelayTime" INT 0 100000;
BA_DEF_ BO_  "GenMsgCycleTime" INT 0 100000;
BA_DEF_ BO_  "GenMsgSendType" ENUM  "cyclicX","spontanX","cyclicIfActiveX","spontanWithDelay","cyclicAndSpontanX","cyclicAndSpontanWithDelay","spontanWithRepitition","cyclicIfActiveAndSpontanWD","DLCLS","DLCHS","DLCCE","DLCFO";
BA_DEF_ BO_  "DiagResponse" ENUM  "No","Yes","DLCLS","DLCHS","DLCCE","DLCFO";
BA_DEF_ BO_  "DiagRequest" ENUM  "No","Yes","DLCLS","DLCHS","DLCCE","DLCFO";
BA_DEF_ BO_  "NmMessage" ENUM  "No","Yes","DLCLS","DLCHS","DLCCE","DLCFO";
BA_DEF_ BU_  "MessageManagerUsed" ENUM  "No","Yes","DLCLS","DLCHS","DLCCE","DLCFO";
BA_DEF_ BU_  "NmNode" ENUM  "No","Yes","DLCLS","DLCHS","DLCCE","DLCFO";
BA_DEF_ BU_  "ILUsed" ENUM  "No","Yes","DLCLS","DLCHS","DLCCE","DLCFO";
BA_DEF_ BU_  "NodeLayerModules" STRING ;
BA_DEF_ BU_  "VNECUPrimaryTriggering" ENUM  "None","Activator","Remoted","Activator and Remoted","Shared Local","DLCLS","DLCHS","DLCCE","DLCFO";
BA_DEF_ BU_  "VNECUParkedVehicle" ENUM  "None","Activator","Remoted","Activator and Remoted","Shared Local","DLCLS","DLCHS","DLCCE","DLCFO";
BA_DEF_ BU_  "VNECURemoteDiagnostics" ENUM  "None","Activator","Remoted","Activator and Remoted","Shared Local","DLCLS","DLCHS","DLCCE","DLCFO";
BA_DEF_ BU_  "VNECUIntermediate" ENUM  "None","Activator","Remoted","Activator and Remoted","Shared Local","DLCLS","DLCHS","DLCCE","DLCFO";
BA_DEF_ BU_  "VNECUInfotainment" ENUM  "None","Activator","Remoted","Activator and Remoted","Shared Local","DLCLS","DLCHS","DLCCE","DLCFO";
BA_DEF_ BU_  "VNECUAllNodes" ENUM  "None","Activator","Remoted","Activator and Remoted","Shared Local","DLCLS","DLCHS","DLCCE","DLCFO";
BA_DEF_ BU_  "VNECUDiagnostic" ENUM  "None","Activator","Remoted","Activator and Remoted","Shared Local","DLCLS","DLCHS","DLCCE","DLCFO";
BA_DEF_ BU_  "ECU_Id" HEX 0 255;
BA_DEF_ BU_  "SourceId" HEX 0 253;
BA_DEF_  "VersionMonth" INT 0 255;
BA_DEF_  "SyncJumpWidthMax" INT 0 255;
BA_DEF_  "SyncJumpWidthMin" INT 0 255;
BA_DEF_  "SamplePointMax" FLOAT 0 100;
BA_DEF_  "SamplePointMin" FLOAT 0 100;
BA_DEF_  "Baudrate" INT 0 1000000;
BA_DEF_  "VehicleArchitecture" STRING ;
BA_DEF_  "VNInitActPrimaryTriggering" ENUM  "No","Yes","DLCLS","DLCHS","DLCCE","DLCFO";
BA_DEF_  "VN_PrimaryTriggering" INT 0 255;
BA_DEF_  "VN_RemoteDiagnostics" INT 0 255;
BA_DEF_  "VN_Infotainment" INT 0 255;
BA_DEF_  "VN_ParkedVehicle" INT 0 255;
BA_DEF_  "VN_Intermediate" INT 0 255;
BA_DEF_  "VN_Unused_4" INT 0 255;
BA_DEF_  "VNInitActDiagnostic" ENUM  "No","Yes","DLCLS","DLCHS","DLCCE","DLCFO";
BA_DEF_  "NmMessageCount" INT 0 32;
BA_DEF_  "NmBaseAddress" HEX 0 2032;
BA_DEF_  "NetworkType" STRING ;
BA_DEF_  "VNMFPeriodicInterval" INT 0 65535;
BA_DEF_  "BusWakeUpDelay" INT 0 65535;
BA_DEF_  "BusOffRecoveryTime" INT 0 65535;
BA_DEF_  "NodeStatusMsgID" HEX 0 536870911;
BA_DEF_  "NodeStatusMsgCycleTime" INT 0 65535;
BA_DEF_  "NodeStatusMsgTimeoutTime" INT 0 65535;
BA_DEF_  "UseGMParameterIDs" INT 0 1;
BA_DEF_  "VersionWeek" INT 0 255;
BA_DEF_  "VersionYear" INT 0 255;
BA_DEF_  "VN_AllNodes" INT 0 255;
BA_DEF_  "VN_Diagnostic" INT 0 255;
BA_DEF_  "Manufacturer" ENUM  "DBAG","VAG","BMW","PAG","GM","DLCLS","DLCHS","DLCCE","DLCFO";
BA_DEF_  "NmType" STRING ;
BA_DEF_REL_ BU_SG_REL_  "GenSigSuprvRespComment" STRING ;
BA_DEF_REL_ BU_SG_REL_  "GenSigVBitResp" ENUM  "No","Yes","DLCLS","DLCHS","DLCCE","DLCFO";
BA_DEF_REL_ BU_SG_REL_  "GenSigVBitRespComment" STRING ;
BA_DEF_REL_ BU_SG_REL_  "GenSigVDAFailComment" STRING ;
BA_DEF_REL_ BU_SG_REL_  "GenSigVDAFailResp" ENUM  "No","Yes","DLCLS","DLCHS","DLCCE","DLCFO";
BA_DEF_REL_ BU_SG_REL_  "GenSigRxStartValue" STRING ;
BA_DEF_REL_ BU_SG_REL_  "GenSigSuprvRespSubValue" INT 0 65535;
BA_DEF_REL_ BU_SG_REL_  "GenSigSuprvResp" ENUM  "None","Notify App","Substitute Default","DLCLS","DLCHS","DLCCE","DLCFO";
BA_DEF_REL_ BU_SG_REL_  "GenSigTimeoutMsg" HEX -2147483648 268435455;
BA_DEF_REL_ BU_SG_REL_  "GenSigTimeoutTime" INT 0 15000;
BA_DEF_DEF_  "BusType" "";
BA_DEF_DEF_  "VNSigPrimaryTriggering" "No";
BA_DEF_DEF_  "VNSigRemoteDiagnostics" "No";
BA_DEF_DEF_  "VNSigInfotainment" "No";
BA_DEF_DEF_  "VNSigParkedVehicle" "No";
BA_DEF_DEF_  "VNSigIntermediate" "No";
BA_DEF_DEF_  "VNSigUnused_4" "No";
BA_DEF_DEF_  "SignalType" "";
BA_DEF_DEF_  "PacketOrder" 0;
BA_DEF_DEF_  "SignalLongName" "";
BA_DEF_DEF_  "GenSigStartValue" 0;
BA_DEF_DEF_  "VNSigDiagnostic" "No";
BA_DEF_DEF_  "VNSigAllNodes" "No";
BA_DEF_DEF_  "GenSigDeltaValue" 0;
BA_DEF_DEF_  "GenSigInactiveValue" 0;
BA_DEF_DEF_  "GenSigSendType" "NoSigSendType";
BA_DEF_DEF_  "GenSigSendOnInit" "Not Initialized";
BA_DEF_DEF_  "AppGenMsgCycleTime" 0;
BA_DEF_DEF_  "TpTxIndex" 0;
BA_DEF_DEF_  "GenMsgILSupport" "Yes";
BA_DEF_DEF_  "TpApplType" "";
BA_DEF_DEF_  "Prio" 4;
BA_DEF_DEF_  "MessageSubnet" "FO";
BA_DEF_DEF_  "GenMsgMandatoryToSupervision" "No";
BA_DEF_DEF_  "DiagState" "No";
BA_DEF_DEF_  "GenMsgStartDelayTime" 0;
BA_DEF_DEF_  "GenMsgDelayTime" 0;
BA_DEF_DEF_  "GenMsgCycleTime" 0;
BA_DEF_DEF_  "GenMsgSendType" "spontanX";
BA_DEF_DEF_  "DiagResponse" "No";
BA_DEF_DEF_  "DiagRequest" "No";
BA_DEF_DEF_  "NmMessage" "No";
BA_DEF_DEF_  "MessageManagerUsed" "Yes";
BA_DEF_DEF_  "NmNode" "Yes";
BA_DEF_DEF_  "ILUsed" "Yes";
BA_DEF_DEF_  "NodeLayerModules" "gmlan02.dll";
BA_DEF_DEF_  "VNECUPrimaryTriggering" "None";
BA_DEF_DEF_  "VNECUParkedVehicle" "None";
BA_DEF_DEF_  "VNECURemoteDiagnostics" "None";
BA_DEF_DEF_  "VNECUIntermediate" "None";
BA_DEF_DEF_  "VNECUInfotainment" "None";
BA_DEF_DEF_  "VNECUAllNodes" "None";
BA_DEF_DEF_  "VNECUDiagnostic" "None";
BA_DEF_DEF_  "ECU_Id" 0;
BA_DEF_DEF_  "SourceId" 0;
BA_DEF_DEF_  "VersionMonth" 0;
BA_DEF_DEF_  "SyncJumpWidthMax" 0;
BA_DEF_DEF_  "SyncJumpWidthMin" 0;
BA_DEF_DEF_  "SamplePointMax" 0;
BA_DEF_DEF_  "SamplePointMin" 0;
BA_DEF_DEF_  "Baudrate" 0;
BA_DEF_DEF_  "VehicleArchitecture" "";
BA_DEF_DEF_  "VNInitActPrimaryTriggering" "No";
BA_DEF_DEF_  "VN_PrimaryTriggering" 7;
BA_DEF_DEF_  "VN_RemoteDiagnostics" 5;
BA_DEF_DEF_  "VN_Infotainment" 2;
BA_DEF_DEF_  "VN_ParkedVehicle" 6;
BA_DEF_DEF_  "VN_Intermediate" 3;
BA_DEF_DEF_  "VN_Unused_4" 4;
BA_DEF_DEF_  "VNInitActDiagnostic" "No";
BA_DEF_DEF_  "NmMessageCount" 32;
BA_DEF_DEF_  "NmBaseAddress" 1568;
BA_DEF_DEF_  "NetworkType" "";
BA_DEF_DEF_  "VNMFPeriodicInterval" 3000;
BA_DEF_DEF_  "BusWakeUpDelay" 100;
BA_DEF_DEF_  "BusOffRecoveryTime" 0;
BA_DEF_DEF_  "NodeStatusMsgID" 268427264;
BA_DEF_DEF_  "NodeStatusMsgCycleTime" 1200;
BA_DEF_DEF_  "NodeStatusMsgTimeoutTime" 0;
BA_DEF_DEF_  "UseGMParameterIDs" 1;
BA_DEF_DEF_  "VersionWeek" 0;
BA_DEF_DEF_  "VersionYear" 0;
BA_DEF_DEF_  "VN_AllNodes" 1;
BA_DEF_DEF_  "VN_Diagnostic" 0;
BA_DEF_DEF_  "Manufacturer" "GM";
BA_DEF_DEF_  "NmType" "GMLAN";
BA_DEF_DEF_REL_ "GenSigSuprvRespComment" "";
BA_DEF_DEF_REL_ "GenSigVBitResp" "No";
BA_DEF_DEF_REL_ "GenSigVBitRespComment" "";
BA_DEF_DEF_REL_ "GenSigVDAFailComment" "";
BA_DEF_DEF_REL_ "GenSigVDAFailResp" "No";
BA_DEF_DEF_REL_ "GenSigRxStartValue" "";
BA_DEF_DEF_REL_ "GenSigSuprvRespSubValue" 0;
BA_DEF_DEF_REL_ "GenSigSuprvResp" "None";
BA_DEF_DEF_REL_ "GenSigTimeoutMsg" 0;
BA_DEF_DEF_REL_ "GenSigTimeoutTime" 0;
BA_ "VersionMonth" 21;
BA_ "SyncJumpWidthMax" 3;
BA_ "SyncJumpWidthMin" 2;
BA_ "SamplePointMax" 89.48;
BA_ "SamplePointMin" 85;
BA_ "Baudrate" 33333;
BA_ "VehicleArchitecture" "Global A";
BA_ "VNInitActPrimaryTriggering" 1;
BA_ "VNInitActDiagnostic" 1;
BA_ "NetworkType" "Bodybus";
BA_ "BusWakeUpDelay" 70;
BA_ "BusOffRecoveryTime" 3700;
BA_ "NodeStatusMsgID" 335536128;
BA_ "NodeStatusMsgTimeoutTime" 3000;
BA_ "VersionWeek" 45;
BA_ "VersionYear" 21;
BA_ "BusType" "CAN";
BA_ "VNECUPrimaryTriggering" BU_ CHUD_LS 2;
BA_ "VNECUInfotainment" BU_ CHUD_LS 2;
BA_ "VNECUAllNodes" BU_ CHUD_LS 2;
BA_ "VNECUDiagnostic" BU_ CHUD_LS 4;
BA_ "ECU_Id" BU_ CHUD_LS 42;
BA_ "SourceId" BU_ CHUD_LS 98;
BA_ "VNECUPrimaryTriggering" BU_ VKM_LS 2;
BA_ "VNECUIntermediate" BU_ VKM_LS 3;
BA_ "VNECUAllNodes" BU_ VKM_LS 2;
BA_ "VNECUDiagnostic" BU_ VKM_LS 4;
BA_ "ECU_Id" BU_ VKM_LS 46;
BA_ "SourceId" BU_ VKM_LS 148;
BA_ "VNECUPrimaryTriggering" BU_ RCRM_LS 2;
BA_ "VNECUAllNodes" BU_ RCRM_LS 2;
BA_ "VNECUDiagnostic" BU_ RCRM_LS 4;
BA_ "ECU_Id" BU_ RCRM_LS 63;
BA_ "SourceId" BU_ RCRM_LS 228;
BA_ "VNECUPrimaryTriggering" BU_ MSM_RR_LS 2;
BA_ "VNECUAllNodes" BU_ MSM_RR_LS 3;
BA_ "VNECUDiagnostic" BU_ MSM_RR_LS 4;
BA_ "ECU_Id" BU_ MSM_RR_LS 42;
BA_ "SourceId" BU_ MSM_RR_LS 167;
BA_ "VNECUPrimaryTriggering" BU_ MSM_LR_LS 2;
BA_ "VNECUAllNodes" BU_ MSM_LR_LS 3;
BA_ "VNECUDiagnostic" BU_ MSM_LR_LS 4;
BA_ "ECU_Id" BU_ MSM_LR_LS 56;
BA_ "SourceId" BU_ MSM_LR_LS 170;
BA_ "VNECUPrimaryTriggering" BU_ CGM_LS 2;
BA_ "VNECUParkedVehicle" BU_ CGM_LS 2;
BA_ "VNECURemoteDiagnostics" BU_ CGM_LS 2;
BA_ "VNECUIntermediate" BU_ CGM_LS 2;
BA_ "VNECUInfotainment" BU_ CGM_LS 2;
BA_ "VNECUAllNodes" BU_ CGM_LS 2;
BA_ "VNECUDiagnostic" BU_ CGM_LS 4;
BA_ "ECU_Id" BU_ CGM_LS 51;
BA_ "SourceId" BU_ CGM_LS 69;
BA_ "VNECUPrimaryTriggering" BU_ BSM_LS 2;
BA_ "VNECUInfotainment" BU_ BSM_LS 2;
BA_ "VNECUAllNodes" BU_ BSM_LS 3;
BA_ "VNECUDiagnostic" BU_ BSM_LS 4;
BA_ "ECU_Id" BU_ BSM_LS 228;
BA_ "SourceId" BU_ BSM_LS 203;
BA_ "VNECUPrimaryTriggering" BU_ VPM_LS 2;
BA_ "VNECUAllNodes" BU_ VPM_LS 2;
BA_ "VNECUDiagnostic" BU_ VPM_LS 4;
BA_ "ECU_Id" BU_ VPM_LS 48;
BA_ "SourceId" BU_ VPM_LS 109;
BA_ "VNECUPrimaryTriggering" BU_ ISRVM_LS 2;
BA_ "VNECUInfotainment" BU_ ISRVM_LS 2;
BA_ "VNECUAllNodes" BU_ ISRVM_LS 2;
BA_ "VNECUDiagnostic" BU_ ISRVM_LS 4;
BA_ "ECU_Id" BU_ ISRVM_LS 63;
BA_ "SourceId" BU_ ISRVM_LS 189;
BA_ "VNECUPrimaryTriggering" BU_ DCAC_LS 2;
BA_ "VNECUAllNodes" BU_ DCAC_LS 2;
BA_ "VNECUDiagnostic" BU_ DCAC_LS 4;
BA_ "ECU_Id" BU_ DCAC_LS 35;
BA_ "SourceId" BU_ DCAC_LS 207;
BA_ "VNECUPrimaryTriggering" BU_ TouchPad_LS 2;
BA_ "VNECUInfotainment" BU_ TouchPad_LS 2;
BA_ "VNECUAllNodes" BU_ TouchPad_LS 2;
BA_ "VNECUDiagnostic" BU_ TouchPad_LS 4;
BA_ "ECU_Id" BU_ TouchPad_LS 50;
BA_ "SourceId" BU_ TouchPad_LS 141;
BA_ "VNECUPrimaryTriggering" BU_ RSC_LS 2;
BA_ "VNECUInfotainment" BU_ RSC_LS 2;
BA_ "VNECUAllNodes" BU_ RSC_LS 2;
BA_ "VNECUDiagnostic" BU_ RSC_LS 4;
BA_ "ECU_Id" BU_ RSC_LS 46;
BA_ "SourceId" BU_ RSC_LS 133;
BA_ "VNECUPrimaryTriggering" BU_ LVMPC_LS 2;
BA_ "VNECUInfotainment" BU_ LVMPC_LS 2;
BA_ "VNECUAllNodes" BU_ LVMPC_LS 2;
BA_ "VNECUDiagnostic" BU_ LVMPC_LS 4;
BA_ "ECU_Id" BU_ LVMPC_LS 42;
BA_ "SourceId" BU_ LVMPC_LS 105;
BA_ "VNECUPrimaryTriggering" BU_ EOCM2B_K1_LS 2;
BA_ "VNECUAllNodes" BU_ EOCM2B_K1_LS 3;
BA_ "VNECUDiagnostic" BU_ EOCM2B_K1_LS 4;
BA_ "VNECUPrimaryTriggering" BU_ EOCM2A_K1_LS 2;
BA_ "VNECUAllNodes" BU_ EOCM2A_K1_LS 3;
BA_ "VNECUDiagnostic" BU_ EOCM2A_K1_LS 4;
BA_ "VNECUPrimaryTriggering" BU_ LCM_LS 2;
BA_ "VNECUParkedVehicle" BU_ LCM_LS 2;
BA_ "VNECUAllNodes" BU_ LCM_LS 3;
BA_ "VNECUDiagnostic" BU_ LCM_LS 4;
BA_ "ECU_Id" BU_ LCM_LS 56;
BA_ "SourceId" BU_ LCM_LS 164;
BA_ "VNECUPrimaryTriggering" BU_ TIM_B_LS 2;
BA_ "VNECUParkedVehicle" BU_ TIM_B_LS 2;
BA_ "VNECUInfotainment" BU_ TIM_B_LS 3;
BA_ "VNECUAllNodes" BU_ TIM_B_LS 2;
BA_ "VNECUDiagnostic" BU_ TIM_B_LS 4;
BA_ "ECU_Id" BU_ TIM_B_LS 54;
BA_ "SourceId" BU_ TIM_B_LS 117;
BA_ "VNECUPrimaryTriggering" BU_ V2V_LS 2;
BA_ "VNECUParkedVehicle" BU_ V2V_LS 2;
BA_ "VNECUAllNodes" BU_ V2V_LS 2;
BA_ "VNECUDiagnostic" BU_ V2V_LS 4;
BA_ "ECU_Id" BU_ V2V_LS 59;
BA_ "SourceId" BU_ V2V_LS 86;
BA_ "VNECUPrimaryTriggering" BU_ TCP_LS 2;
BA_ "VNECURemoteDiagnostics" BU_ TCP_LS 1;
BA_ "VNECUIntermediate" BU_ TCP_LS 3;
BA_ "VNECUInfotainment" BU_ TCP_LS 3;
BA_ "VNECUAllNodes" BU_ TCP_LS 3;
BA_ "VNECUDiagnostic" BU_ TCP_LS 4;
BA_ "ECU_Id" BU_ TCP_LS 45;
BA_ "SourceId" BU_ TCP_LS 151;
BA_ "VNECUPrimaryTriggering" BU_ CSM_LS 2;
BA_ "VNECURemoteDiagnostics" BU_ CSM_LS 1;
BA_ "VNECUIntermediate" BU_ CSM_LS 2;
BA_ "VNECUInfotainment" BU_ CSM_LS 3;
BA_ "VNECUAllNodes" BU_ CSM_LS 3;
BA_ "VNECUDiagnostic" BU_ CSM_LS 4;
BA_ "ECU_Id" BU_ CSM_LS 36;
BA_ "SourceId" BU_ CSM_LS 128;
BA_ "VNECUPrimaryTriggering" BU_ EOCM2B_K2_LS 2;
BA_ "VNECUAllNodes" BU_ EOCM2B_K2_LS 3;
BA_ "VNECUDiagnostic" BU_ EOCM2B_K2_LS 4;
BA_ "ECU_Id" BU_ EOCM2B_K2_LS 62;
BA_ "SourceId" BU_ EOCM2B_K2_LS 222;
BA_ "VNECUPrimaryTriggering" BU_ EOCM2A_K2_LS 2;
BA_ "VNECUAllNodes" BU_ EOCM2A_K2_LS 3;
BA_ "VNECUDiagnostic" BU_ EOCM2A_K2_LS 4;
BA_ "ECU_Id" BU_ EOCM2A_K2_LS 43;
BA_ "SourceId" BU_ EOCM2A_K2_LS 219;
BA_ "VNECUPrimaryTriggering" BU_ TIM_A_LS 2;
BA_ "VNECUParkedVehicle" BU_ TIM_A_LS 2;
BA_ "VNECUInfotainment" BU_ TIM_A_LS 3;
BA_ "VNECUAllNodes" BU_ TIM_A_LS 2;
BA_ "VNECUDiagnostic" BU_ TIM_A_LS 4;
BA_ "ECU_Id" BU_ TIM_A_LS 53;
BA_ "SourceId" BU_ TIM_A_LS 117;
BA_ "VNECUPrimaryTriggering" BU_ LVMNav_LS 2;
BA_ "VNECUInfotainment" BU_ LVMNav_LS 2;
BA_ "VNECUAllNodes" BU_ LVMNav_LS 2;
BA_ "VNECUDiagnostic" BU_ LVMNav_LS 4;
BA_ "ECU_Id" BU_ LVMNav_LS 45;
BA_ "SourceId" BU_ LVMNav_LS 145;
BA_ "VNECUPrimaryTriggering" BU_ HFP_LS 2;
BA_ "VNECUInfotainment" BU_ HFP_LS 2;
BA_ "VNECUAllNodes" BU_ HFP_LS 2;
BA_ "VNECUDiagnostic" BU_ HFP_LS 4;
BA_ "ECU_Id" BU_ HFP_LS 40;
BA_ "SourceId" BU_ HFP_LS 104;
BA_ "VNECUPrimaryTriggering" BU_ EDI_LS 2;
BA_ "VNECUInfotainment" BU_ EDI_LS 2;
BA_ "VNECUAllNodes" BU_ EDI_LS 2;
BA_ "VNECUDiagnostic" BU_ EDI_LS 4;
BA_ "VNECUPrimaryTriggering" BU_ ARB_LS 2;
BA_ "VNECUAllNodes" BU_ ARB_LS 2;
BA_ "VNECUDiagnostic" BU_ ARB_LS 4;
BA_ "ECU_Id" BU_ ARB_LS 59;
BA_ "SourceId" BU_ ARB_LS 178;
BA_ "VNECUPrimaryTriggering" BU_ RSE_LS 2;
BA_ "VNECUInfotainment" BU_ RSE_LS 2;
BA_ "VNECUAllNodes" BU_ RSE_LS 2;
BA_ "VNECUDiagnostic" BU_ RSE_LS 4;
BA_ "ECU_Id" BU_ RSE_LS 54;
BA_ "SourceId" BU_ RSE_LS 134;
BA_ "VNECUPrimaryTriggering" BU_ VIS2_LS 2;
BA_ "VNECUAllNodes" BU_ VIS2_LS 2;
BA_ "VNECUDiagnostic" BU_ VIS2_LS 4;
BA_ "ECU_Id" BU_ VIS2_LS 53;
BA_ "SourceId" BU_ VIS2_LS 188;
BA_ "VNECUPrimaryTriggering" BU_ ICS_LS 2;
BA_ "VNECUAllNodes" BU_ ICS_LS 2;
BA_ "VNECUDiagnostic" BU_ ICS_LS 4;
BA_ "ECU_Id" BU_ ICS_LS 38;
BA_ "SourceId" BU_ ICS_LS 102;
BA_ "VNECUPrimaryTriggering" BU_ FCM_LS 2;
BA_ "VNECUAllNodes" BU_ FCM_LS 2;
BA_ "VNECUDiagnostic" BU_ FCM_LS 4;
BA_ "ECU_Id" BU_ FCM_LS 43;
BA_ "SourceId" BU_ FCM_LS 188;
BA_ "VNECUPrimaryTriggering" BU_ EOCM_F_LS 2;
BA_ "VNECUAllNodes" BU_ EOCM_F_LS 2;
BA_ "VNECUDiagnostic" BU_ EOCM_F_LS 4;
BA_ "ECU_Id" BU_ EOCM_F_LS 43;
BA_ "SourceId" BU_ EOCM_F_LS 108;
BA_ "VNECUPrimaryTriggering" BU_ VICM_LS 2;
BA_ "VNECUInfotainment" BU_ VICM_LS 2;
BA_ "VNECUAllNodes" BU_ VICM_LS 3;
BA_ "VNECUDiagnostic" BU_ VICM_LS 4;
BA_ "ECU_Id" BU_ VICM_LS 228;
BA_ "SourceId" BU_ VICM_LS 203;
BA_ "VNECUPrimaryTriggering" BU_ AGC_LS 2;
BA_ "VNECUAllNodes" BU_ AGC_LS 2;
BA_ "VNECUDiagnostic" BU_ AGC_LS 4;
BA_ "ECU_Id" BU_ AGC_LS 35;
BA_ "SourceId" BU_ AGC_LS 103;
BA_ "VNECUPrimaryTriggering" BU_ MSM_P_LS 2;
BA_ "VNECUAllNodes" BU_ MSM_P_LS 3;
BA_ "VNECUDiagnostic" BU_ MSM_P_LS 4;
BA_ "ECU_Id" BU_ MSM_P_LS 41;
BA_ "SourceId" BU_ MSM_P_LS 166;
BA_ "VNECUPrimaryTriggering" BU_ OTIM_LS 2;
BA_ "VNECUInfotainment" BU_ OTIM_LS 2;
BA_ "VNECUAllNodes" BU_ OTIM_LS 2;
BA_ "VNECUDiagnostic" BU_ OTIM_LS 4;
BA_ "ECU_Id" BU_ OTIM_LS 41;
BA_ "SourceId" BU_ OTIM_LS 150;
BA_ "VNECUPrimaryTriggering" BU_ HVSM_R_LS 2;
BA_ "VNECUAllNodes" BU_ HVSM_R_LS 2;
BA_ "VNECUDiagnostic" BU_ HVSM_R_LS 4;
BA_ "ECU_Id" BU_ HVSM_R_LS 56;
BA_ "SourceId" BU_ HVSM_R_LS 170;
BA_ "VNECUPrimaryTriggering" BU_ HVSM_F_LS 2;
BA_ "VNECUAllNodes" BU_ HVSM_F_LS 2;
BA_ "VNECUDiagnostic" BU_ HVSM_F_LS 4;
BA_ "ECU_Id" BU_ HVSM_F_LS 61;
BA_ "SourceId" BU_ HVSM_F_LS 169;
BA_ "VNECUPrimaryTriggering" BU_ DVB_T_LS 2;
BA_ "VNECUInfotainment" BU_ DVB_T_LS 2;
BA_ "VNECUAllNodes" BU_ DVB_T_LS 2;
BA_ "VNECUDiagnostic" BU_ DVB_T_LS 4;
BA_ "ECU_Id" BU_ DVB_T_LS 50;
BA_ "SourceId" BU_ DVB_T_LS 135;
BA_ "VNECUPrimaryTriggering" BU_ SBZA_R_LS 2;
BA_ "VNECUAllNodes" BU_ SBZA_R_LS 2;
BA_ "VNECUDiagnostic" BU_ SBZA_R_LS 4;
BA_ "ECU_Id" BU_ SBZA_R_LS 55;
BA_ "SourceId" BU_ SBZA_R_LS 91;
BA_ "VNECUPrimaryTriggering" BU_ PSD_R_LS 2;
BA_ "VNECUAllNodes" BU_ PSD_R_LS 2;
BA_ "VNECUDiagnostic" BU_ PSD_R_LS 4;
BA_ "ECU_Id" BU_ PSD_R_LS 46;
BA_ "SourceId" BU_ PSD_R_LS 172;
BA_ "VNECUPrimaryTriggering" BU_ PSD_L_LS 2;
BA_ "VNECUAllNodes" BU_ PSD_L_LS 2;
BA_ "VNECUDiagnostic" BU_ PSD_L_LS 4;
BA_ "ECU_Id" BU_ PSD_L_LS 42;
BA_ "SourceId" BU_ PSD_L_LS 171;
BA_ "VNECUPrimaryTriggering" BU_ UHP_Low 2;
BA_ "VNECUInfotainment" BU_ UHP_Low 2;
BA_ "VNECUAllNodes" BU_ UHP_Low 2;
BA_ "VNECUDiagnostic" BU_ UHP_Low 4;
BA_ "ECU_Id" BU_ UHP_Low 45;
BA_ "SourceId" BU_ UHP_Low 151;
BA_ "VNECUPrimaryTriggering" BU_ UPA_LS 2;
BA_ "VNECUAllNodes" BU_ UPA_LS 2;
BA_ "VNECUDiagnostic" BU_ UPA_LS 4;
BA_ "ECU_Id" BU_ UPA_LS 57;
BA_ "SourceId" BU_ UPA_LS 187;
BA_ "VNECUPrimaryTriggering" BU_ STC_LS 2;
BA_ "VNECUInfotainment" BU_ STC_LS 2;
BA_ "VNECUAllNodes" BU_ STC_LS 3;
BA_ "VNECUDiagnostic" BU_ STC_LS 4;
BA_ "ECU_Id" BU_ STC_LS 47;
BA_ "SourceId" BU_ STC_LS 173;
BA_ "VNECUPrimaryTriggering" BU_ SBZA_L_LS 2;
BA_ "VNECUAllNodes" BU_ SBZA_L_LS 2;
BA_ "VNECUDiagnostic" BU_ SBZA_L_LS 4;
BA_ "ECU_Id" BU_ SBZA_L_LS 58;
BA_ "SourceId" BU_ SBZA_L_LS 185;
BA_ "VNECUPrimaryTriggering" BU_ PTM_LS 2;
BA_ "VNECUParkedVehicle" BU_ PTM_LS 2;
BA_ "VNECUAllNodes" BU_ PTM_LS 3;
BA_ "VNECUDiagnostic" BU_ PTM_LS 4;
BA_ "ECU_Id" BU_ PTM_LS 47;
BA_ "SourceId" BU_ PTM_LS 164;
BA_ "VNECUPrimaryTriggering" BU_ ONSTAR_LS 2;
BA_ "VNECURemoteDiagnostics" BU_ ONSTAR_LS 1;
BA_ "VNECUIntermediate" BU_ ONSTAR_LS 3;
BA_ "VNECUInfotainment" BU_ ONSTAR_LS 3;
BA_ "VNECUAllNodes" BU_ ONSTAR_LS 3;
BA_ "VNECUDiagnostic" BU_ ONSTAR_LS 4;
BA_ "ECU_Id" BU_ ONSTAR_LS 45;
BA_ "SourceId" BU_ ONSTAR_LS 151;
BA_ "VNECUPrimaryTriggering" BU_ APA_LS 2;
BA_ "VNECUAllNodes" BU_ APA_LS 2;
BA_ "VNECUDiagnostic" BU_ APA_LS 4;
BA_ "ECU_Id" BU_ APA_LS 57;
BA_ "SourceId" BU_ APA_LS 187;
BA_ "SourceId" BU_ TestTool_LS 253;
BA_ "NmNode" BU_ TestTool_LS 0;
BA_ "VNECUPrimaryTriggering" BU_ PHS_LS 2;
BA_ "VNECUIntermediate" BU_ PHS_LS 3;
BA_ "VNECUAllNodes" BU_ PHS_LS 2;
BA_ "VNECUDiagnostic" BU_ PHS_LS 4;
BA_ "ECU_Id" BU_ PHS_LS 62;
BA_ "SourceId" BU_ PHS_LS 152;
BA_ "VNECUPrimaryTriggering" BU_ PDIM_LS 2;
BA_ "VNECUInfotainment" BU_ PDIM_LS 2;
BA_ "VNECUAllNodes" BU_ PDIM_LS 2;
BA_ "VNECUDiagnostic" BU_ PDIM_LS 4;
BA_ "ECU_Id" BU_ PDIM_LS 40;
BA_ "SourceId" BU_ PDIM_LS 142;
BA_ "VNECUPrimaryTriggering" BU_ CHM_LS 2;
BA_ "VNECUIntermediate" BU_ CHM_LS 2;
BA_ "VNECUAllNodes" BU_ CHM_LS 2;
BA_ "VNECUDiagnostic" BU_ CHM_LS 4;
BA_ "ECU_Id" BU_ CHM_LS 36;
BA_ "SourceId" BU_ CHM_LS 111;
BA_ "VNECUPrimaryTriggering" BU_ RSA_LS 2;
BA_ "VNECUInfotainment" BU_ RSA_LS 2;
BA_ "VNECUAllNodes" BU_ RSA_LS 2;
BA_ "VNECUDiagnostic" BU_ RSA_LS 4;
BA_ "ECU_Id" BU_ RSA_LS 54;
BA_ "SourceId" BU_ RSA_LS 133;
BA_ "VNECUPrimaryTriggering" BU_ AMP_LS 2;
BA_ "VNECUIntermediate" BU_ AMP_LS 2;
BA_ "VNECUInfotainment" BU_ AMP_LS 2;
BA_ "VNECUAllNodes" BU_ AMP_LS 2;
BA_ "VNECUDiagnostic" BU_ AMP_LS 4;
BA_ "ECU_Id" BU_ AMP_LS 52;
BA_ "SourceId" BU_ AMP_LS 129;
BA_ "VNECUPrimaryTriggering" BU_ HUD_LS 2;
BA_ "VNECUInfotainment" BU_ HUD_LS 2;
BA_ "VNECUAllNodes" BU_ HUD_LS 2;
BA_ "VNECUDiagnostic" BU_ HUD_LS 4;
BA_ "ECU_Id" BU_ HUD_LS 48;
BA_ "SourceId" BU_ HUD_LS 98;
BA_ "VNECUPrimaryTriggering" BU_ MSM_LS 2;
BA_ "VNECUAllNodes" BU_ MSM_LS 3;
BA_ "VNECUDiagnostic" BU_ MSM_LS 4;
BA_ "ECU_Id" BU_ MSM_LS 61;
BA_ "SourceId" BU_ MSM_LS 168;
BA_ "VNECUPrimaryTriggering" BU_ HBSM_LS 2;
BA_ "VNECUAllNodes" BU_ HBSM_LS 2;
BA_ "VNECUDiagnostic" BU_ HBSM_LS 4;
BA_ "ECU_Id" BU_ HBSM_LS 63;
BA_ "SourceId" BU_ HBSM_LS 115;
BA_ "VNECUPrimaryTriggering" BU_ SCL_LS 2;
BA_ "VNECUAllNodes" BU_ SCL_LS 2;
BA_ "VNECUDiagnostic" BU_ SCL_LS 4;
BA_ "ECU_Id" BU_ SCL_LS 60;
BA_ "SourceId" BU_ SCL_LS 194;
BA_ "VNECUPrimaryTriggering" BU_ ECC_LS 2;
BA_ "VNECUIntermediate" BU_ ECC_LS 2;
BA_ "VNECUAllNodes" BU_ ECC_LS 3;
BA_ "VNECUDiagnostic" BU_ ECC_LS 4;
BA_ "ECU_Id" BU_ ECC_LS 49;
BA_ "SourceId" BU_ ECC_LS 153;
BA_ "VNECUPrimaryTriggering" BU_ RadioHead_LS 2;
BA_ "VNECURemoteDiagnostics" BU_ RadioHead_LS 1;
BA_ "VNECUIntermediate" BU_ RadioHead_LS 2;
BA_ "VNECUInfotainment" BU_ RadioHead_LS 3;
BA_ "VNECUAllNodes" BU_ RadioHead_LS 3;
BA_ "VNECUDiagnostic" BU_ RadioHead_LS 4;
BA_ "ECU_Id" BU_ RadioHead_LS 36;
BA_ "SourceId" BU_ RadioHead_LS 128;
BA_ "VNECUPrimaryTriggering" BU_ PEPS_LS 2;
BA_ "VNECUIntermediate" BU_ PEPS_LS 2;
BA_ "VNECUAllNodes" BU_ PEPS_LS 3;
BA_ "VNECUDiagnostic" BU_ PEPS_LS 4;
BA_ "ECU_Id" BU_ PEPS_LS 34;
BA_ "SourceId" BU_ PEPS_LS 175;
BA_ "VNECUPrimaryTriggering" BU_ IPC_LS 2;
BA_ "VNECUParkedVehicle" BU_ IPC_LS 2;
BA_ "VNECUIntermediate" BU_ IPC_LS 2;
BA_ "VNECUInfotainment" BU_ IPC_LS 2;
BA_ "VNECUAllNodes" BU_ IPC_LS 3;
BA_ "VNECUDiagnostic" BU_ IPC_LS 4;
BA_ "ECU_Id" BU_ IPC_LS 44;
BA_ "SourceId" BU_ IPC_LS 96;
BA_ "VNECUPrimaryTriggering" BU_ AOS_LS 2;
BA_ "VNECUAllNodes" BU_ AOS_LS 2;
BA_ "VNECUDiagnostic" BU_ AOS_LS 4;
BA_ "ECU_Id" BU_ AOS_LS 37;
BA_ "SourceId" BU_ AOS_LS 89;
BA_ "VNECUPrimaryTriggering" BU_ SDM_LS 2;
BA_ "VNECUAllNodes" BU_ SDM_LS 2;
BA_ "VNECUDiagnostic" BU_ SDM_LS 4;
BA_ "ECU_Id" BU_ SDM_LS 39;
BA_ "SourceId" BU_ SDM_LS 88;
BA_ "VNECUPrimaryTriggering" BU_ TIM_LS 2;
BA_ "VNECUParkedVehicle" BU_ TIM_LS 2;
BA_ "VNECUInfotainment" BU_ TIM_LS 3;
BA_ "VNECUAllNodes" BU_ TIM_LS 2;
BA_ "VNECUDiagnostic" BU_ TIM_LS 4;
BA_ "ECU_Id" BU_ TIM_LS 51;
BA_ "SourceId" BU_ TIM_LS 117;
BA_ "VNECUPrimaryTriggering" BU_ BCM_LS 2;
BA_ "VNECUParkedVehicle" BU_ BCM_LS 3;
BA_ "VNECURemoteDiagnostics" BU_ BCM_LS 2;
BA_ "VNECUIntermediate" BU_ BCM_LS 3;
BA_ "VNECUInfotainment" BU_ BCM_LS 2;
BA_ "VNECUAllNodes" BU_ BCM_LS 3;
BA_ "VNECUDiagnostic" BU_ BCM_LS 4;
BA_ "ECU_Id" BU_ BCM_LS 33;
BA_ "SourceId" BU_ BCM_LS 64;
BA_ "MessageSubnet" BO_ 2152079360 0;
BA_ "GenMsgDelayTime" BO_ 2152079360 100;
BA_ "MessageSubnet" BO_ 2152873984 0;
BA_ "GenMsgDelayTime" BO_ 2152873984 100;
BA_ "MessageSubnet" BO_ 2152792064 0;
BA_ "GenMsgDelayTime" BO_ 2152792064 100;
BA_ "MessageSubnet" BO_ 2154610688 0;
BA_ "GenMsgDelayTime" BO_ 2154610688 100;
BA_ "MessageSubnet" BO_ 2150694912 0;
BA_ "GenMsgDelayTime" BO_ 2150694912 100;
BA_ "MessageSubnet" BO_ 2150678528 0;
BA_ "GenMsgDelayTime" BO_ 2150678528 100;
BA_ "Prio" BO_ 946 0;
BA_ "MessageSubnet" BO_ 946 0;
BA_ "DiagResponse" BO_ 946 1;
BA_ "Prio" BO_ 178 0;
BA_ "MessageSubnet" BO_ 178 0;
BA_ "DiagRequest" BO_ 178 1;
BA_ "MessageSubnet" BO_ 2150924288 0;
BA_ "GenMsgDelayTime" BO_ 2150924288 100;
BA_ "MessageSubnet" BO_ 2152062976 0;
BA_ "GenMsgCycleTime" BO_ 2152062976 500;
BA_ "GenMsgSendType" BO_ 2152062976 0;
BA_ "MessageSubnet" BO_ 2155503616 0;
BA_ "GenMsgDelayTime" BO_ 2155503616 100;
BA_ "MessageSubnet" BO_ 2150711296 0;
BA_ "GenMsgCycleTime" BO_ 2150711296 100;
BA_ "GenMsgSendType" BO_ 2150711296 0;
BA_ "MessageSubnet" BO_ 2153406464 0;
BA_ "GenMsgDelayTime" BO_ 2153406464 100;
BA_ "MessageSubnet" BO_ 2154217472 0;
BA_ "GenMsgDelayTime" BO_ 2154217472 100;
BA_ "MessageSubnet" BO_ 2154463232 0;
BA_ "GenMsgDelayTime" BO_ 2154463232 100;
BA_ "MessageSubnet" BO_ 2154446848 0;
BA_ "GenMsgDelayTime" BO_ 2154446848 100;
BA_ "MessageSubnet" BO_ 2154332160 0;
BA_ "GenMsgDelayTime" BO_ 2154332160 100;
BA_ "MessageSubnet" BO_ 2154414080 0;
BA_ "GenMsgDelayTime" BO_ 2154414080 100;
BA_ "MessageSubnet" BO_ 2150121472 0;
BA_ "GenMsgDelayTime" BO_ 2150121472 100;
BA_ "MessageSubnet" BO_ 2150105088 0;
BA_ "GenMsgDelayTime" BO_ 2150105088 100;
BA_ "MessageSubnet" BO_ 2151194624 0;
BA_ "GenMsgDelayTime" BO_ 2151194624 100;
BA_ "MessageSubnet" BO_ 2153963520 0;
BA_ "GenMsgDelayTime" BO_ 2153963520 20;
BA_ "MessageSubnet" BO_ 2153848832 0;
BA_ "GenMsgDelayTime" BO_ 2153848832 100;
BA_ "MessageSubnet" BO_ 2153832448 0;
BA_ "GenMsgDelayTime" BO_ 2153832448 100;
BA_ "MessageSubnet" BO_ 2152144896 0;
BA_ "GenMsgDelayTime" BO_ 2152144896 100;
BA_ "MessageSubnet" BO_ 2152177664 0;
BA_ "GenMsgCycleTime" BO_ 2152177664 2000;
BA_ "GenMsgSendType" BO_ 2152177664 0;
BA_ "MessageSubnet" BO_ 2154602496 0;
BA_ "GenMsgCycleTime" BO_ 2154602496 1000;
BA_ "GenMsgSendType" BO_ 2154602496 0;
BA_ "Prio" BO_ 941 0;
BA_ "MessageSubnet" BO_ 941 0;
BA_ "DiagResponse" BO_ 941 1;
BA_ "Prio" BO_ 173 0;
BA_ "MessageSubnet" BO_ 173 0;
BA_ "DiagRequest" BO_ 173 1;
BA_ "Prio" BO_ 932 0;
BA_ "MessageSubnet" BO_ 932 0;
BA_ "DiagResponse" BO_ 932 1;
BA_ "Prio" BO_ 164 0;
BA_ "MessageSubnet" BO_ 164 0;
BA_ "DiagRequest" BO_ 164 1;
BA_ "MessageSubnet" BO_ 2154684416 0;
BA_ "GenMsgDelayTime" BO_ 2154684416 100;
BA_ "MessageSubnet" BO_ 2153906176 0;
BA_ "GenMsgDelayTime" BO_ 2153906176 100;
BA_ "MessageSubnet" BO_ 2155978752 0;
BA_ "GenMsgDelayTime" BO_ 2155978752 100;
BA_ "MessageSubnet" BO_ 2152013824 0;
BA_ "GenMsgDelayTime" BO_ 2152013824 100;
BA_ "MessageSubnet" BO_ 2159255552 0;
BA_ "GenMsgDelayTime" BO_ 2159255552 10;
BA_ "MessageSubnet" BO_ 2159247360 0;
BA_ "GenMsgDelayTime" BO_ 2159247360 10;
BA_ "Prio" BO_ 104 0;
BA_ "MessageSubnet" BO_ 104 0;
BA_ "DiagRequest" BO_ 104 1;
BA_ "Prio" BO_ 88 0;
BA_ "MessageSubnet" BO_ 88 0;
BA_ "DiagRequest" BO_ 88 1;
BA_ "Prio" BO_ 96 0;
BA_ "MessageSubnet" BO_ 96 0;
BA_ "DiagRequest" BO_ 96 1;
BA_ "Prio" BO_ 169 0;
BA_ "MessageSubnet" BO_ 169 0;
BA_ "DiagRequest" BO_ 169 1;
BA_ "Prio" BO_ 937 0;
BA_ "MessageSubnet" BO_ 937 0;
BA_ "DiagResponse" BO_ 937 1;
BA_ "GenSigDeltaValue" SG_ 2152079360 BattPrpDstTrvldExtd 1;
BA_ "GenSigSendType" SG_ 2152079360 BattPrpDstTrvldExtd 12;
BA_ "GenSigSendOnInit" SG_ 2152079360 BattPrpDstTrvldExtd 1;
BA_ "VNSigInfotainment" SG_ 2152079360 BattPrpDstTrvldExtd 1;
BA_ "SignalType" SG_ 2152079360 BattPrpDstTrvldExtd "UNM";
BA_ "SignalLongName" SG_ 2152079360 BattPrpDstTrvldExtd "Battery Propulsion Distance Traveled Extended";
BA_ "VNSigAllNodes" SG_ 2152079360 BattPrpDstTrvldExtd 1;
BA_ "GenSigSendType" SG_ 2152873984 TrlrProfSelV 10;
BA_ "SignalType" SG_ 2152873984 TrlrProfSelV "ENM";
BA_ "SignalLongName" SG_ 2152873984 TrlrProfSelV "Trailer Profile Selection Validity";
BA_ "VNSigAllNodes" SG_ 2152873984 TrlrProfSelV 1;
BA_ "GenSigSendType" SG_ 2152873984 TrlrApInvTrlrPrvReqd 10;
BA_ "GenSigSendOnInit" SG_ 2152873984 TrlrApInvTrlrPrvReqd 2;
BA_ "SignalType" SG_ 2152873984 TrlrApInvTrlrPrvReqd "BLN";
BA_ "SignalLongName" SG_ 2152873984 TrlrApInvTrlrPrvReqd "Trailering App Invisible Trailer Preview Requested";
BA_ "VNSigAllNodes" SG_ 2152873984 TrlrApInvTrlrPrvReqd 1;
BA_ "GenSigSendType" SG_ 2152873984 TrlrApAx2CamPrvReqd 10;
BA_ "GenSigSendOnInit" SG_ 2152873984 TrlrApAx2CamPrvReqd 2;
BA_ "SignalType" SG_ 2152873984 TrlrApAx2CamPrvReqd "BLN";
BA_ "SignalLongName" SG_ 2152873984 TrlrApAx2CamPrvReqd "Trailering App Aux 2 Camera Preview Requested";
BA_ "VNSigAllNodes" SG_ 2152873984 TrlrApAx2CamPrvReqd 1;
BA_ "GenSigSendType" SG_ 2152873984 TrlrApAx1CamPrvReqd 10;
BA_ "GenSigSendOnInit" SG_ 2152873984 TrlrApAx1CamPrvReqd 2;
BA_ "SignalType" SG_ 2152873984 TrlrApAx1CamPrvReqd "BLN";
BA_ "SignalLongName" SG_ 2152873984 TrlrApAx1CamPrvReqd "Trailering App Aux 1 Camera Preview Requested";
BA_ "VNSigAllNodes" SG_ 2152873984 TrlrApAx1CamPrvReqd 1;
BA_ "GenSigDeltaValue" SG_ 2152873984 TrlrHght 1;
BA_ "GenSigSendType" SG_ 2152873984 TrlrHght 12;
BA_ "GenSigSendOnInit" SG_ 2152873984 TrlrHght 2;
BA_ "SignalType" SG_ 2152873984 TrlrHght "UNM";
BA_ "SignalLongName" SG_ 2152873984 TrlrHght "Trailer Height";
BA_ "VNSigAllNodes" SG_ 2152873984 TrlrHght 1;
BA_ "GenSigDeltaValue" SG_ 2152873984 TrlrWdth 1;
BA_ "GenSigSendType" SG_ 2152873984 TrlrWdth 12;
BA_ "GenSigSendOnInit" SG_ 2152873984 TrlrWdth 2;
BA_ "SignalType" SG_ 2152873984 TrlrWdth "UNM";
BA_ "SignalLongName" SG_ 2152873984 TrlrWdth "Trailer Width";
BA_ "VNSigAllNodes" SG_ 2152873984 TrlrWdth 1;
BA_ "GenSigDeltaValue" SG_ 2152873984 TrlrLen 1;
BA_ "GenSigSendType" SG_ 2152873984 TrlrLen 12;
BA_ "GenSigSendOnInit" SG_ 2152873984 TrlrLen 2;
BA_ "SignalType" SG_ 2152873984 TrlrLen "UNM";
BA_ "SignalLongName" SG_ 2152873984 TrlrLen "Trailer Length";
BA_ "VNSigAllNodes" SG_ 2152873984 TrlrLen 1;
BA_ "GenSigSendType" SG_ 2152873984 TrlrAxlCnt 10;
BA_ "GenSigSendOnInit" SG_ 2152873984 TrlrAxlCnt 2;
BA_ "SignalType" SG_ 2152873984 TrlrAxlCnt "ENM";
BA_ "SignalLongName" SG_ 2152873984 TrlrAxlCnt "Trailer Axle Count";
BA_ "VNSigAllNodes" SG_ 2152873984 TrlrAxlCnt 1;
BA_ "GenSigSendType" SG_ 2152873984 TrlrHtchTyp 10;
BA_ "GenSigSendOnInit" SG_ 2152873984 TrlrHtchTyp 2;
BA_ "SignalType" SG_ 2152873984 TrlrHtchTyp "ENM";
BA_ "SignalLongName" SG_ 2152873984 TrlrHtchTyp "Trailer Hitch Type";
BA_ "VNSigAllNodes" SG_ 2152873984 TrlrHtchTyp 1;
BA_ "GenSigSendType" SG_ 2152873984 TrlrTyp 10;
BA_ "GenSigSendOnInit" SG_ 2152873984 TrlrTyp 2;
BA_ "SignalType" SG_ 2152873984 TrlrTyp "ENM";
BA_ "SignalLongName" SG_ 2152873984 TrlrTyp "Trailer Type";
BA_ "VNSigAllNodes" SG_ 2152873984 TrlrTyp 1;
BA_ "GenSigSendType" SG_ 2152873984 TrlrProfSel 10;
BA_ "SignalType" SG_ 2152873984 TrlrProfSel "ENM";
BA_ "SignalLongName" SG_ 2152873984 TrlrProfSel "Trailer Profile Selection";
BA_ "VNSigAllNodes" SG_ 2152873984 TrlrProfSel 1;
BA_ "GenSigSendType" SG_ 2152873984 TrlrPrfDltn 10;
BA_ "SignalType" SG_ 2152873984 TrlrPrfDltn "ENM";
BA_ "SignalLongName" SG_ 2152873984 TrlrPrfDltn "Trailer Profile Deletion";
BA_ "VNSigAllNodes" SG_ 2152873984 TrlrPrfDltn 1;
BA_ "GenSigSendType" SG_ 2152792064 Aux2CamConnStat 10;
BA_ "GenSigSendOnInit" SG_ 2152792064 Aux2CamConnStat 2;
BA_ "SignalType" SG_ 2152792064 Aux2CamConnStat "ENM";
BA_ "SignalLongName" SG_ 2152792064 Aux2CamConnStat "Aux2 Camera Connection Status";
BA_ "VNSigAllNodes" SG_ 2152792064 Aux2CamConnStat 1;
BA_ "GenSigSendType" SG_ 2152792064 Aux1CamConnStat 10;
BA_ "GenSigSendOnInit" SG_ 2152792064 Aux1CamConnStat 2;
BA_ "SignalType" SG_ 2152792064 Aux1CamConnStat "ENM";
BA_ "SignalLongName" SG_ 2152792064 Aux1CamConnStat "Aux1 Camera Connection Status";
BA_ "VNSigAllNodes" SG_ 2152792064 Aux1CamConnStat 1;
BA_ "GenSigDeltaValue" SG_ 2152792064 InvTrlrAx1CamPlmtFBRll 1;
BA_ "GenSigSendType" SG_ 2152792064 InvTrlrAx1CamPlmtFBRll 12;
BA_ "GenSigSendOnInit" SG_ 2152792064 InvTrlrAx1CamPlmtFBRll 2;
BA_ "SignalType" SG_ 2152792064 InvTrlrAx1CamPlmtFBRll "SNM";
BA_ "SignalLongName" SG_ 2152792064 InvTrlrAx1CamPlmtFBRll "Invisible Trailer Aux1 Camera Placement Feedback Roll";
BA_ "VNSigAllNodes" SG_ 2152792064 InvTrlrAx1CamPlmtFBRll 1;
BA_ "GenSigDeltaValue" SG_ 2152792064 InvTrlrAx1CamPlmtFBPtch 1;
BA_ "GenSigSendType" SG_ 2152792064 InvTrlrAx1CamPlmtFBPtch 12;
BA_ "GenSigSendOnInit" SG_ 2152792064 InvTrlrAx1CamPlmtFBPtch 2;
BA_ "SignalType" SG_ 2152792064 InvTrlrAx1CamPlmtFBPtch "SNM";
BA_ "SignalLongName" SG_ 2152792064 InvTrlrAx1CamPlmtFBPtch "Invisible Trailer Aux1 Camera Placement Feedback Pitch";
BA_ "VNSigAllNodes" SG_ 2152792064 InvTrlrAx1CamPlmtFBPtch 1;
BA_ "GenSigDeltaValue" SG_ 2152792064 InvTrlrAx1CamPlmtFBY 1;
BA_ "GenSigSendType" SG_ 2152792064 InvTrlrAx1CamPlmtFBY 12;
BA_ "GenSigSendOnInit" SG_ 2152792064 InvTrlrAx1CamPlmtFBY 2;
BA_ "SignalType" SG_ 2152792064 InvTrlrAx1CamPlmtFBY "SNM";
BA_ "SignalLongName" SG_ 2152792064 InvTrlrAx1CamPlmtFBY "Invisible Trailer Aux1 Camera Placement Feedback Y";
BA_ "VNSigAllNodes" SG_ 2152792064 InvTrlrAx1CamPlmtFBY 1;
BA_ "GenSigDeltaValue" SG_ 2152792064 InvTrlrAx1CamPlmtFBX 1;
BA_ "GenSigSendType" SG_ 2152792064 InvTrlrAx1CamPlmtFBX 12;
BA_ "GenSigSendOnInit" SG_ 2152792064 InvTrlrAx1CamPlmtFBX 2;
BA_ "SignalType" SG_ 2152792064 InvTrlrAx1CamPlmtFBX "SNM";
BA_ "SignalLongName" SG_ 2152792064 InvTrlrAx1CamPlmtFBX "Invisible Trailer Aux1 Camera Placement Feedback X";
BA_ "VNSigAllNodes" SG_ 2152792064 InvTrlrAx1CamPlmtFBX 1;
BA_ "GenSigSendType" SG_ 2152792064 InvTrlrOpnlStat 10;
BA_ "GenSigSendOnInit" SG_ 2152792064 InvTrlrOpnlStat 2;
BA_ "SignalType" SG_ 2152792064 InvTrlrOpnlStat "ENM";
BA_ "SignalLongName" SG_ 2152792064 InvTrlrOpnlStat "Invisible Trailer Operational Status";
BA_ "VNSigAllNodes" SG_ 2152792064 InvTrlrOpnlStat 1;
BA_ "GenSigSendType" SG_ 2152792064 BRLmpReqd 10;
BA_ "GenSigSendOnInit" SG_ 2152792064 BRLmpReqd 2;
BA_ "SignalType" SG_ 2152792064 BRLmpReqd "BLN";
BA_ "SignalLongName" SG_ 2152792064 BRLmpReqd "Box Rail Lamp Requested";
BA_ "VNSigAllNodes" SG_ 2152792064 BRLmpReqd 1;
BA_ "GenSigSendType" SG_ 2152792064 CargoLmpReqd 10;
BA_ "GenSigSendOnInit" SG_ 2152792064 CargoLmpReqd 2;
BA_ "SignalType" SG_ 2152792064 CargoLmpReqd "BLN";
BA_ "SignalLongName" SG_ 2152792064 CargoLmpReqd "Cargo Lamp Requested";
BA_ "VNSigAllNodes" SG_ 2152792064 CargoLmpReqd 1;
BA_ "GenSigSendType" SG_ 2154610688 ClnScrnAct 10;
BA_ "GenSigSendOnInit" SG_ 2154610688 ClnScrnAct 2;
BA_ "VNSigInfotainment" SG_ 2154610688 ClnScrnAct 1;
BA_ "SignalType" SG_ 2154610688 ClnScrnAct "BLN";
BA_ "SignalLongName" SG_ 2154610688 ClnScrnAct "Clean Screen Active";
BA_ "VNSigAllNodes" SG_ 2154610688 ClnScrnAct 1;
BA_ "GenSigDeltaValue" SG_ 2150694912 TrgtChrgLvlPrctgStReqHme 1;
BA_ "GenSigSendType" SG_ 2150694912 TrgtChrgLvlPrctgStReqHme 12;
BA_ "GenSigSendOnInit" SG_ 2150694912 TrgtChrgLvlPrctgStReqHme 1;
BA_ "VNSigInfotainment" SG_ 2150694912 TrgtChrgLvlPrctgStReqHme 1;
BA_ "SignalType" SG_ 2150694912 TrgtChrgLvlPrctgStReqHme "UNM";
BA_ "SignalLongName" SG_ 2150694912 TrgtChrgLvlPrctgStReqHme "Target Charge Level Percentage Setting Request Home";
BA_ "VNSigAllNodes" SG_ 2150694912 TrgtChrgLvlPrctgStReqHme 1;
BA_ "GenSigDeltaValue" SG_ 2150694912 TrgtChrgLvlPrctgStReq 1;
BA_ "GenSigSendType" SG_ 2150694912 TrgtChrgLvlPrctgStReq 12;
BA_ "GenSigSendOnInit" SG_ 2150694912 TrgtChrgLvlPrctgStReq 1;
BA_ "VNSigInfotainment" SG_ 2150694912 TrgtChrgLvlPrctgStReq 1;
BA_ "SignalType" SG_ 2150694912 TrgtChrgLvlPrctgStReq "UNM";
BA_ "SignalLongName" SG_ 2150694912 TrgtChrgLvlPrctgStReq "Target Charge Level Percentage Setting Request";
BA_ "VNSigAllNodes" SG_ 2150694912 TrgtChrgLvlPrctgStReq 1;
BA_ "GenSigDeltaValue" SG_ 2150678528 HVDpltnMdRngPrjtdHme 1;
BA_ "GenSigSendType" SG_ 2150678528 HVDpltnMdRngPrjtdHme 12;
BA_ "GenSigSendOnInit" SG_ 2150678528 HVDpltnMdRngPrjtdHme 1;
BA_ "VNSigInfotainment" SG_ 2150678528 HVDpltnMdRngPrjtdHme 1;
BA_ "SignalType" SG_ 2150678528 HVDpltnMdRngPrjtdHme "UNM";
BA_ "SignalLongName" SG_ 2150678528 HVDpltnMdRngPrjtdHme "High Voltage Depletion Mode Range Projected Home";
BA_ "VNSigAllNodes" SG_ 2150678528 HVDpltnMdRngPrjtdHme 1;
BA_ "GenSigDeltaValue" SG_ 2150678528 TgtChrgLvlPctgCurStValHme 1;
BA_ "GenSigSendType" SG_ 2150678528 TgtChrgLvlPctgCurStValHme 12;
BA_ "GenSigSendOnInit" SG_ 2150678528 TgtChrgLvlPctgCurStValHme 1;
BA_ "VNSigInfotainment" SG_ 2150678528 TgtChrgLvlPctgCurStValHme 1;
BA_ "SignalType" SG_ 2150678528 TgtChrgLvlPctgCurStValHme "UNM";
BA_ "SignalLongName" SG_ 2150678528 TgtChrgLvlPctgCurStValHme "Target Charge Level Percentage Current Setting Value Home";
BA_ "VNSigAllNodes" SG_ 2150678528 TgtChrgLvlPctgCurStValHme 1;
BA_ "GenSigDeltaValue" SG_ 2150678528 TrgtChrgLvlPrctgCstCurrStVal 1;
BA_ "GenSigSendType" SG_ 2150678528 TrgtChrgLvlPrctgCstCurrStVal 12;
BA_ "GenSigSendOnInit" SG_ 2150678528 TrgtChrgLvlPrctgCstCurrStVal 1;
BA_ "VNSigInfotainment" SG_ 2150678528 TrgtChrgLvlPrctgCstCurrStVal 1;
BA_ "SignalType" SG_ 2150678528 TrgtChrgLvlPrctgCstCurrStVal "UNM";
BA_ "SignalLongName" SG_ 2150678528 TrgtChrgLvlPrctgCstCurrStVal "Target Charge Level Percentage Current Setting Value";
BA_ "VNSigAllNodes" SG_ 2150678528 TrgtChrgLvlPrctgCstCurrStVal 1;
BA_ "GenSigDeltaValue" SG_ 2150678528 MinTrgtChrgLvlHme 1;
BA_ "GenSigSendType" SG_ 2150678528 MinTrgtChrgLvlHme 12;
BA_ "GenSigSendOnInit" SG_ 2150678528 MinTrgtChrgLvlHme 1;
BA_ "VNSigInfotainment" SG_ 2150678528 MinTrgtChrgLvlHme 1;
BA_ "SignalType" SG_ 2150678528 MinTrgtChrgLvlHme "UNM";
BA_ "SignalLongName" SG_ 2150678528 MinTrgtChrgLvlHme "Minimum Target Charge Level Home";
BA_ "VNSigAllNodes" SG_ 2150678528 MinTrgtChrgLvlHme 1;
BA_ "GenSigDeltaValue" SG_ 2150678528 MinTrgtChrgLvl 1;
BA_ "GenSigSendType" SG_ 2150678528 MinTrgtChrgLvl 12;
BA_ "GenSigSendOnInit" SG_ 2150678528 MinTrgtChrgLvl 1;
BA_ "VNSigInfotainment" SG_ 2150678528 MinTrgtChrgLvl 1;
BA_ "SignalType" SG_ 2150678528 MinTrgtChrgLvl "UNM";
BA_ "SignalLongName" SG_ 2150678528 MinTrgtChrgLvl "Minimum Target Charge Level";
BA_ "VNSigAllNodes" SG_ 2150678528 MinTrgtChrgLvl 1;
BA_ "GenSigDeltaValue" SG_ 2150678528 HVDpltnMdRngPrjtd 1;
BA_ "GenSigSendType" SG_ 2150678528 HVDpltnMdRngPrjtd 12;
BA_ "GenSigSendOnInit" SG_ 2150678528 HVDpltnMdRngPrjtd 1;
BA_ "VNSigInfotainment" SG_ 2150678528 HVDpltnMdRngPrjtd 1;
BA_ "SignalType" SG_ 2150678528 HVDpltnMdRngPrjtd "UNM";
BA_ "SignalLongName" SG_ 2150678528 HVDpltnMdRngPrjtd "High Voltage Depletion Mode Range Projected";
BA_ "VNSigAllNodes" SG_ 2150678528 HVDpltnMdRngPrjtd 1;
BA_ "SignalType" SG_ 946 DgnInf "UNM";
BA_ "SignalLongName" SG_ 946 DgnInf "Diagnostic Information";
BA_ "VNSigDiagnostic" SG_ 946 DgnInf 1;
BA_ "VNSigAllNodes" SG_ 946 DgnInf 1;
BA_ "SignalType" SG_ 178 DgnInf "UNM";
BA_ "SignalLongName" SG_ 178 DgnInf "Diagnostic Information";
BA_ "VNSigDiagnostic" SG_ 178 DgnInf 1;
BA_ "VNSigAllNodes" SG_ 178 DgnInf 1;
BA_ "GenSigSendType" SG_ 2150924288 PrkHtrActvTmM 10;
BA_ "VNSigIntermediate" SG_ 2150924288 PrkHtrActvTmM 1;
BA_ "SignalType" SG_ 2150924288 PrkHtrActvTmM "ENM";
BA_ "SignalLongName" SG_ 2150924288 PrkHtrActvTmM "Park Heater Activation Time Mask";
BA_ "VNSigAllNodes" SG_ 2150924288 PrkHtrActvTmM 1;
BA_ "GenSigDeltaValue" SG_ 2150924288 PrkHtrActvTm 1;
BA_ "GenSigSendType" SG_ 2150924288 PrkHtrActvTm 12;
BA_ "GenSigSendOnInit" SG_ 2150924288 PrkHtrActvTm 1;
BA_ "VNSigIntermediate" SG_ 2150924288 PrkHtrActvTm 1;
BA_ "SignalType" SG_ 2150924288 PrkHtrActvTm "UNM";
BA_ "SignalLongName" SG_ 2150924288 PrkHtrActvTm "Park Heater Activation Time";
BA_ "VNSigAllNodes" SG_ 2150924288 PrkHtrActvTm 1;
BA_ "GenSigSendType" SG_ 2150924288 PrkHtrOffTmM 10;
BA_ "VNSigIntermediate" SG_ 2150924288 PrkHtrOffTmM 1;
BA_ "SignalType" SG_ 2150924288 PrkHtrOffTmM "ENM";
BA_ "SignalLongName" SG_ 2150924288 PrkHtrOffTmM "Park Heater Off Time Mask";
BA_ "VNSigAllNodes" SG_ 2150924288 PrkHtrOffTmM 1;
BA_ "GenSigDeltaValue" SG_ 2150924288 PrkHtrOffTm 1;
BA_ "GenSigSendType" SG_ 2150924288 PrkHtrOffTm 12;
BA_ "GenSigSendOnInit" SG_ 2150924288 PrkHtrOffTm 1;
BA_ "VNSigIntermediate" SG_ 2150924288 PrkHtrOffTm 1;
BA_ "SignalType" SG_ 2150924288 PrkHtrOffTm "UNM";
BA_ "SignalLongName" SG_ 2150924288 PrkHtrOffTm "Park Heater Off Time";
BA_ "VNSigAllNodes" SG_ 2150924288 PrkHtrOffTm 1;
BA_ "SignalType" SG_ 2152062976 ThrmlRefCompStatFdbck "ENM";
BA_ "SignalLongName" SG_ 2152062976 ThrmlRefCompStatFdbck "Thermal Refrigerant Compressor Status Feedback";
BA_ "VNSigAllNodes" SG_ 2152062976 ThrmlRefCompStatFdbck 1;
BA_ "SignalType" SG_ 2152062976 ThrmlRefCompSpdFdbck "UNM";
BA_ "SignalLongName" SG_ 2152062976 ThrmlRefCompSpdFdbck "Thermal Refrigerant Compressor Speed Feedback";
BA_ "VNSigAllNodes" SG_ 2152062976 ThrmlRefCompSpdFdbck 1;
BA_ "GenSigDeltaValue" SG_ 2155503616 OBHVDCCT_MinOfHr 1;
BA_ "GenSigSendType" SG_ 2155503616 OBHVDCCT_MinOfHr 12;
BA_ "PacketOrder" SG_ 2155503616 OBHVDCCT_MinOfHr 3;
BA_ "VNSigInfotainment" SG_ 2155503616 OBHVDCCT_MinOfHr 1;
BA_ "SignalType" SG_ 2155503616 OBHVDCCT_MinOfHr "UNM";
BA_ "SignalLongName" SG_ 2155503616 OBHVDCCT_MinOfHr "Off Board High Voltage DC Charging Complete Time : Minute Of Hour";
BA_ "VNSigAllNodes" SG_ 2155503616 OBHVDCCT_MinOfHr 1;
BA_ "GenSigDeltaValue" SG_ 2155503616 OBHVDCCT_HrOfDay 1;
BA_ "GenSigSendType" SG_ 2155503616 OBHVDCCT_HrOfDay 12;
BA_ "PacketOrder" SG_ 2155503616 OBHVDCCT_HrOfDay 2;
BA_ "VNSigInfotainment" SG_ 2155503616 OBHVDCCT_HrOfDay 1;
BA_ "SignalType" SG_ 2155503616 OBHVDCCT_HrOfDay "UNM";
BA_ "SignalLongName" SG_ 2155503616 OBHVDCCT_HrOfDay "Off Board High Voltage DC Charging Complete Time : Hour Of Day";
BA_ "VNSigAllNodes" SG_ 2155503616 OBHVDCCT_HrOfDay 1;
BA_ "GenSigDeltaValue" SG_ 2155503616 OBHVDCCT_DayOfWk 1;
BA_ "GenSigSendType" SG_ 2155503616 OBHVDCCT_DayOfWk 12;
BA_ "PacketOrder" SG_ 2155503616 OBHVDCCT_DayOfWk 1;
BA_ "VNSigInfotainment" SG_ 2155503616 OBHVDCCT_DayOfWk 1;
BA_ "SignalType" SG_ 2155503616 OBHVDCCT_DayOfWk "UNM";
BA_ "SignalLongName" SG_ 2155503616 OBHVDCCT_DayOfWk "Off Board High Voltage DC Charging Complete Time : Day Of Week";
BA_ "VNSigAllNodes" SG_ 2155503616 OBHVDCCT_DayOfWk 1;
BA_ "GenSigSendType" SG_ 2155503616 ChrgStatChrngScnActIndOn 10;
BA_ "VNSigInfotainment" SG_ 2155503616 ChrgStatChrngScnActIndOn 1;
BA_ "SignalType" SG_ 2155503616 ChrgStatChrngScnActIndOn "BLN";
BA_ "SignalLongName" SG_ 2155503616 ChrgStatChrngScnActIndOn "Charge Status Charging Screen Active Indication On";
BA_ "VNSigAllNodes" SG_ 2155503616 ChrgStatChrngScnActIndOn 1;
BA_ "GenSigSendType" SG_ 2155503616 EleRngEstAdjStat 10;
BA_ "VNSigInfotainment" SG_ 2155503616 EleRngEstAdjStat 1;
BA_ "SignalType" SG_ 2155503616 EleRngEstAdjStat "ENM";
BA_ "SignalLongName" SG_ 2155503616 EleRngEstAdjStat "Electric Range Estimation Adjustment Status";
BA_ "VNSigAllNodes" SG_ 2155503616 EleRngEstAdjStat 1;
BA_ "GenSigSendType" SG_ 2155503616 EleRngEstAdjCstCurrStVal 10;
BA_ "GenSigSendOnInit" SG_ 2155503616 EleRngEstAdjCstCurrStVal 2;
BA_ "VNSigInfotainment" SG_ 2155503616 EleRngEstAdjCstCurrStVal 1;
BA_ "SignalType" SG_ 2155503616 EleRngEstAdjCstCurrStVal "ENM";
BA_ "SignalLongName" SG_ 2155503616 EleRngEstAdjCstCurrStVal "Electric Range Estimation Adjustment Customization Current Setting Value";
BA_ "VNSigAllNodes" SG_ 2155503616 EleRngEstAdjCstCurrStVal 1;
BA_ "GenSigSendType" SG_ 2155503616 EleRngEstAdjCstStAvail 10;
BA_ "GenSigSendOnInit" SG_ 2155503616 EleRngEstAdjCstStAvail 2;
BA_ "VNSigInfotainment" SG_ 2155503616 EleRngEstAdjCstStAvail 1;
BA_ "SignalType" SG_ 2155503616 EleRngEstAdjCstStAvail "BLN";
BA_ "SignalLongName" SG_ 2155503616 EleRngEstAdjCstStAvail "Electric Range Estimation Adjustment Customization Setting Available";
BA_ "VNSigAllNodes" SG_ 2155503616 EleRngEstAdjCstStAvail 1;
BA_ "GenSigSendType" SG_ 2155503616 WPRSCstCurrStVal 10;
BA_ "GenSigSendOnInit" SG_ 2155503616 WPRSCstCurrStVal 2;
BA_ "VNSigInfotainment" SG_ 2155503616 WPRSCstCurrStVal 1;
BA_ "SignalType" SG_ 2155503616 WPRSCstCurrStVal "ENM";
BA_ "SignalLongName" SG_ 2155503616 WPRSCstCurrStVal "Wall Powered Remote Start Customization Current Setting Value";
BA_ "VNSigAllNodes" SG_ 2155503616 WPRSCstCurrStVal 1;
BA_ "GenSigSendType" SG_ 2155503616 WPRSCstStAvail 10;
BA_ "GenSigSendOnInit" SG_ 2155503616 WPRSCstStAvail 2;
BA_ "VNSigInfotainment" SG_ 2155503616 WPRSCstStAvail 1;
BA_ "SignalType" SG_ 2155503616 WPRSCstStAvail "BLN";
BA_ "SignalLongName" SG_ 2155503616 WPRSCstStAvail "Wall Powered Remote Start Customization Setting Available";
BA_ "VNSigAllNodes" SG_ 2155503616 WPRSCstStAvail 1;
BA_ "SignalType" SG_ 2150711296 TachEngSpd "UNM";
BA_ "SignalLongName" SG_ 2150711296 TachEngSpd "Tachometer Engine Speed";
BA_ "VNSigAllNodes" SG_ 2150711296 TachEngSpd 1;
BA_ "GenSigSendType" SG_ 2153406464 RrClsrInrAjrSwAct 10;
BA_ "GenSigSendOnInit" SG_ 2153406464 RrClsrInrAjrSwAct 1;
BA_ "SignalType" SG_ 2153406464 RrClsrInrAjrSwAct "BLN";
BA_ "SignalLongName" SG_ 2153406464 RrClsrInrAjrSwAct "Rear Closure Inner Ajar Switch Active";
BA_ "VNSigAllNodes" SG_ 2153406464 RrClsrInrAjrSwAct 1;
BA_ "GenSigSendType" SG_ 2153406464 TlgtUnavlbleIO 10;
BA_ "GenSigSendOnInit" SG_ 2153406464 TlgtUnavlbleIO 1;
BA_ "SignalType" SG_ 2153406464 TlgtUnavlbleIO "BLN";
BA_ "SignalLongName" SG_ 2153406464 TlgtUnavlbleIO "Tailgate Unavailable Indication On";
BA_ "VNSigAllNodes" SG_ 2153406464 TlgtUnavlbleIO 1;
BA_ "GenSigDeltaValue" SG_ 2154217472 CSRCR_CrtfctIdntfcn 1;
BA_ "GenSigSendType" SG_ 2154217472 CSRCR_CrtfctIdntfcn 12;
BA_ "PacketOrder" SG_ 2154217472 CSRCR_CrtfctIdntfcn 2;
BA_ "VNSigIntermediate" SG_ 2154217472 CSRCR_CrtfctIdntfcn 1;
BA_ "SignalType" SG_ 2154217472 CSRCR_CrtfctIdntfcn "UNM";
BA_ "SignalLongName" SG_ 2154217472 CSRCR_CrtfctIdntfcn "Car Sharing Revoke Certificate Request : Certificate Identification";
BA_ "GenSigSendType" SG_ 2154217472 CSRCR_Cmnd 10;
BA_ "PacketOrder" SG_ 2154217472 CSRCR_Cmnd 1;
BA_ "VNSigIntermediate" SG_ 2154217472 CSRCR_Cmnd 1;
BA_ "SignalType" SG_ 2154217472 CSRCR_Cmnd "ENM";
BA_ "SignalLongName" SG_ 2154217472 CSRCR_Cmnd "Car Sharing Revoke Certificate Request : Command";
BA_ "GenSigSendType" SG_ 2154217472 CrShrngFbsEnblReq 10;
BA_ "VNSigIntermediate" SG_ 2154217472 CrShrngFbsEnblReq 1;
BA_ "SignalType" SG_ 2154217472 CrShrngFbsEnblReq "ENM";
BA_ "SignalLongName" SG_ 2154217472 CrShrngFbsEnblReq "Car Sharing Fobs Enable Request";
BA_ "GenSigDeltaValue" SG_ 2154463232 CrShrngPhRsp2 1;
BA_ "GenSigSendType" SG_ 2154463232 CrShrngPhRsp2 12;
BA_ "VNSigIntermediate" SG_ 2154463232 CrShrngPhRsp2 1;
BA_ "SignalType" SG_ 2154463232 CrShrngPhRsp2 "UNM";
BA_ "SignalLongName" SG_ 2154463232 CrShrngPhRsp2 "Car Sharing Phone Response 2";
BA_ "GenSigDeltaValue" SG_ 2154446848 CrShrngPhRsp1 1;
BA_ "GenSigSendType" SG_ 2154446848 CrShrngPhRsp1 12;
BA_ "VNSigIntermediate" SG_ 2154446848 CrShrngPhRsp1 1;
BA_ "SignalType" SG_ 2154446848 CrShrngPhRsp1 "UNM";
BA_ "SignalLongName" SG_ 2154446848 CrShrngPhRsp1 "Car Sharing Phone Response 1";
BA_ "GenSigDeltaValue" SG_ 2154332160 CrShrngVehChlng 1;
BA_ "GenSigSendType" SG_ 2154332160 CrShrngVehChlng 12;
BA_ "VNSigIntermediate" SG_ 2154332160 CrShrngVehChlng 1;
BA_ "SignalType" SG_ 2154332160 CrShrngVehChlng "UNM";
BA_ "SignalLongName" SG_ 2154332160 CrShrngVehChlng "Car Sharing Vehicle Challenge";
BA_ "GenSigDeltaValue" SG_ 2154414080 CrShrngConnUnqIdntfr1 1;
BA_ "GenSigSendType" SG_ 2154414080 CrShrngConnUnqIdntfr1 12;
BA_ "VNSigIntermediate" SG_ 2154414080 CrShrngConnUnqIdntfr1 1;
BA_ "SignalType" SG_ 2154414080 CrShrngConnUnqIdntfr1 "UNM";
BA_ "SignalLongName" SG_ 2154414080 CrShrngConnUnqIdntfr1 "Car Sharing Connection Unique Identifier 1";
BA_ "GenSigSendType" SG_ 2150121472 RmtTrlrLtngSeqReq 10;
BA_ "GenSigSendOnInit" SG_ 2150121472 RmtTrlrLtngSeqReq 2;
BA_ "VNSigIntermediate" SG_ 2150121472 RmtTrlrLtngSeqReq 1;
BA_ "SignalType" SG_ 2150121472 RmtTrlrLtngSeqReq "ENM";
BA_ "SignalLongName" SG_ 2150121472 RmtTrlrLtngSeqReq "Remote Trailer Lighting Sequence Request";
BA_ "VNSigAllNodes" SG_ 2150121472 RmtTrlrLtngSeqReq 1;
BA_ "GenSigSendType" SG_ 2150105088 CntStckHMIRdy 10;
BA_ "GenSigSendOnInit" SG_ 2150105088 CntStckHMIRdy 2;
BA_ "VNSigInfotainment" SG_ 2150105088 CntStckHMIRdy 1;
BA_ "SignalType" SG_ 2150105088 CntStckHMIRdy "ENM";
BA_ "SignalLongName" SG_ 2150105088 CntStckHMIRdy "Center Stack Human Machine Interface Ready";
BA_ "VNSigAllNodes" SG_ 2150105088 CntStckHMIRdy 1;
BA_ "GenSigSendType" SG_ 2150105088 TrlrLtngSeqReq 10;
BA_ "GenSigSendOnInit" SG_ 2150105088 TrlrLtngSeqReq 2;
BA_ "SignalType" SG_ 2150105088 TrlrLtngSeqReq "ENM";
BA_ "SignalLongName" SG_ 2150105088 TrlrLtngSeqReq "Trailer Lighting Sequence Request";
BA_ "VNSigAllNodes" SG_ 2150105088 TrlrLtngSeqReq 1;
BA_ "GenSigSendType" SG_ 2150105088 TrlrLghtAlrtEnbld 10;
BA_ "SignalType" SG_ 2150105088 TrlrLghtAlrtEnbld "BLN";
BA_ "SignalLongName" SG_ 2150105088 TrlrLghtAlrtEnbld "Trailer Light Alerts Enabled";
BA_ "GenSigStartValue" SG_ 2150105088 TrlrLghtAlrtEnbld 1;
BA_ "VNSigAllNodes" SG_ 2150105088 TrlrLghtAlrtEnbld 1;
BA_ "GenSigSendType" SG_ 2150105088 TrlRvsLghtFldEnbld 10;
BA_ "SignalType" SG_ 2150105088 TrlRvsLghtFldEnbld "BLN";
BA_ "SignalLongName" SG_ 2150105088 TrlRvsLghtFldEnbld "Trailer Reverse Light Failed Enabled";
BA_ "VNSigAllNodes" SG_ 2150105088 TrlRvsLghtFldEnbld 1;
BA_ "GenSigSendType" SG_ 2150105088 TrlrThftAlrtEnbld 10;
BA_ "SignalType" SG_ 2150105088 TrlrThftAlrtEnbld "BLN";
BA_ "SignalLongName" SG_ 2150105088 TrlrThftAlrtEnbld "Trailer Theft Alert Enabled";
BA_ "VNSigAllNodes" SG_ 2150105088 TrlrThftAlrtEnbld 1;
BA_ "GenSigSendType" SG_ 2151194624 TrlrThftIndOn 10;
BA_ "VNSigInfotainment" SG_ 2151194624 TrlrThftIndOn 1;
BA_ "SignalType" SG_ 2151194624 TrlrThftIndOn "BLN";
BA_ "SignalLongName" SG_ 2151194624 TrlrThftIndOn "Trailer Theft Indication On";
BA_ "VNSigAllNodes" SG_ 2151194624 TrlrThftIndOn 1;
BA_ "GenSigSendType" SG_ 2151194624 TrlrPwrSplyLdPrsnt 10;
BA_ "SignalType" SG_ 2151194624 TrlrPwrSplyLdPrsnt "BLN";
BA_ "SignalLongName" SG_ 2151194624 TrlrPwrSplyLdPrsnt "Trailer Power Supply Load Present";
BA_ "VNSigAllNodes" SG_ 2151194624 TrlrPwrSplyLdPrsnt 1;
BA_ "GenSigSendType" SG_ 2151194624 TrlrDisconndIndOn 10;
BA_ "VNSigInfotainment" SG_ 2151194624 TrlrDisconndIndOn 1;
BA_ "SignalType" SG_ 2151194624 TrlrDisconndIndOn "BLN";
BA_ "SignalLongName" SG_ 2151194624 TrlrDisconndIndOn "Trailer Disconnected Indication On";
BA_ "VNSigAllNodes" SG_ 2151194624 TrlrDisconndIndOn 1;
BA_ "GenSigDeltaValue" SG_ 2151194624 TrlrConnCntr 1;
BA_ "GenSigSendType" SG_ 2151194624 TrlrConnCntr 12;
BA_ "GenSigSendOnInit" SG_ 2151194624 TrlrConnCntr 1;
BA_ "VNSigInfotainment" SG_ 2151194624 TrlrConnCntr 1;
BA_ "SignalType" SG_ 2151194624 TrlrConnCntr "UNM";
BA_ "SignalLongName" SG_ 2151194624 TrlrConnCntr "Trailer Connection Counter";
BA_ "VNSigAllNodes" SG_ 2151194624 TrlrConnCntr 1;
BA_ "GenSigSendType" SG_ 2151194624 TrlrConnStat 10;
BA_ "GenSigSendOnInit" SG_ 2151194624 TrlrConnStat 1;
BA_ "VNSigInfotainment" SG_ 2151194624 TrlrConnStat 1;
BA_ "SignalType" SG_ 2151194624 TrlrConnStat "ENM";
BA_ "SignalLongName" SG_ 2151194624 TrlrConnStat "Trailer Connection Status";
BA_ "VNSigAllNodes" SG_ 2151194624 TrlrConnStat 1;
BA_ "GenSigSendType" SG_ 2153963520 USBProgInPrgrs_317 10;
BA_ "SignalType" SG_ 2153963520 USBProgInPrgrs_317 "BLN";
BA_ "SignalLongName" SG_ 2153963520 USBProgInPrgrs_317 "USB Programming In Progress";
BA_ "VNSigAllNodes" SG_ 2153963520 USBProgInPrgrs_317 1;
BA_ "GenSigSendType" SG_ 2153963520 RSIHMIAnmSt 10;
BA_ "GenSigSendOnInit" SG_ 2153963520 RSIHMIAnmSt 1;
BA_ "VNSigInfotainment" SG_ 2153963520 RSIHMIAnmSt 1;
BA_ "SignalType" SG_ 2153963520 RSIHMIAnmSt "ENM";
BA_ "SignalLongName" SG_ 2153963520 RSIHMIAnmSt "Rear Seat Infotainment Human Machine Interface Animation State";
BA_ "VNSigAllNodes" SG_ 2153963520 RSIHMIAnmSt 1;
BA_ "GenSigSendType" SG_ 2153963520 RSIHMIRdy 10;
BA_ "GenSigSendOnInit" SG_ 2153963520 RSIHMIRdy 1;
BA_ "VNSigInfotainment" SG_ 2153963520 RSIHMIRdy 1;
BA_ "SignalType" SG_ 2153963520 RSIHMIRdy "BLN";
BA_ "SignalLongName" SG_ 2153963520 RSIHMIRdy "Rear Seat Infotainment Human Machine Interface Ready";
BA_ "VNSigAllNodes" SG_ 2153963520 RSIHMIRdy 1;
BA_ "GenSigSendType" SG_ 2153963520 LRStStatDispAct 10;
BA_ "GenSigSendOnInit" SG_ 2153963520 LRStStatDispAct 1;
BA_ "SignalType" SG_ 2153963520 LRStStatDispAct "BLN";
BA_ "SignalLongName" SG_ 2153963520 LRStStatDispAct "Left Rear Seat Status Display Active";
BA_ "VNSigAllNodes" SG_ 2153963520 LRStStatDispAct 1;
BA_ "GenSigSendType" SG_ 2153963520 RRStStatDispAct 10;
BA_ "GenSigSendOnInit" SG_ 2153963520 RRStStatDispAct 1;
BA_ "SignalType" SG_ 2153963520 RRStStatDispAct "BLN";
BA_ "SignalLongName" SG_ 2153963520 RRStStatDispAct "Right Rear Seat Status Display Active";
BA_ "VNSigAllNodes" SG_ 2153963520 RRStStatDispAct 1;
BA_ "GenSigDeltaValue" SG_ 2153848832 EUSSE_MaxBarDspRng 1;
BA_ "GenSigSendType" SG_ 2153848832 EUSSE_MaxBarDspRng 12;
BA_ "GenSigSendOnInit" SG_ 2153848832 EUSSE_MaxBarDspRng 1;
BA_ "PacketOrder" SG_ 2153848832 EUSSE_MaxBarDspRng 9;
BA_ "VNSigInfotainment" SG_ 2153848832 EUSSE_MaxBarDspRng 1;
BA_ "SignalType" SG_ 2153848832 EUSSE_MaxBarDspRng "UNM";
BA_ "SignalLongName" SG_ 2153848832 EUSSE_MaxBarDspRng "Energy Usage Score Scaling Extended : Maximum Bar Display Range";
BA_ "VNSigAllNodes" SG_ 2153848832 EUSSE_MaxBarDspRng 1;
BA_ "GenSigDeltaValue" SG_ 2153848832 EUSSE_ITEgUgScrMxScVal 1;
BA_ "GenSigSendType" SG_ 2153848832 EUSSE_ITEgUgScrMxScVal 12;
BA_ "GenSigSendOnInit" SG_ 2153848832 EUSSE_ITEgUgScrMxScVal 1;
BA_ "PacketOrder" SG_ 2153848832 EUSSE_ITEgUgScrMxScVal 8;
BA_ "VNSigInfotainment" SG_ 2153848832 EUSSE_ITEgUgScrMxScVal 1;
BA_ "SignalType" SG_ 2153848832 EUSSE_ITEgUgScrMxScVal "UNM";
BA_ "SignalLongName" SG_ 2153848832 EUSSE_ITEgUgScrMxScVal "Energy Usage Score Scaling Extended : Inside Temperature Energy Usage Score Maximum Scale Value";
BA_ "VNSigAllNodes" SG_ 2153848832 EUSSE_ITEgUgScrMxScVal 1;
BA_ "GenSigDeltaValue" SG_ 2153848832 EUSSE_TrEgUgScrMxScVal 1;
BA_ "GenSigSendType" SG_ 2153848832 EUSSE_TrEgUgScrMxScVal 12;
BA_ "GenSigSendOnInit" SG_ 2153848832 EUSSE_TrEgUgScrMxScVal 1;
BA_ "PacketOrder" SG_ 2153848832 EUSSE_TrEgUgScrMxScVal 7;
BA_ "VNSigInfotainment" SG_ 2153848832 EUSSE_TrEgUgScrMxScVal 1;
BA_ "SignalType" SG_ 2153848832 EUSSE_TrEgUgScrMxScVal "UNM";
BA_ "SignalLongName" SG_ 2153848832 EUSSE_TrEgUgScrMxScVal "Energy Usage Score Scaling Extended : Terrain Energy Usage Score Maximum Scale Value";
BA_ "VNSigAllNodes" SG_ 2153848832 EUSSE_TrEgUgScrMxScVal 1;
BA_ "GenSigDeltaValue" SG_ 2153848832 EUSSE_TcEgUgScrMxScVal 1;
BA_ "GenSigSendType" SG_ 2153848832 EUSSE_TcEgUgScrMxScVal 12;
BA_ "GenSigSendOnInit" SG_ 2153848832 EUSSE_TcEgUgScrMxScVal 1;
BA_ "PacketOrder" SG_ 2153848832 EUSSE_TcEgUgScrMxScVal 6;
BA_ "VNSigInfotainment" SG_ 2153848832 EUSSE_TcEgUgScrMxScVal 1;
BA_ "SignalType" SG_ 2153848832 EUSSE_TcEgUgScrMxScVal "UNM";
BA_ "SignalLongName" SG_ 2153848832 EUSSE_TcEgUgScrMxScVal "Energy Usage Score Scaling Extended : Technique Energy Usage Score Maximum Scale Value";
BA_ "VNSigAllNodes" SG_ 2153848832 EUSSE_TcEgUgScrMxScVal 1;
BA_ "GenSigDeltaValue" SG_ 2153848832 EUSSE_OTEgUgScrMxScVal 1;
BA_ "GenSigSendType" SG_ 2153848832 EUSSE_OTEgUgScrMxScVal 12;
BA_ "GenSigSendOnInit" SG_ 2153848832 EUSSE_OTEgUgScrMxScVal 1;
BA_ "PacketOrder" SG_ 2153848832 EUSSE_OTEgUgScrMxScVal 5;
BA_ "VNSigInfotainment" SG_ 2153848832 EUSSE_OTEgUgScrMxScVal 1;
BA_ "SignalType" SG_ 2153848832 EUSSE_OTEgUgScrMxScVal "UNM";
BA_ "SignalLongName" SG_ 2153848832 EUSSE_OTEgUgScrMxScVal "Energy Usage Score Scaling Extended : Outside Temperature Energy Usage Score Maximum Scale Value";
BA_ "VNSigAllNodes" SG_ 2153848832 EUSSE_OTEgUgScrMxScVal 1;
BA_ "GenSigDeltaValue" SG_ 2153848832 EUSSE_TrEgUgScrMnScVal 1;
BA_ "GenSigSendType" SG_ 2153848832 EUSSE_TrEgUgScrMnScVal 12;
BA_ "GenSigSendOnInit" SG_ 2153848832 EUSSE_TrEgUgScrMnScVal 1;
BA_ "PacketOrder" SG_ 2153848832 EUSSE_TrEgUgScrMnScVal 4;
BA_ "VNSigInfotainment" SG_ 2153848832 EUSSE_TrEgUgScrMnScVal 1;
BA_ "SignalType" SG_ 2153848832 EUSSE_TrEgUgScrMnScVal "SNM";
BA_ "SignalLongName" SG_ 2153848832 EUSSE_TrEgUgScrMnScVal "Energy Usage Score Scaling Extended : Terrain Energy Usage Score Minimum Scale Value";
BA_ "VNSigAllNodes" SG_ 2153848832 EUSSE_TrEgUgScrMnScVal 1;
BA_ "GenSigDeltaValue" SG_ 2153848832 EUSSE_TcEgUgScrMnScVal 1;
BA_ "GenSigSendType" SG_ 2153848832 EUSSE_TcEgUgScrMnScVal 12;
BA_ "GenSigSendOnInit" SG_ 2153848832 EUSSE_TcEgUgScrMnScVal 1;
BA_ "PacketOrder" SG_ 2153848832 EUSSE_TcEgUgScrMnScVal 3;
BA_ "VNSigInfotainment" SG_ 2153848832 EUSSE_TcEgUgScrMnScVal 1;
BA_ "SignalType" SG_ 2153848832 EUSSE_TcEgUgScrMnScVal "SNM";
BA_ "SignalLongName" SG_ 2153848832 EUSSE_TcEgUgScrMnScVal "Energy Usage Score Scaling Extended : Technique Energy Usage Score Minimum Scale Value";
BA_ "VNSigAllNodes" SG_ 2153848832 EUSSE_TcEgUgScrMnScVal 1;
BA_ "GenSigDeltaValue" SG_ 2153848832 EUSSE_OTEgUgScrMnScVal 1;
BA_ "GenSigSendType" SG_ 2153848832 EUSSE_OTEgUgScrMnScVal 12;
BA_ "GenSigSendOnInit" SG_ 2153848832 EUSSE_OTEgUgScrMnScVal 1;
BA_ "PacketOrder" SG_ 2153848832 EUSSE_OTEgUgScrMnScVal 2;
BA_ "VNSigInfotainment" SG_ 2153848832 EUSSE_OTEgUgScrMnScVal 1;
BA_ "SignalType" SG_ 2153848832 EUSSE_OTEgUgScrMnScVal "SNM";
BA_ "SignalLongName" SG_ 2153848832 EUSSE_OTEgUgScrMnScVal "Energy Usage Score Scaling Extended : Outside Temperature Energy Usage Score Minimum Scale Value";
BA_ "VNSigAllNodes" SG_ 2153848832 EUSSE_OTEgUgScrMnScVal 1;
BA_ "GenSigDeltaValue" SG_ 2153848832 EUSSE_ITEgUgScrMnScVal 1;
BA_ "GenSigSendType" SG_ 2153848832 EUSSE_ITEgUgScrMnScVal 12;
BA_ "GenSigSendOnInit" SG_ 2153848832 EUSSE_ITEgUgScrMnScVal 1;
BA_ "PacketOrder" SG_ 2153848832 EUSSE_ITEgUgScrMnScVal 1;
BA_ "VNSigInfotainment" SG_ 2153848832 EUSSE_ITEgUgScrMnScVal 1;
BA_ "SignalType" SG_ 2153848832 EUSSE_ITEgUgScrMnScVal "SNM";
BA_ "SignalLongName" SG_ 2153848832 EUSSE_ITEgUgScrMnScVal "Energy Usage Score Scaling Extended : Inside Temperature Energy Usage Score Minimum Scale Value";
BA_ "VNSigAllNodes" SG_ 2153848832 EUSSE_ITEgUgScrMnScVal 1;
BA_ "GenSigDeltaValue" SG_ 2153832448 EUSE_TtEngyUsgScrAvVal 1;
BA_ "GenSigSendType" SG_ 2153832448 EUSE_TtEngyUsgScrAvVal 12;
BA_ "GenSigSendOnInit" SG_ 2153832448 EUSE_TtEngyUsgScrAvVal 1;
BA_ "PacketOrder" SG_ 2153832448 EUSE_TtEngyUsgScrAvVal 5;
BA_ "VNSigInfotainment" SG_ 2153832448 EUSE_TtEngyUsgScrAvVal 1;
BA_ "SignalType" SG_ 2153832448 EUSE_TtEngyUsgScrAvVal "SNM";
BA_ "SignalLongName" SG_ 2153832448 EUSE_TtEngyUsgScrAvVal "Energy Usage Score Extended : Total Energy Usage Score Value";
BA_ "VNSigAllNodes" SG_ 2153832448 EUSE_TtEngyUsgScrAvVal 1;
BA_ "GenSigDeltaValue" SG_ 2153832448 EUSE_TrEngyUsgScrAvVal 1;
BA_ "GenSigSendType" SG_ 2153832448 EUSE_TrEngyUsgScrAvVal 12;
BA_ "GenSigSendOnInit" SG_ 2153832448 EUSE_TrEngyUsgScrAvVal 1;
BA_ "PacketOrder" SG_ 2153832448 EUSE_TrEngyUsgScrAvVal 4;
BA_ "VNSigInfotainment" SG_ 2153832448 EUSE_TrEngyUsgScrAvVal 1;
BA_ "SignalType" SG_ 2153832448 EUSE_TrEngyUsgScrAvVal "SNM";
BA_ "SignalLongName" SG_ 2153832448 EUSE_TrEngyUsgScrAvVal "Energy Usage Score Extended : Terrain Energy Usage Score Average Value";
BA_ "VNSigAllNodes" SG_ 2153832448 EUSE_TrEngyUsgScrAvVal 1;
BA_ "GenSigDeltaValue" SG_ 2153832448 EUSE_TcEngyUsgScrAvVal 1;
BA_ "GenSigSendType" SG_ 2153832448 EUSE_TcEngyUsgScrAvVal 12;
BA_ "GenSigSendOnInit" SG_ 2153832448 EUSE_TcEngyUsgScrAvVal 1;
BA_ "PacketOrder" SG_ 2153832448 EUSE_TcEngyUsgScrAvVal 3;
BA_ "VNSigInfotainment" SG_ 2153832448 EUSE_TcEngyUsgScrAvVal 1;
BA_ "SignalType" SG_ 2153832448 EUSE_TcEngyUsgScrAvVal "SNM";
BA_ "SignalLongName" SG_ 2153832448 EUSE_TcEngyUsgScrAvVal "Energy Usage Score Extended : Technique Energy Usage Score Average Value";
BA_ "VNSigAllNodes" SG_ 2153832448 EUSE_TcEngyUsgScrAvVal 1;
BA_ "GenSigDeltaValue" SG_ 2153832448 EUSE_OTEngyUsgScrAvVal 1;
BA_ "GenSigSendType" SG_ 2153832448 EUSE_OTEngyUsgScrAvVal 12;
BA_ "GenSigSendOnInit" SG_ 2153832448 EUSE_OTEngyUsgScrAvVal 1;
BA_ "PacketOrder" SG_ 2153832448 EUSE_OTEngyUsgScrAvVal 2;
BA_ "VNSigInfotainment" SG_ 2153832448 EUSE_OTEngyUsgScrAvVal 1;
BA_ "SignalType" SG_ 2153832448 EUSE_OTEngyUsgScrAvVal "SNM";
BA_ "SignalLongName" SG_ 2153832448 EUSE_OTEngyUsgScrAvVal "Energy Usage Score Extended : Outside Temperature Energy Usage Score Average Value";
BA_ "VNSigAllNodes" SG_ 2153832448 EUSE_OTEngyUsgScrAvVal 1;
BA_ "GenSigDeltaValue" SG_ 2153832448 EUSE_ITEngyUsgScrAvVal 1;
BA_ "GenSigSendType" SG_ 2153832448 EUSE_ITEngyUsgScrAvVal 12;
BA_ "GenSigSendOnInit" SG_ 2153832448 EUSE_ITEngyUsgScrAvVal 1;
BA_ "PacketOrder" SG_ 2153832448 EUSE_ITEngyUsgScrAvVal 1;
BA_ "VNSigInfotainment" SG_ 2153832448 EUSE_ITEngyUsgScrAvVal 1;
BA_ "SignalType" SG_ 2153832448 EUSE_ITEngyUsgScrAvVal "SNM";
BA_ "SignalLongName" SG_ 2153832448 EUSE_ITEngyUsgScrAvVal "Energy Usage Score Extended : Inside Temperature Energy Usage Score Average Value";
BA_ "VNSigAllNodes" SG_ 2153832448 EUSE_ITEngyUsgScrAvVal 1;
BA_ "GenSigDeltaValue" SG_ 2152144896 ACCPwrReqd 1;
BA_ "GenSigSendType" SG_ 2152144896 ACCPwrReqd 12;
BA_ "SignalType" SG_ 2152144896 ACCPwrReqd "UNM";
BA_ "SignalLongName" SG_ 2152144896 ACCPwrReqd "Air Conditioning Compressor Power Requested";
BA_ "VNSigAllNodes" SG_ 2152144896 ACCPwrReqd 1;
BA_ "GenSigDeltaValue" SG_ 2152144896 NWPwrAvl 1;
BA_ "GenSigSendType" SG_ 2152144896 NWPwrAvl 12;
BA_ "SignalType" SG_ 2152144896 NWPwrAvl "UNM";
BA_ "SignalLongName" SG_ 2152144896 NWPwrAvl "Net Wall Power Available";
BA_ "VNSigAllNodes" SG_ 2152144896 NWPwrAvl 1;
BA_ "GenSigDeltaValue" SG_ 2152144896 DrvCyclFulUsdHiRes 1;
BA_ "GenSigSendType" SG_ 2152144896 DrvCyclFulUsdHiRes 12;
BA_ "GenSigSendOnInit" SG_ 2152144896 DrvCyclFulUsdHiRes 1;
BA_ "VNSigInfotainment" SG_ 2152144896 DrvCyclFulUsdHiRes 1;
BA_ "SignalType" SG_ 2152144896 DrvCyclFulUsdHiRes "UNM";
BA_ "SignalLongName" SG_ 2152144896 DrvCyclFulUsdHiRes "Drive Cycle Fuel Used High Resolution";
BA_ "VNSigAllNodes" SG_ 2152144896 DrvCyclFulUsdHiRes 1;
BA_ "VNSigInfotainment" SG_ 2152177664 RmtRflshElecPwrRdness 1;
BA_ "SignalType" SG_ 2152177664 RmtRflshElecPwrRdness "UNM";
BA_ "SignalLongName" SG_ 2152177664 RmtRflshElecPwrRdness "Remote Reflash Electric Power Readiness";
BA_ "VNSigAllNodes" SG_ 2152177664 RmtRflshElecPwrRdness 1;
BA_ "PacketOrder" SG_ 2154602496 EHCCT_EHtrCrOutClntTmp 4;
BA_ "GenSigStartValue" SG_ 2154602496 EHCCT_EHtrCrOutClntTmp 565.428109854604;
BA_ "SignalType" SG_ 2154602496 EHCCT_EHtrCrOutClntTmp "UNM";
BA_ "SignalLongName" SG_ 2154602496 EHCCT_EHtrCrOutClntTmp "Estimated Heater Core Coolant Temperature : Estimated Heater Core Out Coolant Temperature";
BA_ "VNSigAllNodes" SG_ 2154602496 EHCCT_EHtrCrOutClntTmp 1;
BA_ "PacketOrder" SG_ 2154602496 EHCCT_EHtrCrInClntTmp 3;
BA_ "GenSigStartValue" SG_ 2154602496 EHCCT_EHtrCrInClntTmp 619.278406031233;
BA_ "SignalType" SG_ 2154602496 EHCCT_EHtrCrInClntTmp "UNM";
BA_ "SignalLongName" SG_ 2154602496 EHCCT_EHtrCrInClntTmp "Estimated Heater Core Coolant Temperature : Estimated Heater Core In Coolant Temperature";
BA_ "VNSigAllNodes" SG_ 2154602496 EHCCT_EHtrCrInClntTmp 1;
BA_ "PacketOrder" SG_ 2154602496 EHCCT_EHtrCrOutClntTmpV 2;
BA_ "SignalType" SG_ 2154602496 EHCCT_EHtrCrOutClntTmpV "ENM";
BA_ "SignalLongName" SG_ 2154602496 EHCCT_EHtrCrOutClntTmpV "Estimated Heater Core Coolant Temperature : Estimated Heater Core Out Coolant Temperature Validity";
BA_ "VNSigAllNodes" SG_ 2154602496 EHCCT_EHtrCrOutClntTmpV 1;
BA_ "PacketOrder" SG_ 2154602496 EHCCT_EHtrCrInClntTmpV 1;
BA_ "SignalType" SG_ 2154602496 EHCCT_EHtrCrInClntTmpV "ENM";
BA_ "SignalLongName" SG_ 2154602496 EHCCT_EHtrCrInClntTmpV "Estimated Heater Core Coolant Temperature : Estimated Heater Core In Coolant Temperature Validity";
BA_ "VNSigAllNodes" SG_ 2154602496 EHCCT_EHtrCrInClntTmpV 1;
BA_ "SignalType" SG_ 2154602496 EstHtrCrClntFlwrtFdbkV "ENM";
BA_ "SignalLongName" SG_ 2154602496 EstHtrCrClntFlwrtFdbkV "Estimated Heater Core Coolant Flowrate Feedback Validity";
BA_ "VNSigAllNodes" SG_ 2154602496 EstHtrCrClntFlwrtFdbkV 1;
BA_ "SignalType" SG_ 2154602496 EstHtrCrClntFlwrtFdbk "UNM";
BA_ "SignalLongName" SG_ 2154602496 EstHtrCrClntFlwrtFdbk "Estimated Heater Core Coolant Flowrate Feedback";
BA_ "VNSigAllNodes" SG_ 2154602496 EstHtrCrClntFlwrtFdbk 1;
BA_ "SignalType" SG_ 2154602496 CCFrBlwFnSpdFbkRatV "ENM";
BA_ "SignalLongName" SG_ 2154602496 CCFrBlwFnSpdFbkRatV "Climate Control Front Blower Fan Speed Feedback Rationalized Validity";
BA_ "VNSigAllNodes" SG_ 2154602496 CCFrBlwFnSpdFbkRatV 1;
BA_ "SignalType" SG_ 2154602496 CCFrBlwFnSpdFbkRat "UNM";
BA_ "SignalLongName" SG_ 2154602496 CCFrBlwFnSpdFbkRat "Climate Control Front Blower Fan Speed Feedback Rationalized";
BA_ "VNSigAllNodes" SG_ 2154602496 CCFrBlwFnSpdFbkRat 1;
BA_ "SignalType" SG_ 941 DgnInf "UNM";
BA_ "SignalLongName" SG_ 941 DgnInf "Diagnostic Information";
BA_ "VNSigDiagnostic" SG_ 941 DgnInf 1;
BA_ "VNSigAllNodes" SG_ 941 DgnInf 1;
BA_ "SignalType" SG_ 173 DgnInf "UNM";
BA_ "SignalLongName" SG_ 173 DgnInf "Diagnostic Information";
BA_ "VNSigDiagnostic" SG_ 173 DgnInf 1;
BA_ "VNSigAllNodes" SG_ 173 DgnInf 1;
BA_ "SignalType" SG_ 932 DgnInf "UNM";
BA_ "SignalLongName" SG_ 932 DgnInf "Diagnostic Information";
BA_ "VNSigDiagnostic" SG_ 932 DgnInf 1;
BA_ "VNSigAllNodes" SG_ 932 DgnInf 1;
BA_ "SignalType" SG_ 164 DgnInf "UNM";
BA_ "SignalLongName" SG_ 164 DgnInf "Diagnostic Information";
BA_ "VNSigDiagnostic" SG_ 164 DgnInf 1;
BA_ "VNSigAllNodes" SG_ 164 DgnInf 1;
BA_ "GenSigDeltaValue" SG_ 2154684416 HchPntLenExtd 1;
BA_ "GenSigSendType" SG_ 2154684416 HchPntLenExtd 12;
BA_ "SignalType" SG_ 2154684416 HchPntLenExtd "UNM";
BA_ "SignalLongName" SG_ 2154684416 HchPntLenExtd "Hitching Point Length Extended";
BA_ "VNSigAllNodes" SG_ 2154684416 HchPntLenExtd 1;
BA_ "GenSigDeltaValue" SG_ 2154684416 VehHtchHght 1;
BA_ "GenSigSendType" SG_ 2154684416 VehHtchHght 12;
BA_ "SignalType" SG_ 2154684416 VehHtchHght "UNM";
BA_ "SignalLongName" SG_ 2154684416 VehHtchHght "Vehicle Hitch Height";
BA_ "VNSigAllNodes" SG_ 2154684416 VehHtchHght 1;
BA_ "GenSigDeltaValue" SG_ 2154684416 VehHtchLngth 1;
BA_ "GenSigSendType" SG_ 2154684416 VehHtchLngth 12;
BA_ "SignalType" SG_ 2154684416 VehHtchLngth "UNM";
BA_ "SignalLongName" SG_ 2154684416 VehHtchLngth "Vehicle Hitch Length";
BA_ "VNSigAllNodes" SG_ 2154684416 VehHtchLngth 1;
BA_ "GenSigDeltaValue" SG_ 2154684416 TrlrTngLngth 1;
BA_ "GenSigSendType" SG_ 2154684416 TrlrTngLngth 12;
BA_ "SignalType" SG_ 2154684416 TrlrTngLngth "UNM";
BA_ "SignalLongName" SG_ 2154684416 TrlrTngLngth "Trailer Tongue Length";
BA_ "VNSigAllNodes" SG_ 2154684416 TrlrTngLngth 1;
BA_ "GenSigDeltaValue" SG_ 2153906176 ValetModeSpdLimDispVal 1;
BA_ "GenSigSendType" SG_ 2153906176 ValetModeSpdLimDispVal 12;
BA_ "GenSigSendOnInit" SG_ 2153906176 ValetModeSpdLimDispVal 2;
BA_ "SignalType" SG_ 2153906176 ValetModeSpdLimDispVal "UNM";
BA_ "SignalLongName" SG_ 2153906176 ValetModeSpdLimDispVal "Valet Mode Speed Limit Display Value";
BA_ "VNSigAllNodes" SG_ 2153906176 ValetModeSpdLimDispVal 1;
BA_ "GenSigSendType" SG_ 2153906176 ValetModeSpdLimIO 10;
BA_ "GenSigSendOnInit" SG_ 2153906176 ValetModeSpdLimIO 2;
BA_ "SignalType" SG_ 2153906176 ValetModeSpdLimIO "BLN";
BA_ "SignalLongName" SG_ 2153906176 ValetModeSpdLimIO "Valet Mode Speed Limit Indication On";
BA_ "VNSigAllNodes" SG_ 2153906176 ValetModeSpdLimIO 1;
BA_ "GenSigSendType" SG_ 2153906176 ValetModeAccelLimIO 10;
BA_ "GenSigSendOnInit" SG_ 2153906176 ValetModeAccelLimIO 2;
BA_ "SignalType" SG_ 2153906176 ValetModeAccelLimIO "BLN";
BA_ "SignalLongName" SG_ 2153906176 ValetModeAccelLimIO "Valet Mode Acceleration Limit Indication On";
BA_ "VNSigAllNodes" SG_ 2153906176 ValetModeAccelLimIO 1;
BA_ "GenSigSendType" SG_ 2153906176 TDLKARptCrdDspDtAvail 10;
BA_ "GenSigSendOnInit" SG_ 2153906176 TDLKARptCrdDspDtAvail 2;
BA_ "SignalType" SG_ 2153906176 TDLKARptCrdDspDtAvail "BLN";
BA_ "SignalLongName" SG_ 2153906176 TDLKARptCrdDspDtAvail "Teen Driver Lane Keep Assist Report Card Display Data Available";
BA_ "VNSigAllNodes" SG_ 2153906176 TDLKARptCrdDspDtAvail 1;
BA_ "GenSigDeltaValue" SG_ 2153906176 TnDrvLKAEvntsRptDt 1;
BA_ "GenSigSendType" SG_ 2153906176 TnDrvLKAEvntsRptDt 12;
BA_ "GenSigSendOnInit" SG_ 2153906176 TnDrvLKAEvntsRptDt 2;
BA_ "SignalType" SG_ 2153906176 TnDrvLKAEvntsRptDt "UNM";
BA_ "SignalLongName" SG_ 2153906176 TnDrvLKAEvntsRptDt "Teen Driver Lane Keep Assist Events Report Data";
BA_ "VNSigAllNodes" SG_ 2153906176 TnDrvLKAEvntsRptDt 1;
BA_ "GenSigSendType" SG_ 2153906176 TDODDRptCrdDspDtAvail 10;
BA_ "GenSigSendOnInit" SG_ 2153906176 TDODDRptCrdDspDtAvail 2;
BA_ "SignalType" SG_ 2153906176 TDODDRptCrdDspDtAvail "BLN";
BA_ "SignalLongName" SG_ 2153906176 TDODDRptCrdDspDtAvail "Teen Driver Overspeed Distance Driven Report Card Display Data Available";
BA_ "VNSigAllNodes" SG_ 2153906176 TDODDRptCrdDspDtAvail 1;
BA_ "GenSigDeltaValue" SG_ 2153906176 TDOvrspdDstDrvnRpt 1;
BA_ "GenSigSendType" SG_ 2153906176 TDOvrspdDstDrvnRpt 12;
BA_ "GenSigSendOnInit" SG_ 2153906176 TDOvrspdDstDrvnRpt 2;
BA_ "SignalType" SG_ 2153906176 TDOvrspdDstDrvnRpt "UNM";
BA_ "SignalLongName" SG_ 2153906176 TDOvrspdDstDrvnRpt "Teen Driver Overspeed Distance Driven Report";
BA_ "VNSigAllNodes" SG_ 2153906176 TDOvrspdDstDrvnRpt 1;
BA_ "GenSigSendType" SG_ 2153906176 TDUDDRptCrdDspDtAvail 10;
BA_ "GenSigSendOnInit" SG_ 2153906176 TDUDDRptCrdDspDtAvail 2;
BA_ "SignalType" SG_ 2153906176 TDUDDRptCrdDspDtAvail "BLN";
BA_ "SignalLongName" SG_ 2153906176 TDUDDRptCrdDspDtAvail "Teen Driver Unbuckled Distance Driven Report Card Display Data Available";
BA_ "VNSigAllNodes" SG_ 2153906176 TDUDDRptCrdDspDtAvail 1;
BA_ "GenSigDeltaValue" SG_ 2153906176 TDUnbkldDstDrvnRpt 1;
BA_ "GenSigSendType" SG_ 2153906176 TDUnbkldDstDrvnRpt 12;
BA_ "GenSigSendOnInit" SG_ 2153906176 TDUnbkldDstDrvnRpt 2;
BA_ "SignalType" SG_ 2153906176 TDUnbkldDstDrvnRpt "UNM";
BA_ "SignalLongName" SG_ 2153906176 TDUnbkldDstDrvnRpt "Teen Driver Unbuckled Distance Driven Report";
BA_ "VNSigAllNodes" SG_ 2153906176 TDUnbkldDstDrvnRpt 1;
BA_ "GenSigDeltaValue" SG_ 2153906176 BrkSysVTopSpdLimVal 1;
BA_ "GenSigSendType" SG_ 2153906176 BrkSysVTopSpdLimVal 12;
BA_ "SignalType" SG_ 2153906176 BrkSysVTopSpdLimVal "UNM";
BA_ "SignalLongName" SG_ 2153906176 BrkSysVTopSpdLimVal "Braking System Vehicle Top Speed Limit Value";
BA_ "GenSigStartValue" SG_ 2153906176 BrkSysVTopSpdLimVal 255;
BA_ "VNSigAllNodes" SG_ 2153906176 BrkSysVTopSpdLimVal 1;
BA_ "GenSigSendType" SG_ 2153906176 BrkSysVTopSpdLimIO 10;
BA_ "SignalType" SG_ 2153906176 BrkSysVTopSpdLimIO "BLN";
BA_ "SignalLongName" SG_ 2153906176 BrkSysVTopSpdLimIO "Braking System Vehicle Top Speed Limit Indication On";
BA_ "VNSigAllNodes" SG_ 2153906176 BrkSysVTopSpdLimIO 1;
BA_ "GenSigSendType" SG_ 2155978752 OPDWrnIndReq 10;
BA_ "GenSigSendOnInit" SG_ 2155978752 OPDWrnIndReq 2;
BA_ "SignalType" SG_ 2155978752 OPDWrnIndReq "ENM";
BA_ "SignalLongName" SG_ 2155978752 OPDWrnIndReq "One Pedal Driving Warning Indication Request";
BA_ "VNSigAllNodes" SG_ 2155978752 OPDWrnIndReq 1;
BA_ "GenSigSendType" SG_ 2155978752 OPDIndO 10;
BA_ "GenSigSendOnInit" SG_ 2155978752 OPDIndO 2;
BA_ "SignalType" SG_ 2155978752 OPDIndO "BLN";
BA_ "SignalLongName" SG_ 2155978752 OPDIndO "One Pedal Driving Indication On";
BA_ "VNSigAllNodes" SG_ 2155978752 OPDIndO 1;
BA_ "GenSigSendType" SG_ 2155978752 EngAftrRnIndReq 10;
BA_ "SignalType" SG_ 2155978752 EngAftrRnIndReq "ENM";
BA_ "SignalLongName" SG_ 2155978752 EngAftrRnIndReq "Engine After Run Indication Request";
BA_ "VNSigAllNodes" SG_ 2155978752 EngAftrRnIndReq 1;
BA_ "GenSigSendType" SG_ 2155978752 BrkPdLfRrCnfrmReplcmntIO 10;
BA_ "SignalType" SG_ 2155978752 BrkPdLfRrCnfrmReplcmntIO "BLN";
BA_ "SignalLongName" SG_ 2155978752 BrkPdLfRrCnfrmReplcmntIO "Brake Pad Life Rear Confirm Replacement Indication On";
BA_ "VNSigAllNodes" SG_ 2155978752 BrkPdLfRrCnfrmReplcmntIO 1;
BA_ "GenSigSendType" SG_ 2155978752 BrkPdLfFrtCnfrmReplcmntIO 10;
BA_ "SignalType" SG_ 2155978752 BrkPdLfFrtCnfrmReplcmntIO "BLN";
BA_ "SignalLongName" SG_ 2155978752 BrkPdLfFrtCnfrmReplcmntIO "Brake Pad Life Front Confirm Replacement Indication On";
BA_ "VNSigAllNodes" SG_ 2155978752 BrkPdLfFrtCnfrmReplcmntIO 1;
BA_ "GenSigSendType" SG_ 2155978752 ABSActIO 10;
BA_ "SignalType" SG_ 2155978752 ABSActIO "BLN";
BA_ "SignalLongName" SG_ 2155978752 ABSActIO "Antilock Brake System Active Indication On";
BA_ "VNSigAllNodes" SG_ 2155978752 ABSActIO 1;
BA_ "GenSigSendType" SG_ 2155978752 CrwlModeDndRsnIndReq 10;
BA_ "SignalType" SG_ 2155978752 CrwlModeDndRsnIndReq "ENM";
BA_ "SignalLongName" SG_ 2155978752 CrwlModeDndRsnIndReq "Crawl Mode Denied Reason Indication Request";
BA_ "VNSigAllNodes" SG_ 2155978752 CrwlModeDndRsnIndReq 1;
BA_ "GenSigDeltaValue" SG_ 2155978752 BrkPdLfRrDstRmng 1;
BA_ "GenSigSendType" SG_ 2155978752 BrkPdLfRrDstRmng 12;
BA_ "SignalType" SG_ 2155978752 BrkPdLfRrDstRmng "UNM";
BA_ "SignalLongName" SG_ 2155978752 BrkPdLfRrDstRmng "Brake Pad Life Rear Distance Remaining";
BA_ "VNSigAllNodes" SG_ 2155978752 BrkPdLfRrDstRmng 1;
BA_ "GenSigDeltaValue" SG_ 2155978752 BrkPdLfFrtDstRmng 1;
BA_ "GenSigSendType" SG_ 2155978752 BrkPdLfFrtDstRmng 12;
BA_ "SignalType" SG_ 2155978752 BrkPdLfFrtDstRmng "UNM";
BA_ "SignalLongName" SG_ 2155978752 BrkPdLfFrtDstRmng "Brake Pad Life Front Distance Remaining";
BA_ "VNSigAllNodes" SG_ 2155978752 BrkPdLfFrtDstRmng 1;
BA_ "GenSigSendType" SG_ 2155978752 BrkPdLfRrDstWrnIndRq 10;
BA_ "SignalType" SG_ 2155978752 BrkPdLfRrDstWrnIndRq "ENM";
BA_ "SignalLongName" SG_ 2155978752 BrkPdLfRrDstWrnIndRq "Brake Pad Life Rear Distance Warning Indication Request";
BA_ "VNSigAllNodes" SG_ 2155978752 BrkPdLfRrDstWrnIndRq 1;
BA_ "GenSigSendType" SG_ 2155978752 BrkPdLfFrtDstWrnIndRq 10;
BA_ "SignalType" SG_ 2155978752 BrkPdLfFrtDstWrnIndRq "ENM";
BA_ "SignalLongName" SG_ 2155978752 BrkPdLfFrtDstWrnIndRq "Brake Pad Life Front Distance Warning Indication Request";
BA_ "VNSigAllNodes" SG_ 2155978752 BrkPdLfFrtDstWrnIndRq 1;
BA_ "GenSigSendType" SG_ 2155978752 BrkPdLfRrRstAvail 10;
BA_ "SignalType" SG_ 2155978752 BrkPdLfRrRstAvail "BLN";
BA_ "SignalLongName" SG_ 2155978752 BrkPdLfRrRstAvail "Brake Pad Life Rear Reset Available";
BA_ "VNSigAllNodes" SG_ 2155978752 BrkPdLfRrRstAvail 1;
BA_ "GenSigSendType" SG_ 2155978752 BrkPdLfFrtRstAvail 10;
BA_ "SignalType" SG_ 2155978752 BrkPdLfFrtRstAvail "BLN";
BA_ "SignalLongName" SG_ 2155978752 BrkPdLfFrtRstAvail "Brake Pad Life Front Reset Available";
BA_ "VNSigAllNodes" SG_ 2155978752 BrkPdLfFrtRstAvail 1;
BA_ "GenSigSendType" SG_ 2155978752 BrkPdLfRrV 10;
BA_ "SignalType" SG_ 2155978752 BrkPdLfRrV "ENM";
BA_ "SignalLongName" SG_ 2155978752 BrkPdLfRrV "Brake Pad Life Rear Validity";
BA_ "VNSigAllNodes" SG_ 2155978752 BrkPdLfRrV 1;
BA_ "GenSigDeltaValue" SG_ 2155978752 BrkPdLfRr 1;
BA_ "GenSigSendType" SG_ 2155978752 BrkPdLfRr 12;
BA_ "SignalType" SG_ 2155978752 BrkPdLfRr "UNM";
BA_ "SignalLongName" SG_ 2155978752 BrkPdLfRr "Brake Pad Life Rear";
BA_ "VNSigAllNodes" SG_ 2155978752 BrkPdLfRr 1;
BA_ "GenSigSendType" SG_ 2155978752 BrkPdLfFrtV 10;
BA_ "SignalType" SG_ 2155978752 BrkPdLfFrtV "ENM";
BA_ "SignalLongName" SG_ 2155978752 BrkPdLfFrtV "Brake Pad Life Front Validity";
BA_ "VNSigAllNodes" SG_ 2155978752 BrkPdLfFrtV 1;
BA_ "GenSigDeltaValue" SG_ 2155978752 BrkPdLfFrt 1;
BA_ "GenSigSendType" SG_ 2155978752 BrkPdLfFrt 12;
BA_ "SignalType" SG_ 2155978752 BrkPdLfFrt "UNM";
BA_ "SignalLongName" SG_ 2155978752 BrkPdLfFrt "Brake Pad Life Front";
BA_ "VNSigAllNodes" SG_ 2155978752 BrkPdLfFrt 1;
BA_ "GenSigSendType" SG_ 2155978752 BrkPdLfStatIndRq 10;
BA_ "GenSigSendOnInit" SG_ 2155978752 BrkPdLfStatIndRq 2;
BA_ "SignalType" SG_ 2155978752 BrkPdLfStatIndRq "ENM";
BA_ "SignalLongName" SG_ 2155978752 BrkPdLfStatIndRq "Brake Pad Life Status Indication Request";
BA_ "VNSigAllNodes" SG_ 2155978752 BrkPdLfStatIndRq 1;
BA_ "GenSigDeltaValue" SG_ 2155978752 EngAirFltLfRmn 1;
BA_ "GenSigSendType" SG_ 2155978752 EngAirFltLfRmn 12;
BA_ "SignalType" SG_ 2155978752 EngAirFltLfRmn "UNM";
BA_ "SignalLongName" SG_ 2155978752 EngAirFltLfRmn "Engine Air Filter Life Remaining";
BA_ "VNSigAllNodes" SG_ 2155978752 EngAirFltLfRmn 1;
BA_ "GenSigSendType" SG_ 2155978752 EngAirFltMonSt 10;
BA_ "GenSigSendOnInit" SG_ 2155978752 EngAirFltMonSt 2;
BA_ "SignalType" SG_ 2155978752 EngAirFltMonSt "ENM";
BA_ "SignalLongName" SG_ 2155978752 EngAirFltMonSt "Engine Air Filter Monitor Status";
BA_ "VNSigAllNodes" SG_ 2155978752 EngAirFltMonSt 1;
BA_ "GenSigSendType" SG_ 2152013824 SmrtHgBmAstCstSetAvail 10;
BA_ "GenSigSendOnInit" SG_ 2152013824 SmrtHgBmAstCstSetAvail 2;
BA_ "SignalType" SG_ 2152013824 SmrtHgBmAstCstSetAvail "BLN";
BA_ "SignalLongName" SG_ 2152013824 SmrtHgBmAstCstSetAvail "Smart High Beam Assist Customization Setting Available";
BA_ "VNSigAllNodes" SG_ 2152013824 SmrtHgBmAstCstSetAvail 1;
BA_ "GenSigSendType" SG_ 2152013824 SmrtHgBmAstCstCurrSetVal 10;
BA_ "GenSigSendOnInit" SG_ 2152013824 SmrtHgBmAstCstCurrSetVal 2;
BA_ "SignalType" SG_ 2152013824 SmrtHgBmAstCstCurrSetVal "ENM";
BA_ "SignalLongName" SG_ 2152013824 SmrtHgBmAstCstCurrSetVal "Smart High Beam Assist Customization Current Setting Value";
BA_ "VNSigAllNodes" SG_ 2152013824 SmrtHgBmAstCstCurrSetVal 1;
BA_ "GenSigDeltaValue" SG_ 2159255552 ODI_CntrStck2BCM 1;
BA_ "GenSigSendType" SG_ 2159255552 ODI_CntrStck2BCM 12;
BA_ "VNSigInfotainment" SG_ 2159255552 ODI_CntrStck2BCM 1;
BA_ "SignalType" SG_ 2159255552 ODI_CntrStck2BCM "UNM";
BA_ "SignalLongName" SG_ 2159255552 ODI_CntrStck2BCM "Open Display Interface CenterStack 2 BCM";
BA_ "VNSigAllNodes" SG_ 2159255552 ODI_CntrStck2BCM 1;
BA_ "GenSigDeltaValue" SG_ 2159247360 ODI_BCM2CntrStck 1;
BA_ "GenSigSendType" SG_ 2159247360 ODI_BCM2CntrStck 12;
BA_ "VNSigInfotainment" SG_ 2159247360 ODI_BCM2CntrStck 1;
BA_ "SignalType" SG_ 2159247360 ODI_BCM2CntrStck "UNM";
BA_ "SignalLongName" SG_ 2159247360 ODI_BCM2CntrStck "Open Display Interface BCM 2 CenterStack";
BA_ "VNSigAllNodes" SG_ 2159247360 ODI_BCM2CntrStck 1;
BA_ "SignalType" SG_ 104 DgnInf "UNM";
BA_ "SignalLongName" SG_ 104 DgnInf "Diagnostic Information";
BA_ "VNSigDiagnostic" SG_ 104 DgnInf 1;
BA_ "VNSigAllNodes" SG_ 104 DgnInf 1;
BA_ "SignalType" SG_ 88 DgnInf "UNM";
BA_ "SignalLongName" SG_ 88 DgnInf "Diagnostic Information";
BA_ "VNSigDiagnostic" SG_ 88 DgnInf 1;
BA_ "VNSigAllNodes" SG_ 88 DgnInf 1;
BA_ "SignalType" SG_ 96 DgnInf "UNM";
BA_ "SignalLongName" SG_ 96 DgnInf "Diagnostic Information";
BA_ "VNSigDiagnostic" SG_ 96 DgnInf 1;
BA_ "VNSigAllNodes" SG_ 96 DgnInf 1;
BA_ "SignalType" SG_ 169 DgnInf "UNM";
BA_ "SignalLongName" SG_ 169 DgnInf "Diagnostic Information";
BA_ "VNSigDiagnostic" SG_ 169 DgnInf 1;
BA_ "VNSigAllNodes" SG_ 169 DgnInf 1;
BA_ "SignalType" SG_ 937 DgnInf "UNM";
BA_ "SignalLongName" SG_ 937 DgnInf "Diagnostic Information";
BA_ "VNSigDiagnostic" SG_ 937 DgnInf 1;
BA_ "VNSigAllNodes" SG_ 937 DgnInf 1;
BA_REL_ "GenSigSuprvResp" BU_SG_REL_ CSM_LS SG_ 2152079360 BattPrpDstTrvldExtd 1;
BA_REL_ "GenSigSuprvResp" BU_SG_REL_ CGM_LS SG_ 2152079360 BattPrpDstTrvldExtd 1;
BA_REL_ "GenSigSuprvResp" BU_SG_REL_ RadioHead_LS SG_ 2152079360 BattPrpDstTrvldExtd 1;
BA_REL_ "GenSigSuprvResp" BU_SG_REL_ VPM_LS SG_ 2152873984 TrlrApInvTrlrPrvReqd 1;
BA_REL_ "GenSigSuprvResp" BU_SG_REL_ VPM_LS SG_ 2152873984 TrlrApAx2CamPrvReqd 1;
BA_REL_ "GenSigSuprvResp" BU_SG_REL_ VPM_LS SG_ 2152873984 TrlrApAx1CamPrvReqd 1;
BA_REL_ "GenSigSuprvResp" BU_SG_REL_ VPM_LS SG_ 2152873984 TrlrHght 1;
BA_REL_ "GenSigSuprvResp" BU_SG_REL_ VPM_LS SG_ 2152873984 TrlrWdth 1;
BA_REL_ "GenSigSuprvResp" BU_SG_REL_ VPM_LS SG_ 2152873984 TrlrLen 1;
BA_REL_ "GenSigSuprvResp" BU_SG_REL_ VPM_LS SG_ 2152873984 TrlrAxlCnt 1;
BA_REL_ "GenSigSuprvResp" BU_SG_REL_ VPM_LS SG_ 2152873984 TrlrHtchTyp 1;
BA_REL_ "GenSigSuprvResp" BU_SG_REL_ VPM_LS SG_ 2152873984 TrlrTyp 1;
BA_REL_ "GenSigSuprvResp" BU_SG_REL_ VPM_LS SG_ 2152873984 TrlrProfSel 1;
BA_REL_ "GenSigSuprvResp" BU_SG_REL_ VPM_LS SG_ 2152873984 TrlrPrfDltn 1;
BA_REL_ "GenSigSuprvResp" BU_SG_REL_ CSM_LS SG_ 2152792064 Aux2CamConnStat 1;
BA_REL_ "GenSigSuprvResp" BU_SG_REL_ RadioHead_LS SG_ 2152792064 Aux2CamConnStat 1;
BA_REL_ "GenSigSuprvResp" BU_SG_REL_ CSM_LS SG_ 2152792064 Aux1CamConnStat 1;
BA_REL_ "GenSigSuprvResp" BU_SG_REL_ RadioHead_LS SG_ 2152792064 Aux1CamConnStat 1;
BA_REL_ "GenSigSuprvResp" BU_SG_REL_ CSM_LS SG_ 2152792064 InvTrlrAx1CamPlmtFBRll 1;
BA_REL_ "GenSigSuprvResp" BU_SG_REL_ RadioHead_LS SG_ 2152792064 InvTrlrAx1CamPlmtFBRll 1;
BA_REL_ "GenSigSuprvResp" BU_SG_REL_ CSM_LS SG_ 2152792064 InvTrlrAx1CamPlmtFBPtch 1;
BA_REL_ "GenSigSuprvResp" BU_SG_REL_ RadioHead_LS SG_ 2152792064 InvTrlrAx1CamPlmtFBPtch 1;
BA_REL_ "GenSigSuprvResp" BU_SG_REL_ CSM_LS SG_ 2152792064 InvTrlrAx1CamPlmtFBY 1;
BA_REL_ "GenSigSuprvResp" BU_SG_REL_ RadioHead_LS SG_ 2152792064 InvTrlrAx1CamPlmtFBY 1;
BA_REL_ "GenSigSuprvResp" BU_SG_REL_ CSM_LS SG_ 2152792064 InvTrlrAx1CamPlmtFBX 1;
BA_REL_ "GenSigSuprvResp" BU_SG_REL_ RadioHead_LS SG_ 2152792064 InvTrlrAx1CamPlmtFBX 1;
BA_REL_ "GenSigSuprvResp" BU_SG_REL_ CSM_LS SG_ 2152792064 InvTrlrOpnlStat 1;
BA_REL_ "GenSigSuprvResp" BU_SG_REL_ RadioHead_LS SG_ 2152792064 InvTrlrOpnlStat 1;
BA_REL_ "GenSigSuprvResp" BU_SG_REL_ BCM_LS SG_ 2152792064 BRLmpReqd 1;
BA_REL_ "GenSigSuprvResp" BU_SG_REL_ BCM_LS SG_ 2152792064 CargoLmpReqd 1;
BA_REL_ "GenSigSuprvResp" BU_SG_REL_ VICM_LS SG_ 2150694912 TrgtChrgLvlPrctgStReqHme 1;
BA_REL_ "GenSigSuprvResp" BU_SG_REL_ VICM_LS SG_ 2150694912 TrgtChrgLvlPrctgStReq 1;
BA_REL_ "GenSigSuprvResp" BU_SG_REL_ CSM_LS SG_ 2150678528 HVDpltnMdRngPrjtdHme 1;
BA_REL_ "GenSigSuprvResp" BU_SG_REL_ RadioHead_LS SG_ 2150678528 HVDpltnMdRngPrjtdHme 1;
BA_REL_ "GenSigSuprvResp" BU_SG_REL_ CSM_LS SG_ 2150678528 TgtChrgLvlPctgCurStValHme 1;
BA_REL_ "GenSigSuprvResp" BU_SG_REL_ RadioHead_LS SG_ 2150678528 TgtChrgLvlPctgCurStValHme 1;
BA_REL_ "GenSigSuprvResp" BU_SG_REL_ CSM_LS SG_ 2150678528 TrgtChrgLvlPrctgCstCurrStVal 1;
BA_REL_ "GenSigSuprvResp" BU_SG_REL_ RadioHead_LS SG_ 2150678528 TrgtChrgLvlPrctgCstCurrStVal 1;
BA_REL_ "GenSigRxStartValue" BU_SG_REL_ RadioHead_LS SG_ 2150678528 MinTrgtChrgLvlHme "2";
BA_REL_ "GenSigRxStartValue" BU_SG_REL_ RadioHead_LS SG_ 2150678528 MinTrgtChrgLvl "2";
BA_REL_ "GenSigSuprvResp" BU_SG_REL_ CSM_LS SG_ 2150678528 HVDpltnMdRngPrjtd 1;
BA_REL_ "GenSigSuprvResp" BU_SG_REL_ RadioHead_LS SG_ 2150678528 HVDpltnMdRngPrjtd 1;
BA_REL_ "GenSigSuprvResp" BU_SG_REL_ VKM_LS SG_ 2154332160 CrShrngVehChlng 1;
BA_REL_ "GenSigSuprvResp" BU_SG_REL_ VICM_LS SG_ 2150105088 CntStckHMIRdy 1;
BA_REL_ "GenSigSuprvResp" BU_SG_REL_ CSM_LS SG_ 2151194624 TrlrConnCntr 1;
BA_REL_ "GenSigSuprvResp" BU_SG_REL_ VPM_LS SG_ 2151194624 TrlrConnStat 1;
BA_REL_ "GenSigSuprvResp" BU_SG_REL_ CSM_LS SG_ 2151194624 TrlrConnStat 1;
BA_REL_ "GenSigSuprvResp" BU_SG_REL_ MSM_LR_LS SG_ 2153963520 LRStStatDispAct 1;
BA_REL_ "GenSigSuprvResp" BU_SG_REL_ MSM_RR_LS SG_ 2153963520 RRStStatDispAct 1;
BA_REL_ "GenSigSuprvResp" BU_SG_REL_ CSM_LS SG_ 2153832448 EUSE_TtEngyUsgScrAvVal 1;
BA_REL_ "GenSigSuprvResp" BU_SG_REL_ RadioHead_LS SG_ 2153832448 EUSE_TtEngyUsgScrAvVal 1;
BA_REL_ "GenSigSuprvResp" BU_SG_REL_ CSM_LS SG_ 2153832448 EUSE_TrEngyUsgScrAvVal 1;
BA_REL_ "GenSigSuprvResp" BU_SG_REL_ RadioHead_LS SG_ 2153832448 EUSE_TrEngyUsgScrAvVal 1;
BA_REL_ "GenSigSuprvResp" BU_SG_REL_ CSM_LS SG_ 2153832448 EUSE_TcEngyUsgScrAvVal 1;
BA_REL_ "GenSigSuprvResp" BU_SG_REL_ RadioHead_LS SG_ 2153832448 EUSE_TcEngyUsgScrAvVal 1;
BA_REL_ "GenSigSuprvResp" BU_SG_REL_ CSM_LS SG_ 2153832448 EUSE_OTEngyUsgScrAvVal 1;
BA_REL_ "GenSigSuprvResp" BU_SG_REL_ RadioHead_LS SG_ 2153832448 EUSE_OTEngyUsgScrAvVal 1;
BA_REL_ "GenSigSuprvResp" BU_SG_REL_ CSM_LS SG_ 2153832448 EUSE_ITEngyUsgScrAvVal 1;
BA_REL_ "GenSigSuprvResp" BU_SG_REL_ RadioHead_LS SG_ 2153832448 EUSE_ITEngyUsgScrAvVal 1;
BA_REL_ "GenSigSuprvResp" BU_SG_REL_ CSM_LS SG_ 2152144896 DrvCyclFulUsdHiRes 1;
BA_REL_ "GenSigSuprvResp" BU_SG_REL_ RadioHead_LS SG_ 2152144896 DrvCyclFulUsdHiRes 1;
BA_REL_ "GenSigRxStartValue" BU_SG_REL_ TCP_LS SG_ 2152177664 RmtRflshElecPwrRdness "0";
BA_REL_ "GenSigSuprvResp" BU_SG_REL_ TCP_LS SG_ 2152177664 RmtRflshElecPwrRdness 2;
BA_REL_ "GenSigRxStartValue" BU_SG_REL_ ONSTAR_LS SG_ 2152177664 RmtRflshElecPwrRdness "0";
BA_REL_ "GenSigSuprvResp" BU_SG_REL_ ONSTAR_LS SG_ 2152177664 RmtRflshElecPwrRdness 2;
BA_REL_ "GenSigRxStartValue" BU_SG_REL_ CSM_LS SG_ 2152177664 RmtRflshElecPwrRdness "0";
BA_REL_ "GenSigSuprvResp" BU_SG_REL_ CSM_LS SG_ 2152177664 RmtRflshElecPwrRdness 2;
BA_REL_ "GenSigRxStartValue" BU_SG_REL_ RadioHead_LS SG_ 2152177664 RmtRflshElecPwrRdness "0";
BA_REL_ "GenSigSuprvResp" BU_SG_REL_ RadioHead_LS SG_ 2152177664 RmtRflshElecPwrRdness 2;
BA_REL_ "GenSigSuprvResp" BU_SG_REL_ ECC_LS SG_ 2154602496 EHCCT_EHtrCrOutClntTmp 1;
BA_REL_ "GenSigSuprvResp" BU_SG_REL_ ECC_LS SG_ 2154602496 EHCCT_EHtrCrInClntTmp 1;
BA_REL_ "GenSigSuprvResp" BU_SG_REL_ ECC_LS SG_ 2154602496 EHCCT_EHtrCrOutClntTmpV 1;
BA_REL_ "GenSigSuprvResp" BU_SG_REL_ ECC_LS SG_ 2154602496 EHCCT_EHtrCrInClntTmpV 1;
BA_REL_ "GenSigSuprvResp" BU_SG_REL_ ECC_LS SG_ 2154602496 EstHtrCrClntFlwrtFdbk 1;
BA_REL_ "GenSigSuprvResp" BU_SG_REL_ VPM_LS SG_ 2154684416 HchPntLenExtd 1;
BA_REL_ "GenSigSuprvResp" BU_SG_REL_ VPM_LS SG_ 2154684416 VehHtchHght 1;
BA_REL_ "GenSigSuprvResp" BU_SG_REL_ VPM_LS SG_ 2154684416 VehHtchLngth 1;
BA_REL_ "GenSigSuprvResp" BU_SG_REL_ VPM_LS SG_ 2154684416 TrlrTngLngth 1;
BA_REL_ "GenSigVDAFailComment" BU_SG_REL_ IPC_LS SG_ 2155978752 EngAftrRnIndReq "EngVDA";
BA_REL_ "GenSigVDAFailResp" BU_SG_REL_ IPC_LS SG_ 2155978752 EngAftrRnIndReq 1;
BA_REL_ "GenSigSuprvResp" BU_SG_REL_ IPC_LS SG_ 2155978752 EngAftrRnIndReq 1;
BA_REL_ "GenSigVDAFailComment" BU_SG_REL_ CGM_LS SG_ 2155978752 EngAftrRnIndReq "EngVDA";
BA_REL_ "GenSigVDAFailResp" BU_SG_REL_ CGM_LS SG_ 2155978752 EngAftrRnIndReq 1;
BA_REL_ "GenSigSuprvResp" BU_SG_REL_ CGM_LS SG_ 2155978752 EngAftrRnIndReq 1;
BA_REL_ "GenSigSuprvResp" BU_SG_REL_ IPC_LS SG_ 2155978752 BrkPdLfStatIndRq 1;
BA_REL_ "GenSigSuprvResp" BU_SG_REL_ IPC_LS SG_ 2155978752 EngAirFltMonSt 1;
VAL_ 2152873984 TrlrProfSelV 1 "Invalid" 0 "Valid" ;
VAL_ 2152873984 TrlrApInvTrlrPrvReqd 1 "true" 0 "false" ;
VAL_ 2152873984 TrlrApAx2CamPrvReqd 1 "true" 0 "false" ;
VAL_ 2152873984 TrlrApAx1CamPrvReqd 1 "true" 0 "false" ;
VAL_ 2152873984 TrlrAxlCnt 3 "3" 2 "2" 1 "1" 0 "Unknown" ;
VAL_ 2152873984 TrlrHtchTyp 3 "Gooseneck" 2 "5th Wheel" 1 "Conventional" 0 "Unknown" ;
VAL_ 2152873984 TrlrTyp 2 "Not Box" 1 "Box" 0 "Unknown" ;
VAL_ 2152873984 TrlrProfSel 5 "Profile 5" 4 "Profile 4" 3 "Profile 3" 2 "Profile 2" 1 "Profile 1" 0 "Default Profile" ;
VAL_ 2152873984 TrlrPrfDltn 5 "Profile 5 Deleted" 4 "Profile 4 Deleted" 3 "Profile 3 Deleted" 2 "Profile 2 Deleted" 1 "Profile 1 Deleted" 0 "No Profile Deleted" ;
VAL_ 2152792064 Aux2CamConnStat 0 "Not Connected" 2 "Unknown" 1 "Connected" ;
VAL_ 2152792064 Aux1CamConnStat 2 "Unknown" 1 "Connected" 0 "Not Connected" ;
VAL_ 2152792064 InvTrlrOpnlStat 3 "Unavailable" 2 "Degraded" 1 "Available" 0 "Unknown" ;
VAL_ 2152792064 BRLmpReqd 1 "true" 0 "false" ;
VAL_ 2152792064 CargoLmpReqd 1 "true" 0 "false" ;
VAL_ 2154610688 ClnScrnAct 1 "true" 0 "false" ;
VAL_ 2150924288 PrkHtrActvTmM 1 "Use Data" 0 "Dont Use Data" ;
VAL_ 2150924288 PrkHtrOffTmM 1 "Use Data" 0 "Dont Use Data" ;
VAL_ 2152062976 ThrmlRefCompStatFdbck 3 "Invalid" 2 "Inoperative" 1 "Degraded Operation" 0 "Normal Operation" ;
VAL_ 2155503616 ChrgStatChrngScnActIndOn 1 "true" 0 "false" ;
VAL_ 2155503616 EleRngEstAdjStat 3 "Ununsed and Reserved 1" 2 "Decrease" 1 "Increase" 0 "No Action" ;
VAL_ 2155503616 EleRngEstAdjCstCurrStVal 3 "Unused and Reserved 1" 2 "On" 1 "Off" 0 "No Action" ;
VAL_ 2155503616 EleRngEstAdjCstStAvail 1 "true" 0 "false" ;
VAL_ 2155503616 WPRSCstCurrStVal 7 "Unused and Reserved 5" 6 "Unused and Reserved 4" 5 "Unused and Reserved 3" 4 "Unused and Reserved 2" 3 "Unused and Reserved 1" 2 "On" 1 "Off" 0 "No Action" ;
VAL_ 2155503616 WPRSCstStAvail 1 "true" 0 "false" ;
VAL_ 2153406464 RrClsrInrAjrSwAct 1 "true" 0 "false" ;
VAL_ 2153406464 TlgtUnavlbleIO 1 "true" 0 "false" ;
VAL_ 2154217472 CSRCR_Cmnd 7 "Unused And Reserved 5" 6 "Unused And Reserved 4" 5 "Unused And Reserved 3" 4 "Unused And Reserved 2" 3 "Unused And Reserved 1" 2 "Revoke All Certificates" 1 "Revoke Certificate" 0 "No Action" ;
VAL_ 2154217472 CrShrngFbsEnblReq 7 "Unused And Reserved 5" 6 "Unused And Reserved 4" 5 "Unused And Reserved 3" 4 "Unused And Reserved 2" 3 "Return Status" 2 "Unused And Reserved 1" 1 "Disable Fobs" 0 "No Action" ;
VAL_ 2150121472 RmtTrlrLtngSeqReq 2 "On" 1 "Off" 0 "No Action" ;
VAL_ 2150105088 CntStckHMIRdy 3 "Unused and Reserved 1" 2 "HMI Not Ready" 1 "HMI Ready" 0 "No Action" ;
VAL_ 2150105088 TrlrLtngSeqReq 2 "On" 1 "Off" 0 "No Action" ;
VAL_ 2150105088 TrlrLghtAlrtEnbld 1 "true" 0 "false" ;
VAL_ 2150105088 TrlRvsLghtFldEnbld 1 "true" 0 "false" ;
VAL_ 2150105088 TrlrThftAlrtEnbld 1 "true" 0 "false" ;
VAL_ 2151194624 TrlrThftIndOn 1 "true" 0 "false" ;
VAL_ 2151194624 TrlrPwrSplyLdPrsnt 1 "true" 0 "false" ;
VAL_ 2151194624 TrlrDisconndIndOn 1 "true" 0 "false" ;
VAL_ 2151194624 TrlrConnStat 1 "Connected" 0 "Not Connected" ;
VAL_ 2153963520 USBProgInPrgrs_317 1 "true" 0 "false" ;
VAL_ 2153963520 RSIHMIAnmSt 7 "Unused and Reserved 3" 6 "Unused and Reserved 2" 5 "Unused and Reserved 1" 4 "Shutdown Play" 3 "Start Play" 2 "Welcome Play" 1 "Ready" 0 "Uninitialized" ;
VAL_ 2153963520 RSIHMIRdy 1 "true" 0 "false" ;
VAL_ 2153963520 LRStStatDispAct 1 "true" 0 "false" ;
VAL_ 2153963520 RRStStatDispAct 1 "true" 0 "false" ;
VAL_ 2154602496 EHCCT_EHtrCrOutClntTmpV 1 "Invalid" 0 "Valid" ;
VAL_ 2154602496 EHCCT_EHtrCrInClntTmpV 1 "Invalid" 0 "Valid" ;
VAL_ 2154602496 EstHtrCrClntFlwrtFdbkV 1 "Invalid" 0 "Valid" ;
VAL_ 2154602496 CCFrBlwFnSpdFbkRatV 1 "Invalid" 0 "Valid" ;
VAL_ 2153906176 ValetModeSpdLimIO 1 "true" 0 "false" ;
VAL_ 2153906176 ValetModeAccelLimIO 1 "true" 0 "false" ;
VAL_ 2153906176 TDLKARptCrdDspDtAvail 1 "true" 0 "false" ;
VAL_ 2153906176 TDODDRptCrdDspDtAvail 1 "true" 0 "false" ;
VAL_ 2153906176 TDUDDRptCrdDspDtAvail 1 "true" 0 "false" ;
VAL_ 2153906176 BrkSysVTopSpdLimIO 1 "true" 0 "false" ;
VAL_ 2155978752 OPDWrnIndReq 4 "Forced Exit" 3 "Unavailable" 2 "Off" 1 "On" 0 "No Indication" ;
VAL_ 2155978752 OPDIndO 1 "true" 0 "false" ;
VAL_ 2155978752 EngAftrRnIndReq 7 "Unused and Reserved 3" 6 "Unused and Reserved 2" 5 "Unused and Reserved 1" 4 "Interrupted" 3 "Overheated" 2 "Idle Needed" 1 "No Indication" 0 "No Action" ;
VAL_ 2155978752 BrkPdLfRrCnfrmReplcmntIO 1 "true" 0 "false" ;
VAL_ 2155978752 BrkPdLfFrtCnfrmReplcmntIO 1 "true" 0 "false" ;
VAL_ 2155978752 ABSActIO 1 "true" 0 "false" ;
VAL_ 2155978752 CrwlModeDndRsnIndReq 4 "Reduce Speed" 3 "Shift To 4 High" 2 "Brakes Overtemp" 1 "Unavailable" 0 "No Action" ;
VAL_ 2155978752 BrkPdLfRrDstWrnIndRq 2 "Display Distance" 1 "Low" 0 "No Action" ;
VAL_ 2155978752 BrkPdLfFrtDstWrnIndRq 2 "Display Distance" 1 "Low" 0 "No Action" ;
VAL_ 2155978752 BrkPdLfRrRstAvail 1 "true" 0 "false" ;
VAL_ 2155978752 BrkPdLfFrtRstAvail 1 "true" 0 "false" ;
VAL_ 2155978752 BrkPdLfRrV 1 "Invalid" 0 "Valid" ;
VAL_ 2155978752 BrkPdLfFrtV 1 "Invalid" 0 "Valid" ;
VAL_ 2155978752 BrkPdLfStatIndRq 5 "Service" 4 "Disabled" 3 "Change Now" 2 "Change Soon" 1 "Ok" 0 "Not Present" ;
VAL_ 2155978752 EngAirFltMonSt 7 "Unused and Reserved 3" 6 "Unused and Reserved 2" 5 "Unused and Reserved 1" 4 "Disabled" 3 "Fault Present" 2 "Replace Air Filter Now" 1 "Replace Air Filter Soon" 0 "Ok" ;
VAL_ 2152013824 SmrtHgBmAstCstSetAvail 1 "true" 0 "false" ;
VAL_ 2152013824 SmrtHgBmAstCstCurrSetVal 7 "Unused and Reserved 5" 6 "Unused and Reserved 4" 5 "Unused and Reserved 3" 4 "Unused and Reserved 2" 3 "Unused and Reserved 1" 2 "Adaptive High Beam" 1 "Auto High Beam" 0 "No Action" ;
SIG_GROUP_ 2155503616 OBHCDCCCpltTm 1 : OBHVDCCT_MinOfHr OBHVDCCT_HrOfDay OBHVDCCT_DayOfWk;
SIG_GROUP_ 2154217472 CrShrngRvkCertfctRq 1 : CSRCR_CrtfctIdntfcn CSRCR_Cmnd;
SIG_GROUP_ 2153848832 EngyUsgScrScalExtd 1 : EUSSE_MaxBarDspRng EUSSE_ITEgUgScrMxScVal EUSSE_TrEgUgScrMxScVal EUSSE_TcEgUgScrMxScVal EUSSE_OTEgUgScrMxScVal EUSSE_TrEgUgScrMnScVal EUSSE_TcEgUgScrMnScVal EUSSE_OTEgUgScrMnScVal EUSSE_ITEgUgScrMnScVal;
SIG_GROUP_ 2153832448 EngyUsgScrExtd 1 : EUSE_TtEngyUsgScrAvVal EUSE_TrEngyUsgScrAvVal EUSE_TcEngyUsgScrAvVal EUSE_OTEngyUsgScrAvVal EUSE_ITEngyUsgScrAvVal;
SIG_GROUP_ 2154602496 EstHtrCorClntTemp 1 : EHCCT_EHtrCrOutClntTmp EHCCT_EHtrCrInClntTmp EHCCT_EHtrCrOutClntTmpV EHCCT_EHtrCrInClntTmpV;
